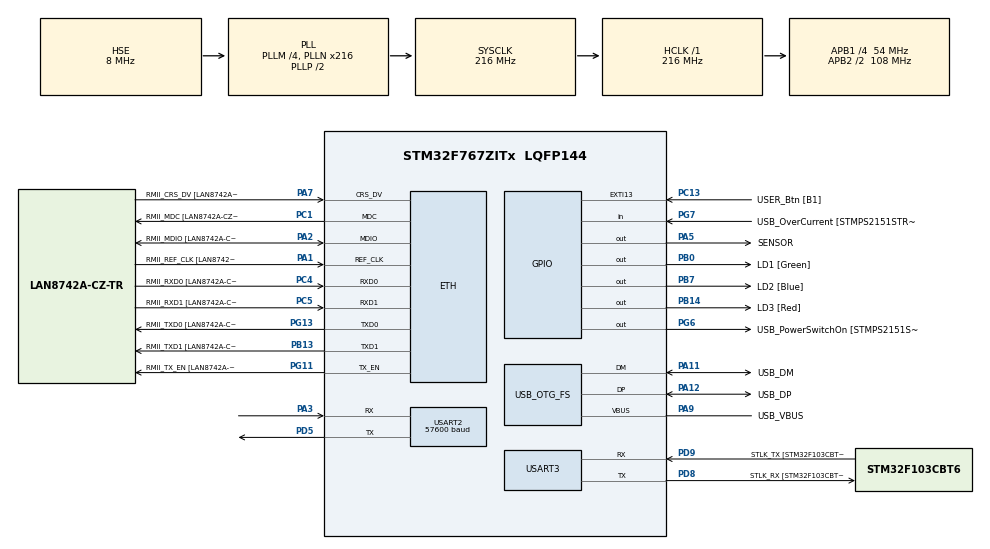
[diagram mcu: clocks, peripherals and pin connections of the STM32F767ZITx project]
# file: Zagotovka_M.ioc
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CORTEX_M7.AccessPermission-Cortex_Memory_Protection_Unit_Region0_Settings=MPU_REGION_FULL_ACCESS
CORTEX_M7.BaseAddress-Cortex_Memory_Protection_Unit_Region0_Settings=0x20000000
CORTEX_M7.CPU_DCache=Enabled
CORTEX_M7.CPU_ICache=Enabled
CORTEX_M7.DisableExec-Cortex_Memory_Protection_Unit_Region0_Settings=MPU_INSTRUCTION_ACCESS_DISABLE
CORTEX_M7.Enable-Cortex_Memory_Protection_Unit_Region0_Settings=MPU_REGION_ENABLE
CORTEX_M7.IsShareable-Cortex_Memory_Protection_Unit_Region0_Settings=MPU_ACCESS_NOT_SHAREABLE
CORTEX_M7.MPU_Control=MPU_PRIVILEGED_DEFAULT
CORTEX_M7.Size-Cortex_Memory_Protection_Unit_Region0_Settings=MPU_REGION_SIZE_512KB
CORTEX_M7.TypeExtField-Cortex_Memory_Protection_Unit_Region0_Settings=MPU_TEX_LEVEL1
ETH.MediaInterface=HAL_ETH_RMII_MODE
ETH.PHY_Name=LAN8742A_PHY_ADDRESS
ETH.PHY_Value=0
ETH.PhyAddress=0
FATFS._MAX_SS=4096
FREERTOS.Mutexes01=actionMutexHandle,Dynamic,NULL;s_mysett_mutex,Dynamic,NULL
FREERTOS.Queues01=outputQueue,64,struct data_pin_t,0,Dynamic,NULL,NULL;usbQueue,16,uint8_t,0,Dynamic,NULL,NULL;mqttQueue,32,MqttMessage_t,0,Dynamic,NULL,NULL;mqttRxQueue,32,MqttRxMsg_t,0,Dynamic,NULL,NULL;zbeeCmdQueue,64,ZbeeCmdMsg_t,0,Dynamic,NULL,NULL
FREERTOS.Tasks01=ConfigTask,24,768,StartConfigTask,Default,NULL,Dynamic,NULL,NULL;OutputTask,24,512,StartOutputTask,Default,NULL,Dynamic,NULL,NULL;CronTask,24,512,StartCronTask,Default,NULL,Dynamic,NULL,NULL;InputTask,24,512,StartInputTask,Default,NULL,Dynamic,NULL,NULL;EncoderTask,24,512,StartEncoderTask,Default,NULL,Dynamic,NULL,NULL;ds18b20Task,32,768,StartDs18b20Task,Default,NULL,Dynamic,NULL,NULL;dht22Task,24,512,StartDht22Task,Default,NULL,Dynamic,NULL,NULL;ServiceTask,24,1024,StartServiceTask,Default,NULL,Dynamic,NULL,NULL;SIM800LTask,24,1024,StartSIM800LTask,Default,NULL,Dynamic,NULL,NULL;SecurityTask,24,1024,StartSecurityTask,Default,NULL,Dynamic,NULL,NULL;PIDTask,24,1024,StartPIDTask,Default,NULL,Dynamic,NULL,NULL;my_DgnTask,24,768,StartDgnTask,Default,NULL,Dynamic,NULL,NULL;LoggerTask,16,512,StartLoggerTask,Default,NULL,Dynamic,NULL,NULL
FREERTOS.configTOTAL_HEAP_SIZE=192512
FREERTOS.configUSE_NEWLIB_REENTRANT=1
Mcu.Family=STM32F7
Mcu.Name=STM32F767ZITx
Mcu.Package=LQFP144
NVIC.ETH_IRQn=true\:5\:0\:false\:false\:true\:true\:true\:true\:true
NVIC.OTG_FS_IRQn=true\:5\:0\:false\:false\:true\:true\:true\:true\:true
NVIC.PriorityGroup=NVIC_PRIORITYGROUP_4
NVIC.TIM6_DAC_IRQn=true\:15\:0\:false\:false\:true\:false\:false\:true\:true
NVIC.TimeBase=TIM6_DAC_IRQn
NVIC.TimeBaseIP=TIM6
NVIC.USART2_IRQn=true\:5\:0\:false\:false\:true\:true\:true\:true\:true
PA1.GPIO_Label=RMII_REF_CLK [LAN8742A-CZ-TR_REFCLK0]
PA1.Mode=RMII
PA1.Signal=ETH_REF_CLK
PA10.GPIO_Label=USB_ID
PA10.Signal=USB_OTG_FS_ID
PA11.GPIO_Label=USB_DM
PA11.Mode=Host_Only
PA11.Signal=USB_OTG_FS_DM
PA12.GPIO_Label=USB_DP
PA12.Mode=Host_Only
PA12.Signal=USB_OTG_FS_DP
PA13.GPIO_Label=TMS
PA13.Mode=Trace_Asynchronous_SW
PA13.Signal=SYS_JTMS-SWDIO
PA14.GPIO_Label=TCK
PA14.Mode=Trace_Asynchronous_SW
PA14.Signal=SYS_JTCK-SWCLK
PA2.GPIO_Label=RMII_MDIO [LAN8742A-CZ-TR_MDIO]
PA2.Mode=RMII
PA2.Signal=ETH_MDIO
PA3.Mode=Asynchronous
PA3.Signal=USART2_RX
PA5.GPIO_Label=SENSOR
PA5.Signal=GPIO_Output
PA7.GPIO_Label=RMII_CRS_DV [LAN8742A-CZ-TR_CRS_DV]
PA7.Mode=RMII
PA7.Signal=ETH_CRS_DV
PA8.GPIO_Label=USB_SOF [TP1]
PA8.Signal=USB_OTG_FS_SOF
PA9.GPIO_Label=USB_VBUS
PA9.Mode=Activate_VBUS
PA9.Signal=USB_OTG_FS_VBUS
PB0.GPIO_Label=LD1 [Green]
PB0.Signal=GPIO_Output
PB13.GPIO_Label=RMII_TXD1 [LAN8742A-CZ-TR_TXD1]
PB13.Mode=RMII
PB13.Signal=ETH_TXD1
PB14.GPIO_Label=LD3 [Red]
PB14.Signal=GPIO_Output
PB3.GPIO_Label=SWO
PB3.Mode=Trace_Asynchronous_SW
PB3.Signal=SYS_JTDO-SWO
PB7.GPIO_Label=LD2 [Blue]
PB7.Signal=GPIO_Output
PC1.GPIO_Label=RMII_MDC [LAN8742A-CZ-TR_MDC]
PC1.Mode=RMII
PC1.Signal=ETH_MDC
PC13.GPIO_Label=USER_Btn [B1]
PC13.Signal=GPXTI13
PC14/OSC32_IN.Mode=LSE-External-Oscillator
PC14/OSC32_IN.Signal=RCC_OSC32_IN
PC15/OSC32_OUT.Mode=LSE-External-Oscillator
PC15/OSC32_OUT.Signal=RCC_OSC32_OUT
PC4.GPIO_Label=RMII_RXD0 [LAN8742A-CZ-TR_RXD0]
PC4.Mode=RMII
PC4.Signal=ETH_RXD0
PC5.GPIO_Label=RMII_RXD1 [LAN8742A-CZ-TR_RXD1]
PC5.Mode=RMII
PC5.Signal=ETH_RXD1
PD5.Mode=Asynchronous
PD5.Signal=USART2_TX
PD8.GPIO_Label=STLK_RX [STM32F103CBT6_PA3]
PD8.Mode=Asynchronous
PD8.Signal=USART3_TX
PD9.GPIO_Label=STLK_TX [STM32F103CBT6_PA2]
PD9.Mode=Asynchronous
PD9.Signal=USART3_RX
PG11.GPIO_Label=RMII_TX_EN [LAN8742A-CZ-TR_TXEN]
PG11.Mode=RMII
PG11.Signal=ETH_TX_EN
PG13.GPIO_Label=RMII_TXD0 [LAN8742A-CZ-TR_TXD0]
PG13.Mode=RMII
PG13.Signal=ETH_TXD0
PG6.GPIO_Label=USB_PowerSwitchOn [STMPS2151STR_EN]
PG6.Signal=GPIO_Output
PG7.GPIO_Label=USB_OverCurrent [STMPS2151STR_FAULT]
PG7.Signal=GPIO_Input
PH0/OSC_IN.GPIO_Label=MCO [STM32F103CBT6_PA8]
PH0/OSC_IN.Mode=HSE-External-Clock-Source
PH0/OSC_IN.Signal=RCC_OSC_IN
PH1/OSC_OUT.Mode=HSE-External-Clock-Source
PH1/OSC_OUT.Signal=RCC_OSC_OUT
ProjectManager.HeapSize=0x1000
ProjectManager.StackSize=0x800
ProjectManager.TargetToolchain=STM32CubeIDE
RCC.48MHZClocksFreq_Value=24000000
RCC.AHBFreq_Value=216000000
RCC.APB1CLKDivider=RCC_HCLK_DIV4
RCC.APB1Freq_Value=54000000
RCC.APB1TimFreq_Value=108000000
RCC.APB2CLKDivider=RCC_HCLK_DIV2
RCC.APB2Freq_Value=108000000
RCC.APB2TimFreq_Value=216000000
RCC.CortexFreq_Value=216000000
RCC.HCLKFreq_Value=216000000
RCC.HSE_VALUE=8000000
RCC.HSI_VALUE=16000000
RCC.PLLM=4
RCC.PLLMUL=RCC_PLL_MUL9
RCC.PLLN=216
RCC.PLLQ=9
RCC.PRESCALERUSB=RCC_USBCLKSOURCE_PLL_DIV1_5
RCC.SYSCLKFreq_VALUE=216000000
RCC.SYSCLKSource=RCC_SYSCLKSOURCE_PLLCLK
RCC.SYSCLKSourceVirtual=RCC_SYSCLKSOURCE_PLLCLK
RCC.USBFreq_Value=48000000
RCC.VCOOutputFreq_Value=432000000
TIM1.Prescaler=216-1
USART2.BaudRate=57600
USART2.VirtualMode-Asynchronous=VM_ASYNC
USART3.VirtualMode-Asynchronous=VM_ASYNC
USB_HOST.BSP.number=1
USB_HOST.USBH_HandleTypeDef-MSC_FS=hUsbHostFS
USB_HOST.USBH_PROCESS_STACK_SIZE-MSC_FS=8*128
USB_HOST.VirtualModeFS=Msc
USB_HOST0.BSP.STBoard=false
USB_HOST0.BSP.api=Unknown
USB_HOST0.BSP.condition=SW_VBUS_DRIVE_MSC_FS \= false
USB_HOST0.BSP.instance=PG6
USB_HOST0.BSP.ip=GPIO
USB_HOST0.BSP.mode=Output
USB_HOST0.BSP.name=Drive_VBUS_FS
USB_HOST0.BSP.solution=PG6
USB_OTG_FS.VirtualMode=Host_Only
USB_OTG_FS.phy_itface=HCD_PHY_EMBEDDED
VP_CRC_VS_CRC.Mode=CRC_Activate
VP_FATFS_VS_USB.Mode=USB
VP_FREERTOS_VS_CMSIS_V2.Mode=CMSIS_V2
VP_RNG_VS_RNG.Mode=RNG_Activate
VP_SYS_VS_tim6.Mode=TIM6
VP_TIM1_VS_ClockSourceINT.Mode=Internal
VP_USB_HOST_VS_USB_HOST_MSC_FS.Mode=MSC_FS
board=NUCLEO-F767ZI

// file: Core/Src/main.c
/* USER CODE BEGIN Header */
/**
 ******************************************************************************
 * @file           : main.c
 * @brief          : Main program body
 ******************************************************************************
 * @attention
 *
 * Copyright (c) 2024 STMicroelectronics.
 * All rights reserved.
 *
 * This software is licensed under terms that can be found in the LICENSE file
 * in the root directory of this software component.
 * If no LICENSE file comes with this software, it is provided AS-IS.
 *
 ******************************************************************************
 */
/* USER CODE END Header */
#include "main.h"
#include "string.h"
#include "cmsis_os.h"
#include "fatfs.h"
#include "usb_host.h"

/* USER CODE BEGIN Includes */
#include "db.h"
#include "hal.h"
#include "mongoose.h"
#include "multi_button.h"
#include "net.h"
#include "net_limits.h"  /* g_net_syn_drops / g_net_rejects */
#include "setings.h"
#include "logger.h"
#include "ds18b20.h"
#include "ds18b20Config.h"
#include "lwdtc.h"
#include "mongoose.h"
#include "stdio.h"
#include "zagotovka.h"
#include <inttypes.h> // Для поддержки PRIuPTR
#include <math.h>
#include <string.h>
#include <time.h>

#include "gsm.h"
#include "usart_ring.h"
#include "dtcm_alloc.h"
#include "mqtt_server.h"
#include "ha_discovery.h"
#include "slzb_watchdog.h"
#include "cond_eval.h" /* Дополнительные условия срабатывания действий */

#define BLINK_PERIOD_MS 1000 // LED blinking period in millis
#define DEBOUNCE_DELAY 45    // Encoder (ms)

#define PI 3.14159265358979323846
#define ZENITH -.83 // Средняя атмосферная рефракция.

extern OneWire_t OneWire;
extern uint8_t OneWireDevices;
extern uint8_t temp_cnt;
extern uint8_t Ds18b20StartConvert;
extern uint16_t Ds18b20Timeout;
extern uint64_t s_boot_timestamp;
int32_t onoffid;  /* знаковый: JSON id может быть < 0 */
extern onewire_config_t *ow_conf;  /* выделяется в DTCM в zagotovka_dtcm_init() */
struct Button *button = NULL;      /* выделяется в DTCM через dtcm_button (main) */
extern volatile uint8_t onlineFlg;
extern uint8_t *gsm_rx_buffer;
extern volatile gsm_rx_buffer_index_t gsm_rx_buffer_head;
extern uint8_t _sitcm[], _eitcm[];
extern uint32_t _sitcm_load[];
uint8_t RxByte; // Буфер для приема одного байта по UART

uint8_t owflag = 0;

ds18b20_pin_t ds18b20[MAX_DS18B20_P];
dht22_pin_t *dht22 = NULL;         /* выделяется в DTCM через dtcm_dht22 (main) */

/* A4: global mqttMsg removed — each send site uses a local copy */
/* mqtt_topic[100] / mqtt_payload[300] теперь локальны в WebServerTask */
/* USER CODE END Includes */

/* USER CODE BEGIN PTD */
TIM_HandleTypeDef *htim = NULL;  /* выделяется в DTCM через dtcm_htim (main) */
uint8_t usbnum = 0;
uint8_t mqttnum = 0;
uint8_t sumowpin = 0;
/* A3: global data_pin removed — each producer/consumer uses a local copy */
dbPidConf *PidConf = NULL;  /* выделяется в DTCM через dtcm_pid_conf */

#define HTTP_URL "http://0.0.0.0:8000"
#define HTTPS_URL "https://0.0.0.0:8443"
/* USER CODE END PTD */

/* USER CODE BEGIN PM */
// Cron variable — копия struct tm, а не указатель на static buffer localtime()
struct tm timez_copy;
time_t cronetime;
time_t cronetime_old;
time_t moontime = (time_t)-1;
int year;
uint8_t month; // 1-12
uint8_t day;   // 1-31
char g_ip_addr[16] = "0.0.0.0";
char g_mac_addr[18] = "00:00:00:00:00:00";
/* USER CODE END PM */

#if defined ( __ICCARM__ ) /*!< IAR Compiler */
#pragma location=0x2007c000
ETH_DMADescTypeDef  DMARxDscrTab[ETH_RX_DESC_CNT]; /* Ethernet Rx DMA Descriptors */
#pragma location=0x2007c0a0
ETH_DMADescTypeDef  DMATxDscrTab[ETH_TX_DESC_CNT]; /* Ethernet Tx DMA Descriptors */

#elif defined ( __CC_ARM )  /* MDK ARM Compiler */

__attribute__((at(0x2007c000))) ETH_DMADescTypeDef  DMARxDscrTab[ETH_RX_DESC_CNT]; /* Ethernet Rx DMA Descriptors */
__attribute__((at(0x2007c0a0))) ETH_DMADescTypeDef  DMATxDscrTab[ETH_TX_DESC_CNT]; /* Ethernet Tx DMA Descriptors */

#elif defined ( __GNUC__ ) /* GNU Compiler */

ETH_DMADescTypeDef DMARxDscrTab[ETH_RX_DESC_CNT] __attribute__((section(".RxDecripSection"))); /* Ethernet Rx DMA Descriptors */
ETH_DMADescTypeDef DMATxDscrTab[ETH_TX_DESC_CNT] __attribute__((section(".TxDecripSection")));   /* Ethernet Tx DMA Descriptors */
#endif

ETH_TxPacketConfig TxConfig;

CRC_HandleTypeDef hcrc;

ETH_HandleTypeDef heth;

RNG_HandleTypeDef hrng;

TIM_HandleTypeDef htim1;

UART_HandleTypeDef huart2;
UART_HandleTypeDef huart3;

/* Definitions for ConfigTask */
osThreadId_t ConfigTaskHandle;
const osThreadAttr_t ConfigTask_attributes = {
  .name = "ConfigTask",
  .stack_size = 768 * 4,
  .priority = (osPriority_t) osPriorityNormal,
};
/* Definitions for OutputTask */
osThreadId_t OutputTaskHandle;
const osThreadAttr_t OutputTask_attributes = {
  .name = "OutputTask",
  .stack_size = 512 * 4,
  .priority = (osPriority_t) osPriorityNormal,
};
/* Definitions for CronTask */
osThreadId_t CronTaskHandle;
const osThreadAttr_t CronTask_attributes = {
  .name = "CronTask",
  .stack_size = 512 * 4,
  .priority = (osPriority_t) osPriorityNormal,
};
/* Definitions for InputTask */
osThreadId_t InputTaskHandle;
const osThreadAttr_t InputTask_attributes = {
  .name = "InputTask",
  .stack_size = 512 * 4,
  .priority = (osPriority_t) osPriorityNormal,
};
/* Definitions for EncoderTask */
osThreadId_t EncoderTaskHandle;
const osThreadAttr_t EncoderTask_attributes = {
  .name = "EncoderTask",
  .stack_size = 512 * 4,
  .priority = (osPriority_t) osPriorityNormal,
};
/* Definitions for ds18b20Task */
osThreadId_t ds18b20TaskHandle;
const osThreadAttr_t ds18b20Task_attributes = {
  .name = "ds18b20Task",
  .stack_size = 768 * 4,
  .priority = (osPriority_t) osPriorityAboveNormal,
};
/* Definitions for dht22Task */
osThreadId_t dht22TaskHandle;
const osThreadAttr_t dht22Task_attributes = {
  .name = "dht22Task",
  .stack_size = 512 * 4,
  .priority = (osPriority_t) osPriorityNormal,
};
/* Definitions for ServiceTask */
osThreadId_t ServiceTaskHandle;
const osThreadAttr_t ServiceTask_attributes = {
  .name = "ServiceTask",
  .stack_size = 1024 * 4,
  .priority = (osPriority_t) osPriorityNormal,
};
/* Definitions for SIM800LTask */
osThreadId_t SIM800LTaskHandle;
const osThreadAttr_t SIM800LTask_attributes = {
  .name = "SIM800LTask",
  .stack_size = 1024 * 4,
  .priority = (osPriority_t) osPriorityNormal,
};
/* Definitions for SecurityTask */
osThreadId_t SecurityTaskHandle;
const osThreadAttr_t SecurityTask_attributes = {
  .name = "SecurityTask",
  .stack_size = 1024 * 4,
  .priority = (osPriority_t) osPriorityNormal,
};
/* Definitions for PIDTask */
osThreadId_t PIDTaskHandle;
const osThreadAttr_t PIDTask_attributes = {
  .name = "PIDTask",
  .stack_size = 1024 * 4,
  .priority = (osPriority_t) osPriorityNormal,
};
/* Definitions for my_DgnTask */
osThreadId_t my_DgnTaskHandle;
const osThreadAttr_t my_DgnTask_attributes = {
  .name = "my_DgnTask",
  .stack_size = 768 * 4,
  .priority = (osPriority_t) osPriorityNormal,
};
/* Definitions for LoggerTask */
osThreadId_t LoggerTaskHandle;
const osThreadAttr_t LoggerTask_attributes = {
  .name = "LoggerTask",
  .stack_size = 512 * 4,
  .priority = (osPriority_t) osPriorityBelowNormal,
};
/* Definitions for outputQueue */
osMessageQueueId_t outputQueueHandle;
const osMessageQueueAttr_t outputQueue_attributes = {
  .name = "outputQueue"
};
/* Definitions for usbQueue */
osMessageQueueId_t usbQueueHandle;
const osMessageQueueAttr_t usbQueue_attributes = {
  .name = "usbQueue"
};
/* Definitions for mqttQueue */
osMessageQueueId_t mqttQueueHandle;
const osMessageQueueAttr_t mqttQueue_attributes = {
  .name = "mqttQueue"
};
/* Definitions for mqttRxQueue */
osMessageQueueId_t mqttRxQueueHandle;
const osMessageQueueAttr_t mqttRxQueue_attributes = {
  .name = "mqttRxQueue"
};
/* Definitions for zbeeCmdQueue */
osMessageQueueId_t zbeeCmdQueueHandle;
const osMessageQueueAttr_t zbeeCmdQueue_attributes = {
  .name = "zbeeCmdQueue"
};
/* Definitions for actionMutexHandle */
osMutexId_t actionMutexHandleHandle;
const osMutexAttr_t actionMutexHandle_attributes = {
  .name = "actionMutexHandle"
};
/* Definitions for s_mysett_mutex */
osMutexId_t s_mysett_mutexHandle;
const osMutexAttr_t s_mysett_mutex_attributes = {
  .name = "s_mysett_mutex"
};
/* USER CODE BEGIN PV */
extern struct dbSettings SetSettings;
extern struct dbCron dbCrontxt[NUMTASK];
extern struct dbPinsConf PinsConf[NUMPIN];
extern struct dbPinsInfo PinsInfo[NUMPIN];
extern struct dbPinToPin *PinsLinks;  /* выделяется в DTCM через dtcm_pinslinks (main) */
extern bool g_log_filter_from_file;  // Флаг: log_filter_mask был в settings.ini

extern ApplicationTypeDef Appli_state;

/* Колбэк программного таймера индикации USB на LD3: тик 100 мс,
 * таймер создаётся в MX (секция RTOS_TIMERS), т.к. CubeMX-таймеров
 * в проекте нет. Реализация периода — usb_led_tick_100ms (zagotovka.c). */
static void usb_led_timer_cb(void *arg) { (void)arg; usb_led_tick_100ms(); }

/* Глобальные переменные мониторинга пиков и ошибок */
volatile uint32_t malloc_fail_count = 0;
static uint32_t mqtt_tx_peak = 0;
static uint32_t mqtt_rx_peak = 0;
static uint32_t output_peak = 0;
static uint32_t usb_peak = 0;
static uint32_t zbee_cmd_peak = 0;
static uint32_t mg_conn_peak = 0;

/* Runtime arrays for SecurityTask — выделяются в DTCM через dtcm_sec_deb_tm/dtcm_sec_lasttrg */
#define sec_deb_tm  dtcm_sec_deb_tm
#define sec_lasttrg dtcm_sec_lasttrg
static uint32_t mg_conn_cur = 0;
static uint32_t mg_conn_listeners = 0;
static uint32_t mg_conn_tls = 0;
static uint32_t mg_conn_mqtt = 0;
static uint32_t mg_conn_mqttsrv = 0; // клиенты встроенного MQTT-брокера
static uint32_t mg_conn_other = 0;

/* OTHER без клиентов встроенного брокера: HTTP, DNS, NTP и т.п. */
static inline unsigned long mg_conn_other_pure(void) {
  return (mg_conn_other > mg_conn_mqttsrv) ? (mg_conn_other - mg_conn_mqttsrv) : 0;
}

static unsigned long s_other_ids[8] = {0};
static uint32_t s_other_cnt = 0;
static uint32_t mg_poll_gap_peak = 0;
volatile uint32_t mg_poll_gap_over_50ms_cnt = 0;

/* Счётчики HTTP запросов */
volatile uint32_t req_total = 0;
volatile uint32_t req_encoder = 0;
volatile uint32_t req_api = 0;

osThreadId_t WebServerTaskHandle;
const osThreadAttr_t WebServerTask_attributes = {
  .name = "WebServerTask",
  .stack_size = 4608 * 4,
  .priority = (osPriority_t) osPriorityAboveNormal,
};

/* USER CODE END PV */

void SystemClock_Config(void);
static void MPU_Config(void);
static void MX_GPIO_Init(void);
static void MX_ETH_Init(void);
static void MX_USART3_UART_Init(void);
static void MX_RNG_Init(void);
static void MX_TIM1_Init(void);
static void MX_USART2_UART_Init(void);
static void MX_CRC_Init(void);
void StartConfigTask(void *argument);
void StartOutputTask(void *argument);
void StartCronTask(void *argument);
void StartInputTask(void *argument);
void StartEncoderTask(void *argument);
void StartDs18b20Task(void *argument);
void StartDht22Task(void *argument);
void StartServiceTask(void *argument);
void StartSIM800LTask(void *argument);
void StartSecurityTask(void *argument);
void StartPIDTask(void *argument);
void StartDgnTask(void *argument);
void StartLoggerTask(void *argument);

/* USER CODE BEGIN PFP */
void StartWebServerTask(void *argument);
/* USER CODE END PFP */

/* USER CODE BEGIN 0 */
/*********************** для printf ******************************/
#ifdef __GNUC__
/* With GCC/RAISONANCE, small printf (option LD Linker->Libraries->Small printf
 * set to 'Yes') calls __io_putchar() */
#define PUTCHAR_PROTOTYPE int __io_putchar(int ch)
#else
#define PUTCHAR_PROTOTYPE int fputc(int ch, FILE *f)
#endif /* __GNUC__ */
/*********************** M ******************************/
#define LAN8742A_PHY_ADDRESS 0x00
#define LAN8742A_BSR 0x01
#define LAN8742A_BSR_LINK_STATUS 0x0004
#define LAN8742A_BSR_AUTONEGO_COMPLETE 0x0020

static bool quick_network_check(void) {
  uint32_t phyreg;
  uint32_t retry_count = 3;

  while (retry_count--) {
    // Чтение Basic Status Register (BSR)
    HAL_ETH_ReadPHYRegister(&heth, LAN8742A_PHY_ADDRESS, LAN8742A_BSR, &phyreg);

    if ((phyreg & LAN8742A_BSR_LINK_STATUS) &&
        (phyreg & LAN8742A_BSR_AUTONEGO_COMPLETE)) {
      return true;
    }
    osDelay(10);
  }
  return false;
}

const char *s_sub_topic = SetSettings.rxmqttop; // Rx topic

bool mg_random(void *buf, size_t len) { // Use on-board RNG
  extern RNG_HandleTypeDef hrng;
  for (size_t n = 0; n < len; n += sizeof(uint32_t)) {
    uint32_t r;
    HAL_RNG_GenerateRandomNumber(&hrng, &r);
    memcpy((char *)buf + n, &r, n + sizeof(r) > len ? len - n : sizeof(r));
  }
  return true;
}

uint64_t mg_millis(void) {
    // Proper 64-bit extension of 32-bit HAL_GetTick.
    // HAL_GetTick wraps at ~49.7 days; we track wraps in a 64-bit accumulator.
    // Called frequently enough (every mg_mgr_poll) to never miss a wrap.
    // Protected by critical section: called from CronTask (Normal) and
    // WebServerTask/Mongoose (AboveNormal) — without protection, preemption
    // between read and write of last_tick/ms64 causes time jumps.
//	uint32_t t_enter = HAL_GetTick();  // или DWT->CYCCNT для мкс точности
    static uint32_t last_tick;
    static uint64_t ms64;
    taskENTER_CRITICAL();
    uint32_t now = HAL_GetTick();
    uint32_t delta = now - last_tick;  // Safe modulo-2^32 subtraction
    ms64 += delta;
    last_tick = now;
    uint64_t result = ms64;
//    uint32_t t_exit = HAL_GetTick();
    taskEXIT_CRITICAL();
//    if (t_exit != t_enter) {
//        printf("[WARN] CronTask critical section held %lu ms!\n", t_exit - t_enter);
//    }
    return result;
}

/*
 Порядок у меня правильный:
    Сначала происходит MG_EV_ACCEPT - принятие TCP соединения
    В этом обработчике выполняется mg_tls_init()
    После этого может начаться TLS рукопожатие (событие MG_EV_TLS_HS)
 * */

volatile uint32_t mqtt_sent_count = 0;

static bool check_mqtt_connection(void *conn);

void send_mqtt_message(struct mg_connection *conn, const char *topic,
                       const char *msg) {
  char full_topic[128]; // Буфер для полного топика
  snprintf(full_topic, sizeof(full_topic), "%s%s", get_mqtt_topic(), topic);

  /* События кнопок и охраны дублируются как триггеры Home Assistant в <tx>/ev */
  ha_observe(conn, topic, msg);

  /* Локальный MQTT-сервер: fan-out независимо от состояния внешнего брокера */
  mqtt_server_publish(full_topic, msg);

  if (!check_mqtt_connection(conn)) {
    return;
  }

  /* Защита от переполнения send-буфера при зависшем TCP соединении.
   * Если брокер перестал ACK-ить пакеты, conn->send растёт бесконечно
   * и через ~2 часа исчерпывает FreeRTOS heap → deadlock.
   * Порог 4096 = ~20-40 сообщений в буфере. */
  if (conn->send.len > 4096) {
    static uint32_t last_err_tick = 0;
    if (mg_millis() - last_err_tick > 5000) {
      MG_ERROR(("MQTT send buf overflow (%lu), draining", (unsigned long)conn->send.len));
      last_err_tick = mg_millis();
    }
    conn->is_draining = 1;
    return;
  }

  struct mg_mqtt_opts pub_opts;
  memset(&pub_opts, 0, sizeof(pub_opts));
  pub_opts.topic = mg_str(full_topic);
  pub_opts.message = mg_str(msg);
  pub_opts.qos = s_qos;
  pub_opts.retain = false;
  mg_mqtt_pub(conn, &pub_opts);
  taskENTER_CRITICAL();
  mqtt_sent_count++;
  taskEXIT_CRITICAL();

  /* Диагностика длины JSON-сообщения */
  size_t msg_len = strlen(msg);
  if (msg_len > 256) {
    printf("[MQTT] Large publish len=%d on topic %s\r\n", (int)msg_len, full_topic);
  }

  // printf("[MQTT] %lu PUBLISHED %s -> %.*s\r\n", conn->id, msg, (int)pub_opts.topic.len,
  //         pub_opts.topic.buf);
}
/* Публикация в произвольный топик. Локальный брокер: fan-out (retain там не хранится
 * для больших payload, при подписке HA конфиги публикуются заново). Внешний: retain как задан. */
void send_mqtt_raw(struct mg_connection *conn, const char *full_topic, const char *msg, bool retain) {
  struct mg_mqtt_opts o;
  mqtt_server_publish(full_topic, msg);
  if (!check_mqtt_connection(conn)) return;
  if (conn->send.len > 4096) return;
  memset(&o, 0, sizeof(o));
  o.topic = mg_str(full_topic);
  o.message = mg_str(msg);
  o.qos = s_qos;
  o.retain = retain;
  mg_mqtt_pub(conn, &o);
}
/*********************** End M ******************************/

#ifdef __GNUC__
/* With GCC/RAISONANCE, small MG_INFO (option LD Linker->Libraries->Small
 * MG_INFO set to 'Yes') calls __io_putchar() */
#define PUTCHAR_PROTOTYPE int __io_putchar(int ch)
#else
#define PUTCHAR_PROTOTYPE int fputc(int ch, FILE *f)
#endif /* __GNUC__ */

unsigned long Ti;
unsigned long Te;

static bool check_mqtt_connection(void *conn) {
  struct mg_connection *c = (struct mg_connection *)conn;
  extern volatile bool mqtt_connected_reported;
  if (c == NULL || c->is_closing || c->is_draining || !mqtt_connected_reported) {
    return false;
  }
  return true;
}

static inline bool is_action_set(const char *action) {
  return action && action[0] != '\0' && strcmp(action, "None") != 0;
}

void button_event_handler(
    Button *handle) { // Функция callback для обработки событий кнопки
  if (handle->button_id >= NUMPIN) {
    return;
  }
  /* Master Enable: onoff == 0 - кнопка отключена, никакая логика
   * (действия, SMS, MQTT-события) для этого ID не выполняется. */
  if (PinsConf[handle->button_id].onoff == 0) {
    return;
  }
  // Обработчик событий кнопки
  PressEvent event = get_button_event(handle);

  switch (event) {
  case NONE_PRESS: // Нет нажатия
    break;
  case PRESS_DOWN: // Кнопка нажата
    //       printf("Button %d: PRESS_DOWN!\r\n", handle->button_id);
    break;
  case PRESS_UP: // Кнопка отпущена
                 // printf("Button %d: PRESS_UP!\r\n", handle->button_id);
    break;
  case LONG_PRESS_START: // Начало долгого нажатия
    if (is_action_set(PinsConf[handle->button_id].lpress)) {
      LOG_SYSTEM("[LONG PRESS] Button %d: %s", PinIdFromIdx(handle->button_id), PinsConf[handle->button_id].lpress);
      action_handler((uint16_t)(handle->button_id + 1), PinsConf[handle->button_id].lpress,
                     "long press");
      mqtt_queue_send_safe(3, handle->button_id, 1, 0);
    }
    break;
  case LONG_PRESS_HOLD: // Продолжение долгого нажатия
    //       printf("Button %d: LONG_PRESS_HOLD!\r\n", PinIdFromIdx(handle->button_id));
    break;
  case SINGLE_CLICK: // Одиночное нажатие кнопки
    if (is_action_set(PinsConf[handle->button_id].sclick)) {
      LOG_SYSTEM("[SINGLE CLICK] Button %d: %s", PinIdFromIdx(handle->button_id), PinsConf[handle->button_id].sclick);
      action_handler((uint16_t)(handle->button_id + 1), PinsConf[handle->button_id].sclick,
                     "sclick press");
      mqtt_queue_send_safe(4, handle->button_id, 2, 0);
    }
    break;
  case DOUBLE_CLICK: // Двойное нажатие кнопки
    if (is_action_set(PinsConf[handle->button_id].dclick)) {
      LOG_SYSTEM("[DOUBLE CLICK] Button %d: %s", PinIdFromIdx(handle->button_id), PinsConf[handle->button_id].dclick);
      action_handler((uint16_t)(handle->button_id + 1), PinsConf[handle->button_id].dclick,
                     "double press");
      mqtt_queue_send_safe(5, handle->button_id, 3, 0);
    }
    break;
  case PRESS_REPEAT: // Повторное нажатие кнопки
    printf("Button %d: PRESS_REPEAT!\r\n", PinIdFromIdx(handle->button_id));
    break;
  default:
    // Обработка неизвестного значения event
    break;
  }
}

void pwm_event_handler(Button *handle) {
  // Обработчик событий кнопки
  PressEvent event = get_button_event(handle);

  int i = 0;

  switch (event) {
  case NONE_PRESS: // Нет нажатия
    break;
  case PRESS_DOWN: // Кнопка нажата
    //              printf("Button %d: PRESS_DOWN!\r\n", handle->button_id);
    break;
  case PRESS_UP: // Кнопка отпущена
    //              printf("Button %d: PRESS_UP!\r\n", handle->button_id);
    break;
  case LONG_PRESS_START: // Начало долгого нажатия
    printf("Button %d: LONG_PRESS_START!\r\n", PinIdFromIdx(handle->button_id));
    break;
  case LONG_PRESS_HOLD:
    //	  if(PinsConf[handle->button_id].sclick == 2){
    for (int a = 0; a < NUMPINLINKS; a++) {
      if (PinsLinks[a].idin == (short)(handle->button_id + 1)) {
        // PinsInfo[i].tim->CCR1 = 50;
        //  PWM
        int out_id = PinsLinks[a].idout;
        if (out_id < 1 || out_id > NUMPIN) continue; /* Zigbee/мусор — не PWM */
        i = out_id - 1;
        if (PinsConf[i].topin == 5) {
          if (is_pin_in_autotune(i)) break; /* AutoTune lock */
          // dvalue - ПРОЦЕНТ 0-100, step = 1%
          if (PinsConf[handle->button_id].on == 1) {
            taskENTER_CRITICAL();
            PinsConf[i].dvalue += 1;
            if (PinsConf[i].dvalue > 100)
              PinsConf[i].dvalue = 100;
            taskEXIT_CRITICAL();
          }
          if (PinsConf[handle->button_id].on == 0) {
            taskENTER_CRITICAL();
            PinsConf[i].dvalue -= 1;
            if (PinsConf[i].dvalue < 0)
              PinsConf[i].dvalue = 0;
            taskEXIT_CRITICAL();
          }
          uint32_t pulse_lh = (uint32_t)((uint64_t)PinsConf[i].dvalue *
                                         PinsConf[i].pwmmax / 100ULL);
          __HAL_TIM_SET_COMPARE(&htim[i], PinsInfo[i].tim_channel, pulse_lh);
          printf("PWM LONG [%d] %s: %d%% = %lu steps\r\n", PinIdFromIdx(i), PinsInfo[i].pins,
                 PinsConf[i].dvalue, (unsigned long)pulse_lh);
        }
        //						data_pin.id =
        // PinsLinks[a].idout;
        // data_pin.action = 2;
        // xQueueSend(outputQueueHandle, (void* ) &data_pin, 0);
        printf("Button %d: SINGLE_CLICK PWM pwmValue %d flag %d!\r\n",
               PinIdFromIdx(handle->button_id), PinsConf[i].dvalue,
               PinsConf[handle->button_id].on);
      }
      //				}
    }
    printf("Button %d: LONG_PRESS_HOLD!\r\n", PinIdFromIdx(handle->button_id));
    break;
  case SINGLE_CLICK: // Одиночное нажатие кнопки
                     //	  if(PinsConf[handle->button_id].sclick == 2){
    for (int a = 0; a < NUMPINLINKS; a++) {
      if (PinsLinks[a].idin == (short)(handle->button_id + 1)) {
        // PinsInfo[i].tim->CCR1 = 50;
        // for (uint8_t i = 0; i < NUMPIN; i++) {
        //  PWM
        int out_id = PinsLinks[a].idout;
        if (out_id < 1 || out_id > NUMPIN) continue; /* Zigbee/мусор — не PWM */
        i = out_id - 1;
        if (PinsConf[i].topin == 5) {
          if (is_pin_in_autotune(i)) break; /* AutoTune lock */
          // dvalue - ПРОЦЕНТ 0-100, step = 1%
          if (PinsConf[handle->button_id].on == 1) {
            PinsConf[i].dvalue += 1;
            if (PinsConf[i].dvalue > 100) {
              PinsConf[i].dvalue = 100;
              PinsConf[handle->button_id].on = 0;
            }
          }
          if (PinsConf[handle->button_id].on == 0) {
            PinsConf[i].dvalue -= 1;
            if (PinsConf[i].dvalue < 0) {
              PinsConf[i].dvalue = 0;
              PinsConf[handle->button_id].on = 1;
            }
          }
          uint32_t pulse_sc = (uint32_t)((uint64_t)PinsConf[i].dvalue *
                                         PinsConf[i].pwmmax / 100ULL);
          __HAL_TIM_SET_COMPARE(&htim[i], PinsInfo[i].tim_channel, pulse_sc);
          printf("PWM CLICK [%d] %s: %d%% = %lu steps\r\n", PinIdFromIdx(i), PinsInfo[i].pins,
                 PinsConf[i].dvalue, (unsigned long)pulse_sc);
        }

        //						data_pin.id =
        // PinsLinks[a].idout;
        // data_pin.action = 2;
        // xQueueSend(outputQueueHandle, (void* ) &data_pin, 0);
        printf("Button %d: SINGLE_CLICK PWM pwmValue %d flag %d!\r\n",
               PinIdFromIdx(handle->button_id), PinsConf[i].dvalue,
               PinsConf[handle->button_id].on);
      }
    }
    //	  }
    // printf("Button %d: SINGLE_CLICK PWM!\r\n", handle->button_id);
    break;
  case DOUBLE_CLICK: // Двойное нажатие кнопки
    PinsConf[handle->button_id].on ^= 1;
    printf("Button %d: DOUBLE_CLICK PWM %d!\r\n", PinIdFromIdx(handle->button_id),
           PinsConf[handle->button_id].on);
    break;
  case PRESS_REPEAT: // Повторное нажатие кнопки
    printf("Button %d: PRESS_REPEAT PWM!\r\n", PinIdFromIdx(handle->button_id));
    break;
  default:
    // Обработка неизвестного значения event
    break;
  }
}

// Функция для получения состояния GPIO кнопки
uint8_t read_button_level(uint8_t button_id) {
  // Вернуть состояние GPIO пина, к которому подключена кнопка
  return HAL_GPIO_ReadPin(PinsInfo[button_id].gpio_name,
                          PinsInfo[button_id].hal_pin);
  // return GPIO_PIN_RESET; // Значение по умолчанию, если кнопка не найдена
}

/**************************** GSM ***************************************/
uint32_t zerg_t;  /* используется в gsm.c через extern */
uint32_t swarm_t; /* используется в gsm.c через extern */

/* OTA crash diagnostics: NOLOAD-переменные, переживают NVIC_SystemReset().
 * Перенесены из ITCM (.noinit_itcm) в SRAM (.noinit_ram), чтобы MPU мог
 * защитить весь ITCM как Read-Only и ловить дикие записи. */
__attribute__((section(".noinit_ram"))) uint32_t dtcm_ota_sector;
__attribute__((section(".noinit_ram"))) uint32_t dtcm_ota_magic;
__attribute__((section(".noinit_ram"))) uint32_t dtcm_ota_addr;
__attribute__((section(".noinit_ram"))) uint32_t dtcm_ota_sr_erase;    /* FLASH_SR after sector erase */
__attribute__((section(".noinit_ram"))) uint32_t dtcm_ota_cr_erase;    /* FLASH_CR written for erase */
__attribute__((section(".noinit_ram"))) uint32_t dtcm_ota_sr_write;    /* FLASH_SR after failed write */
__attribute__((section(".noinit_ram"))) uint32_t dtcm_ota_write_addr;  /* address of failed write */
__attribute__((section(".noinit_ram"))) uint32_t dtcm_ota_write_word;  /* word that failed to write */
__attribute__((section(".noinit_ram"))) uint32_t dtcm_ota_pre_erase0; /* first8 bytes before erase */

/* clear_string перенесена в gsm.c */
/* check_speed перенесена в gsm.c */
/*************************** END GSM ************************************/

/* Reset reason ---------------------------------------------------------*/
static uint32_t reset_csr_value = 0;
static char reset_reason_str[128] = "Unknown";

static void read_reset_reason(void) {
    reset_csr_value = RCC->CSR;
    __HAL_RCC_CLEAR_RESET_FLAGS();

    reset_reason_str[0] = '\0';
    size_t len = 0;

    if (reset_csr_value & RCC_CSR_PORRSTF) {
        len = strlen(reset_reason_str);
        snprintf(reset_reason_str + len, sizeof(reset_reason_str) - len, "POR ");
    }
    if (reset_csr_value & RCC_CSR_BORRSTF) {
        len = strlen(reset_reason_str);
        snprintf(reset_reason_str + len, sizeof(reset_reason_str) - len, "BOR ");
    }
    if (reset_csr_value & RCC_CSR_SFTRSTF) {
        len = strlen(reset_reason_str);
        snprintf(reset_reason_str + len, sizeof(reset_reason_str) - len, "SFTRST ");
    }
    if (reset_csr_value & RCC_CSR_IWDGRSTF) {
        len = strlen(reset_reason_str);
        snprintf(reset_reason_str + len, sizeof(reset_reason_str) - len, "IWDG ");
    }
    if (reset_csr_value & RCC_CSR_WWDGRSTF) {
        len = strlen(reset_reason_str);
        snprintf(reset_reason_str + len, sizeof(reset_reason_str) - len, "WWDG ");
    }
    if (reset_csr_value & RCC_CSR_LPWRRSTF) {
        len = strlen(reset_reason_str);
        snprintf(reset_reason_str + len, sizeof(reset_reason_str) - len, "LPWRRST ");
    }
    if (reset_csr_value & RCC_CSR_PINRSTF) {
        len = strlen(reset_reason_str);
        snprintf(reset_reason_str + len, sizeof(reset_reason_str) - len, "PINRST ");
    }

    if (dtcm_ota_magic == 0xDEADBEEF) {
        len = strlen(reset_reason_str);
        snprintf(reset_reason_str + len, sizeof(reset_reason_str) - len,
                 "[OTA S%lu@0x%08lX SR_e=0x%08lX CR_e=0x%08lX SR_w=0x%08lX Pre=0x%08lX] ",
                 dtcm_ota_sector, dtcm_ota_addr,
                 dtcm_ota_sr_erase, dtcm_ota_cr_erase,
                 dtcm_ota_sr_write, dtcm_ota_pre_erase0);
        dtcm_ota_magic = 0;
    }

    // Trim trailing space
    len = strlen(reset_reason_str);
    if (len > 0 && reset_reason_str[len - 1] == ' ') {
        reset_reason_str[len - 1] = '\0';
    }

    if (reset_reason_str[0] == '\0') {
        strcpy(reset_reason_str, "None");
    }
}

void early_uart_print(const char *str) {
    volatile uint32_t *ISR = (volatile uint32_t *)(0x40004800 + 0x1C);
    volatile uint32_t *TDR = (volatile uint32_t *)(0x40004800 + 0x28);
    while (*str) {
        volatile uint32_t t = 100000;
        while (!((*ISR) & (1 << 7)) && --t) {}
        *TDR = *str++;
    }
}
#define EARLY_LOG_SYSTEM(fmt) do { if (LOG_CONF_SYSTEM_EN && (g_log_filter_mask & LOG_MASK_SYSTEM)) { early_uart_print(fmt); } } while(0)

/*
 * 0 = Ничего не делать
 * 1 = Принудительно установить Dual Bank Mode (рекомендуется для вашего проекта)
 * 2 = Принудительно установить Single Bank Mode
 */
#define FORCE_FLASH_BANK_MODE 0

void Flash_DecodeError(uint32_t error_mask)
{
    char _ebuf[80];
    if (error_mask == HAL_FLASH_ERROR_NONE)
    {
        early_uart_print("[FLASH_ERR] No errors (0x00000000)\r\n");
        return;
    }

    snprintf(_ebuf, sizeof(_ebuf), "[FLASH_ERR] Raw mask = 0x%08lX\r\n", (unsigned long)error_mask);
    early_uart_print(_ebuf);

#if defined(HAL_FLASH_ERROR_RD)
    if (error_mask & HAL_FLASH_ERROR_RD)
        early_uart_print("  - RDERR: PCROP violation\r\n");
#endif
#if defined(HAL_FLASH_ERROR_PGS)
    if (error_mask & HAL_FLASH_ERROR_PGS)
        early_uart_print("  - PGSERR: programming sequence error\r\n");
#endif
#if defined(HAL_FLASH_ERROR_PGP)
    if (error_mask & HAL_FLASH_ERROR_PGP)
        early_uart_print("  - PGPERR: parallelism error\r\n");
#endif
#if defined(HAL_FLASH_ERROR_PGA)
    if (error_mask & HAL_FLASH_ERROR_PGA)
        early_uart_print("  - PGAERR: alignment error\r\n");
#endif
#if defined(HAL_FLASH_ERROR_WRP)
    if (error_mask & HAL_FLASH_ERROR_WRP)
        early_uart_print("  - WRPERR: write protection error\r\n");
#endif
#if defined(HAL_FLASH_ERROR_OPERATION)
    if (error_mask & HAL_FLASH_ERROR_OPERATION)
        early_uart_print("  - OPERR: operation error\r\n");
#endif
#if defined(HAL_FLASH_ERROR_ERS)
    if (error_mask & HAL_FLASH_ERROR_ERS)
        early_uart_print("  - ERSERR: erase error\r\n");
#endif
}

HAL_StatusTypeDef Switch_To_DualBank(void)
{
    HAL_StatusTypeDef status;
    FLASH_OBProgramInitTypeDef ob_init = {0};
    char _sbuf[80];

    HAL_FLASH_Unlock();
    HAL_FLASH_OB_Unlock();
    HAL_FLASHEx_OBGetConfig(&ob_init);

    snprintf(_sbuf, sizeof(_sbuf), "[OB] USERConfig before = 0x%08lX\r\n", (unsigned long)ob_init.USERConfig);
    early_uart_print(_sbuf);
    ob_init.OptionType = OPTIONBYTE_USER;

#if defined(OB_NDBANK_DUAL_BANK)
    ob_init.USERConfig = (ob_init.USERConfig & ~OB_NDBANK_SINGLE_BANK) | OB_NDBANK_DUAL_BANK;
#else
    #define MY_NDBANK_BIT   (1UL << 29)
    ob_init.USERConfig &= ~MY_NDBANK_BIT;
#endif

    status = HAL_FLASHEx_OBProgram(&ob_init);
    if (status != HAL_OK)
    {
        snprintf(_sbuf, sizeof(_sbuf), "[OB] HAL_FLASHEx_OBProgram failed: %ld\r\n", (long)status);
        early_uart_print(_sbuf);
        Flash_DecodeError(HAL_FLASH_GetError());
        HAL_FLASH_OB_Lock();
        HAL_FLASH_Lock();
        return status;
    }

    early_uart_print("[OB] Option bytes programmed OK (Dual Bank). Launching OBL_LAUNCH (reset)...\r\n");
    HAL_FLASH_OB_Lock();
    HAL_FLASH_Lock();
    HAL_FLASH_OB_Launch();
    return HAL_OK;
}

HAL_StatusTypeDef Switch_To_SingleBank(void)
{
    HAL_StatusTypeDef status;
    FLASH_OBProgramInitTypeDef ob_init = {0};
    char _sbuf[80];

    HAL_FLASH_Unlock();
    HAL_FLASH_OB_Unlock();
    HAL_FLASHEx_OBGetConfig(&ob_init);

    ob_init.OptionType = OPTIONBYTE_USER;

#if defined(OB_NDBANK_SINGLE_BANK)
    ob_init.USERConfig = (ob_init.USERConfig & ~OB_NDBANK_DUAL_BANK) | OB_NDBANK_SINGLE_BANK;
#else
    #define MY_NDBANK_BIT   (1UL << 29)
    ob_init.USERConfig |= MY_NDBANK_BIT;
#endif

    status = HAL_FLASHEx_OBProgram(&ob_init);
    if (status != HAL_OK)
    {
        snprintf(_sbuf, sizeof(_sbuf), "[OB] HAL_FLASHEx_OBProgram failed: %ld\r\n", (long)status);
        early_uart_print(_sbuf);
        Flash_DecodeError(HAL_FLASH_GetError());
        HAL_FLASH_OB_Lock();
        HAL_FLASH_Lock();
        return status;
    }

    early_uart_print("[OB] Option bytes programmed OK (Single Bank). Launching OBL_LAUNCH (reset)...\r\n");
    HAL_FLASH_OB_Lock();
    HAL_FLASH_Lock();
    HAL_FLASH_OB_Launch();
    return HAL_OK;
}

/* USER CODE END 0 */

int main(void)
{

  /* USER CODE BEGIN 1 */
	/* ── Очистка после Bootloader (программный переход, не аппаратный reset) ──
	 * Bootloader использует SysTick как HAL timebase. В приложении
	 * SysTick_Handler = xPortSysTickHandler (FreeRTOS tick). Если SysTick
	 * останется запущенным/pending, он вызовет FreeRTOS до osKernelStart() → crash.
	 *
	 * Порядок критичен:
	 * 1. SysTick остановить и сбросить pending (пока PRIMASK=1 от bootloader'а)
	 * 2. Только потом __enable_irq() — безопасно, SysTick уже не стрельнёт
	 */
	SysTick->CTRL = 0;                          // Стоп SysTick
	SysTick->LOAD = 0;
	SysTick->VAL  = 0;
	SCB->ICSR = SCB_ICSR_PENDSTCLR_Msk;         // Сбросить pending SysTick

    // Early UART Init (115200 baud @ 16MHz HSI)
    RCC->APB1ENR |= RCC_APB1ENR_USART3EN;
    RCC->AHB1ENR |= RCC_AHB1ENR_GPIODEN;
    GPIOD->MODER &= ~(GPIO_MODER_MODER8_Msk | GPIO_MODER_MODER9_Msk);
    GPIOD->MODER |= (2U << GPIO_MODER_MODER8_Pos) | (2U << GPIO_MODER_MODER9_Pos);
    GPIOD->AFR[1] &= ~(0xFFU);
    GPIOD->AFR[1] |= (7U << 0) | (7U << 4);
    USART3->BRR = 0x8B;
    USART3->CR1 = USART_CR1_UE | USART_CR1_TE;

    EARLY_LOG_SYSTEM("[SYSTEM] Entered main() - SysTick cleared\r\n");

  /* ── ITCM check #0: сразу после входа в main() ── */
  {
    uint32_t *flash_src = (uint32_t *)_sitcm_load;
    uint32_t *itcm_dst  = (uint32_t *)_sitcm;
    if (flash_src[0] != itcm_dst[0] || flash_src[1] != itcm_dst[1]) {
      EARLY_LOG_SYSTEM("[SYSTEM] *** ITCM CORRUPTED AT ENTRY #0 ***\r\n");
      while (1) { __NOP(); }
    }
    EARLY_LOG_SYSTEM("[SYSTEM] ITCM check #0 OK\r\n");
  }

  read_reset_reason();
  EARLY_LOG_SYSTEM("[SYSTEM] 1: read_reset_reason done\r\n");
  /* USER CODE END 1 */

  /* MPU Configuration--------------------------------------------------------*/
  MPU_Config();

  /* Enable the CPU Cache */

  /* Enable I-Cache---------------------------------------------------------*/
  SCB_EnableICache();

  /* Enable D-Cache---------------------------------------------------------*/
  SCB_EnableDCache();

  /* MCU Configuration--------------------------------------------------------*/

  /* Reset of all peripherals, Initializes the Flash interface and the Systick. */
  HAL_Init();

  /* Configure the system clock */
  SystemClock_Config();

  /* Initialize all configured peripherals */
  MX_GPIO_Init();
  MX_ETH_Init();
  MX_USART3_UART_Init();
  MX_RNG_Init();
  MX_TIM1_Init();
  MX_FATFS_Init();
  MX_USART2_UART_Init();
  MX_CRC_Init();
  /* USER CODE BEGIN 2 */
  // Проверка режима Bank флеш-памяти (всегда, логирование + опциональное переключение)
  {
      FLASH_OBProgramInitTypeDef ob_test = {0};
      HAL_FLASHEx_OBGetConfig(&ob_test);

      /* ── ITCM check 1d1: сразу после HAL_FLASHEx_OBGetConfig, до printf ── */
      {
        uint32_t *flash_src = (uint32_t *)_sitcm_load;
        uint32_t *itcm_dst  = (uint32_t *)_sitcm;
        if (flash_src[0] != itcm_dst[0] || flash_src[1] != itcm_dst[1]) {
          EARLY_LOG_SYSTEM("[SYSTEM] *** ITCM CORRUPTED AT 1d1 (after HAL_FLASHEx_OBGetConfig) ***\r\n");
          while (1) { __NOP(); }
        }
        EARLY_LOG_SYSTEM("[SYSTEM] 1d1: ITCM OK\r\n");
      }

      // bit 29: 0 = Dual Bank, 1 = Single Bank
      uint32_t is_single_bank = (ob_test.USERConfig & (1UL << 29)) ? 1 : 0;

#if FORCE_FLASH_BANK_MODE == 1
      if (is_single_bank) {
          early_uart_print("\r\n[SYSTEM] Warning: Flash is Single Bank. Forcing Dual Bank mode!\r\n");
          Switch_To_DualBank();
      } else {
          early_uart_print("\r\n[SYSTEM] Flash is already in Dual Bank mode (OK).\r\n");
      }
#elif FORCE_FLASH_BANK_MODE == 2
      if (!is_single_bank) {
          early_uart_print("\r\n[SYSTEM] Warning: Flash is Dual Bank. Forcing Single Bank mode!\r\n");
          Switch_To_SingleBank();
      } else {
          early_uart_print("\r\n[SYSTEM] Flash is already in Single Bank mode (OK).\r\n");
      }
#else
      if (is_single_bank) {
          early_uart_print("\r\n[SYSTEM] Warning: Flash is Single Bank (no auto-fix).\r\n");
      } else {
          early_uart_print("\r\n[SYSTEM] Flash is Dual Bank (OK).\r\n");
      }
#endif

      /* ── ITCM check 1d2: сразу после printf (теперь early_uart_print) ── */
      {
        uint32_t *flash_src = (uint32_t *)_sitcm_load;
        uint32_t *itcm_dst  = (uint32_t *)_sitcm;
        if (flash_src[0] != itcm_dst[0] || flash_src[1] != itcm_dst[1]) {
          EARLY_LOG_SYSTEM("[SYSTEM] *** ITCM CORRUPTED AT 1d2 (after bank print) ***\r\n");
          while (1) { __NOP(); }
        }
        EARLY_LOG_SYSTEM("[SYSTEM] 1d2: ITCM OK\r\n");
      }
  }
  EARLY_LOG_SYSTEM("[SYSTEM] 14: flash bank check done\r\n");

  // Инициализация массивов датчиков
  memset(ds18b20, 0, sizeof(ds18b20));

  /* ── ITCM check 1e: после memset(ds18b20) ── */
  {
    uint32_t *flash_src = (uint32_t *)_sitcm_load;
    uint32_t *itcm_dst  = (uint32_t *)_sitcm;
    if (flash_src[0] != itcm_dst[0] || flash_src[1] != itcm_dst[1]) {
      EARLY_LOG_SYSTEM("[SYSTEM] *** ITCM CORRUPTED AT 1e (after memset ds18b20) ***\r\n");
      while (1) { __NOP(); }
    }
    EARLY_LOG_SYSTEM("[SYSTEM] 1e: ITCM OK\r\n");
  }

  /* dht22 перенесён в DTCM — memset после dtcm_alloc_init() (ниже) */

  EARLY_LOG_SYSTEM("[SYSTEM] 15: sensor arrays zeroed\r\n");
  DWT_Init();

  /* ── ITCM check 1g: после DWT_Init() ── */
  {
    uint32_t *flash_src = (uint32_t *)_sitcm_load;
    uint32_t *itcm_dst  = (uint32_t *)_sitcm;
    if (flash_src[0] != itcm_dst[0] || flash_src[1] != itcm_dst[1]) {
      EARLY_LOG_SYSTEM("[SYSTEM] *** ITCM CORRUPTED AT 1g (after DWT_Init) ***\r\n");
      while (1) { __NOP(); }
    }
    EARLY_LOG_SYSTEM("[SYSTEM] 1g: ITCM OK\r\n");
  }

  EARLY_LOG_SYSTEM("[SYSTEM] 16: DWT done\r\n");
  test_init();
  EARLY_LOG_SYSTEM("[SYSTEM] 17: test_init done\r\n");

  /* ── ITCM check #2: перед dtcm_alloc_init() ── */
  {
    uint32_t *flash_src = (uint32_t *)_sitcm_load;
    uint32_t *itcm_dst  = (uint32_t *)_sitcm;
    uint32_t  itcm_size = (uint32_t)(_eitcm - _sitcm);
    uint32_t  nwords    = itcm_size / 4;
    uint32_t  errors    = 0;
    for (uint32_t i = 0; i < nwords; i++) {
      if (flash_src[i] != itcm_dst[i]) {
        char buf[80];
        snprintf(buf, sizeof(buf),
                 "[SYSTEM] *** ITCM BAD [%lu] flash=0x%08lX itcm=0x%08lX\r\n",
                 (unsigned long)i, (unsigned long)flash_src[i],
                 (unsigned long)itcm_dst[i]);
        EARLY_LOG_SYSTEM(buf);
        errors++;
        if (errors >= 8) break;
      }
    }
    if (errors == 0) {
      EARLY_LOG_SYSTEM("[SYSTEM] 17a: ITCM verify OK\r\n");
    } else {
      EARLY_LOG_SYSTEM("[SYSTEM] *** ITCM CORRUPTED ***\r\n");
      while (1) { __NOP(); }
    }
  }

  dtcm_alloc_init();
  /* BSS → DTCM: присваиваем указатели (с проверкой на overflow) */
  PidConf = dtcm_pid_conf;
  if (PidConf) memset(PidConf, 0, sizeof(dbPidConf) * PID_MAX_SLOTS);
  /* ЭТАП 2: htim + dht22 + button + PinsLinks → DTCM (pool — NOLOAD, нужен memset) */
  htim = dtcm_htim;
  if (htim) memset(htim, 0, sizeof(TIM_HandleTypeDef) * NUMPIN);
  dht22 = dtcm_dht22;
  if (dht22) memset(dht22, 0, sizeof(dht22_pin_t) * MAX_DHT22_P);
  button = dtcm_button;
  if (button) memset(button, 0, sizeof(struct Button) * NUMPIN);
  PinsLinks = dtcm_pinslinks;
  if (PinsLinks) memset(PinsLinks, 0, sizeof(struct dbPinToPin) * NUMPINLINKS);
  /* ZigbeeConf — в .bss, обнуляется стартапом автоматически */
  if (dtcm_sec_deb_tm)     memset(dtcm_sec_deb_tm, 0, sizeof(uint32_t) * NUMPIN);
  if (dtcm_sec_lasttrg)    memset(dtcm_sec_lasttrg, 0, sizeof(uint32_t) * NUMPIN);
  if (dtcm_fade_state)     memset(dtcm_fade_state, 0, sizeof(FadeState_t) * NUMPIN);
  if (dtcm_cron_ctxs)      memset(dtcm_cron_ctxs, 0, sizeof(lwdtc_cron_ctx_t) * NUMTASK);
  if (dtcm_prev_pwm_dvalue) memset(dtcm_prev_pwm_dvalue, 0, sizeof(int) * NUMPIN);
  if (dtcm_prev_gpio)      memset(dtcm_prev_gpio, 0xFF, sizeof(uint8_t) * NUMPIN);
  if (dtcm_prev_duty) { for (int i = 0; i < NUMPIN; i++) dtcm_prev_duty[i] = -1; }
  if (dtcm_zbee_last_cmd_tick) memset(dtcm_zbee_last_cmd_tick, 0, sizeof(uint32_t) * NUMZBEE);
  usart_ring_dtcm_init();
  gsm_dtcm_init();
  net_dtcm_init();
  zagotovka_dtcm_init();
  etag_version_seed(); /* случайный ETag-salt: после ребута браузер не должен получать 304 */
  {
    char _sbuf[192];
    snprintf(_sbuf, sizeof(_sbuf), "[SYSTEM] DTCM pool: %u B total at 0x%08lX\r\n",
             (unsigned)dtcm_alloc_get_total(), (unsigned long)_sdtcm_pool);
    early_uart_print(_sbuf);
    snprintf(_sbuf, sizeof(_sbuf), "[SYSTEM] Reset CSR=0x%08lX\r\n", reset_csr_value);
    early_uart_print(_sbuf);
    snprintf(_sbuf, sizeof(_sbuf), "[SYSTEM] Reset flags: %s\r\n", reset_reason_str);
    early_uart_print(_sbuf);
    snprintf(_sbuf, sizeof(_sbuf), "[SYSTEM] Reset reason: %s (CSR=0x%08lX)\r\n", reset_reason_str, reset_csr_value);
    early_uart_print(_sbuf);
    /* OTA crash diagnostics (survives NVIC reset, lives in noinit_ram) */
    if (dtcm_ota_magic == 0xDEADBEEF) {
      snprintf(_sbuf, sizeof(_sbuf), "[OTA-DIAG] sector=%lu addr=0x%08lX\r\n", dtcm_ota_sector, dtcm_ota_addr);
      early_uart_print(_sbuf);
      snprintf(_sbuf, sizeof(_sbuf), "[OTA-DIAG] sr_erase=0x%08lX cr_erase=0x%08lX\r\n", dtcm_ota_sr_erase, dtcm_ota_cr_erase);
      early_uart_print(_sbuf);
      snprintf(_sbuf, sizeof(_sbuf), "[OTA-DIAG] sr_write=0x%08lX wr_addr=0x%08lX wr_word=0x%08lX\r\n",
               dtcm_ota_sr_write, dtcm_ota_write_addr, dtcm_ota_write_word);
      early_uart_print(_sbuf);
      snprintf(_sbuf, sizeof(_sbuf), "[OTA-DIAG] pre_erase=0x%08lX\r\n", dtcm_ota_pre_erase0);
      early_uart_print(_sbuf);
      if (dtcm_ota_sr_erase & 0x80000000) {
        early_uart_print("[OTA-DIAG] ** POST-ERASE VERIFY FAILED: sector NOT erased to 0xFF! **\r\n");
      }
      if (dtcm_ota_sr_erase & 0x7E) {
        snprintf(_sbuf, sizeof(_sbuf), "[OTA-DIAG] ** FLASH_SR errors after erase: 0x%02lX **\r\n",
                 (dtcm_ota_sr_erase >> 1) & 0x3F);
        early_uart_print(_sbuf);
      }
      dtcm_ota_magic = 0;
    }
  }

  /* USER CODE END 2 */

  /* Init scheduler */
  osKernelInitialize();
  /* Create the mutex(es) */
  /* creation of actionMutexHandle */
  actionMutexHandleHandle = osMutexNew(&actionMutexHandle_attributes);

  /* creation of s_mysett_mutex */
  s_mysett_mutexHandle = osMutexNew(&s_mysett_mutex_attributes);

  /* USER CODE BEGIN RTOS_TIMERS */
  /* Индикация USB-состояния на LD3: программный таймер 100 мс.
   * cb гасит светодиод сам, когда PB14 занят пользователем или USB в норме. */
  osTimerId_t usb_led_timer = osTimerNew(usb_led_timer_cb, osTimerPeriodic, NULL, NULL);
  if (usb_led_timer != NULL) osTimerStart(usb_led_timer, 100);
  /* USER CODE END RTOS_TIMERS */

  /* Create the queue(s) */
  /* creation of outputQueue */
  outputQueueHandle = osMessageQueueNew (64, sizeof(struct data_pin_t), &outputQueue_attributes);

  /* creation of usbQueue */
  usbQueueHandle = osMessageQueueNew (16, sizeof(uint8_t), &usbQueue_attributes);

  /* creation of mqttQueue */
  mqttQueueHandle = osMessageQueueNew (32, sizeof(MqttMessage_t), &mqttQueue_attributes);

  /* creation of mqttRxQueue */
  mqttRxQueueHandle = osMessageQueueNew (32, sizeof(MqttRxMsg_t), &mqttRxQueue_attributes);

  /* creation of zbeeCmdQueue */
  zbeeCmdQueueHandle = osMessageQueueNew (64, sizeof(ZbeeCmdMsg_t), &zbeeCmdQueue_attributes);

  /* USER CODE BEGIN RTOS_QUEUES */
  /* add queues, ... */
  logger_init();
  /* USER CODE END RTOS_QUEUES */

  /* Create the thread(s) */
  /* creation of ConfigTask */
  ConfigTaskHandle = osThreadNew(StartConfigTask, NULL, &ConfigTask_attributes);

  /* creation of OutputTask */
  OutputTaskHandle = osThreadNew(StartOutputTask, NULL, &OutputTask_attributes);

  /* creation of CronTask */
  CronTaskHandle = osThreadNew(StartCronTask, NULL, &CronTask_attributes);

  /* creation of InputTask */
  InputTaskHandle = osThreadNew(StartInputTask, NULL, &InputTask_attributes);

  /* creation of EncoderTask */
  EncoderTaskHandle = osThreadNew(StartEncoderTask, NULL, &EncoderTask_attributes);

  /* creation of ds18b20Task */
  ds18b20TaskHandle = osThreadNew(StartDs18b20Task, NULL, &ds18b20Task_attributes);

  /* creation of dht22Task */
  dht22TaskHandle = osThreadNew(StartDht22Task, NULL, &dht22Task_attributes);

  /* creation of ServiceTask */
  ServiceTaskHandle = osThreadNew(StartServiceTask, NULL, &ServiceTask_attributes);

  /* creation of SIM800LTask */
  SIM800LTaskHandle = osThreadNew(StartSIM800LTask, NULL, &SIM800LTask_attributes);

  /* creation of SecurityTask */
  SecurityTaskHandle = osThreadNew(StartSecurityTask, NULL, &SecurityTask_attributes);

  /* creation of PIDTask */
  PIDTaskHandle = osThreadNew(StartPIDTask, NULL, &PIDTask_attributes);

  /* creation of my_DgnTask */
  my_DgnTaskHandle = osThreadNew(StartDgnTask, NULL, &my_DgnTask_attributes);

  /* creation of LoggerTask */
  LoggerTaskHandle = osThreadNew(StartLoggerTask, NULL, &LoggerTask_attributes);

  /* USER CODE BEGIN RTOS_THREADS */
  /* add threads, ... */

  /* creation of WebServerTask */
  {
    /* Стек и TCB WebServerTask (18 КБ) — в DTCM, а не в куче FreeRTOS.
     * Если пула не хватит — штатный путь через кучу. */
    static osThreadAttr_t web_attr;
    web_attr = WebServerTask_attributes;
    void *w_stk = dtcm_malloc(WebServerTask_attributes.stack_size);
    void *w_tcb = dtcm_malloc(sizeof(StaticTask_t));
    if (w_stk != NULL && w_tcb != NULL) {
      web_attr.stack_mem = w_stk;
      web_attr.stack_size = WebServerTask_attributes.stack_size;
      web_attr.cb_mem = w_tcb;
      web_attr.cb_size = sizeof(StaticTask_t);
    }
    WebServerTaskHandle = osThreadNew(StartWebServerTask, NULL, &web_attr);
  }
  /* USER CODE END RTOS_THREADS */

  /* Start scheduler */
  osKernelStart();

  /* We should never get here as control is now taken by the scheduler */

  /* Infinite loop */
  while (1) {

  }
}

void SystemClock_Config(void)
{
  RCC_OscInitTypeDef RCC_OscInitStruct = {0};
  RCC_ClkInitTypeDef RCC_ClkInitStruct = {0};

  /** Configure LSE Drive Capability
  */
  HAL_PWR_EnableBkUpAccess();

  /** Configure the main internal regulator output voltage
  */
  __HAL_RCC_PWR_CLK_ENABLE();
  __HAL_PWR_VOLTAGESCALING_CONFIG(PWR_REGULATOR_VOLTAGE_SCALE1);

  /** Initializes the RCC Oscillators according to the specified parameters
  * in the RCC_OscInitTypeDef structure.
  */
  RCC_OscInitStruct.OscillatorType = RCC_OSCILLATORTYPE_HSE;
  RCC_OscInitStruct.HSEState = RCC_HSE_BYPASS;
  RCC_OscInitStruct.PLL.PLLState = RCC_PLL_ON;
  RCC_OscInitStruct.PLL.PLLSource = RCC_PLLSOURCE_HSE;
  RCC_OscInitStruct.PLL.PLLM = 4;
  RCC_OscInitStruct.PLL.PLLN = 216;
  RCC_OscInitStruct.PLL.PLLP = RCC_PLLP_DIV2;
  RCC_OscInitStruct.PLL.PLLQ = 9;
  RCC_OscInitStruct.PLL.PLLR = 2;
  if (HAL_RCC_OscConfig(&RCC_OscInitStruct) != HAL_OK)
  {
    Error_Handler();
  }

  /** Activate the Over-Drive mode
  */
  if (HAL_PWREx_EnableOverDrive() != HAL_OK)
  {
    Error_Handler();
  }

  /** Initializes the CPU, AHB and APB buses clocks
  */
  RCC_ClkInitStruct.ClockType = RCC_CLOCKTYPE_HCLK|RCC_CLOCKTYPE_SYSCLK
                              |RCC_CLOCKTYPE_PCLK1|RCC_CLOCKTYPE_PCLK2;
  RCC_ClkInitStruct.SYSCLKSource = RCC_SYSCLKSOURCE_PLLCLK;
  RCC_ClkInitStruct.AHBCLKDivider = RCC_SYSCLK_DIV1;
  RCC_ClkInitStruct.APB1CLKDivider = RCC_HCLK_DIV4;
  RCC_ClkInitStruct.APB2CLKDivider = RCC_HCLK_DIV2;

  if (HAL_RCC_ClockConfig(&RCC_ClkInitStruct, FLASH_LATENCY_7) != HAL_OK)
  {
    Error_Handler();
  }
}

static void MX_CRC_Init(void)
{

  hcrc.Instance = CRC;
  hcrc.Init.DefaultPolynomialUse = DEFAULT_POLYNOMIAL_ENABLE;
  hcrc.Init.DefaultInitValueUse = DEFAULT_INIT_VALUE_ENABLE;
  hcrc.Init.InputDataInversionMode = CRC_INPUTDATA_INVERSION_NONE;
  hcrc.Init.OutputDataInversionMode = CRC_OUTPUTDATA_INVERSION_DISABLE;
  hcrc.InputDataFormat = CRC_INPUTDATA_FORMAT_BYTES;
  if (HAL_CRC_Init(&hcrc) != HAL_OK)
  {
    Error_Handler();
  }

}

static void MX_ETH_Init(void)
{

   static uint8_t MACAddr[6];

  heth.Instance = ETH;
  MACAddr[0] = 0x00;
  MACAddr[1] = 0x80;
  MACAddr[2] = 0xE1;
  MACAddr[3] = 0x00;
  MACAddr[4] = 0x00;
  MACAddr[5] = 0x00;
  heth.Init.MACAddr = &MACAddr[0];
  heth.Init.MediaInterface = HAL_ETH_RMII_MODE;
  heth.Init.TxDesc = DMATxDscrTab;
  heth.Init.RxDesc = DMARxDscrTab;
  heth.Init.RxBuffLen = 1524;

  /* USER CODE BEGIN MACADDRESS */
  /* Генерируем уникальный MAC из 96-bit UUID чипа (locally administered) */
  MACAddr[0] = 0x02;  /* locally administered, unicast */
  MACAddr[1] = UUID[0] ^ UUID[1];
  MACAddr[2] = UUID[2] ^ UUID[3];
  MACAddr[3] = UUID[4] ^ UUID[5];
  MACAddr[4] = UUID[6] ^ UUID[7] ^ UUID[8];
  MACAddr[5] = UUID[9] ^ UUID[10] ^ UUID[11];
  /* USER CODE END MACADDRESS */

  if (HAL_ETH_Init(&heth) != HAL_OK)
  {
    Error_Handler();
  }

  memset(&TxConfig, 0 , sizeof(ETH_TxPacketConfig));
  TxConfig.Attributes = ETH_TX_PACKETS_FEATURES_CSUM | ETH_TX_PACKETS_FEATURES_CRCPAD;
  TxConfig.ChecksumCtrl = ETH_CHECKSUM_IPHDR_PAYLOAD_INSERT_PHDR_CALC;
  TxConfig.CRCPadCtrl = ETH_CRC_PAD_INSERT;

}

static void MX_RNG_Init(void)
{

  hrng.Instance = RNG;
  if (HAL_RNG_Init(&hrng) != HAL_OK)
  {
    Error_Handler();
  }

}

static void MX_TIM1_Init(void)
{

  TIM_ClockConfigTypeDef sClockSourceConfig = {0};
  TIM_MasterConfigTypeDef sMasterConfig = {0};

  htim1.Instance = TIM1;
  htim1.Init.Prescaler = 216-1;
  htim1.Init.CounterMode = TIM_COUNTERMODE_UP;
  htim1.Init.Period = 65535;
  htim1.Init.ClockDivision = TIM_CLOCKDIVISION_DIV1;
  htim1.Init.RepetitionCounter = 0;
  htim1.Init.AutoReloadPreload = TIM_AUTORELOAD_PRELOAD_DISABLE;
  if (HAL_TIM_Base_Init(&htim1) != HAL_OK)
  {
    Error_Handler();
  }
  sClockSourceConfig.ClockSource = TIM_CLOCKSOURCE_INTERNAL;
  if (HAL_TIM_ConfigClockSource(&htim1, &sClockSourceConfig) != HAL_OK)
  {
    Error_Handler();
  }
  sMasterConfig.MasterOutputTrigger = TIM_TRGO_RESET;
  sMasterConfig.MasterOutputTrigger2 = TIM_TRGO2_RESET;
  sMasterConfig.MasterSlaveMode = TIM_MASTERSLAVEMODE_DISABLE;
  if (HAL_TIMEx_MasterConfigSynchronization(&htim1, &sMasterConfig) != HAL_OK)
  {
    Error_Handler();
  }

}

static void MX_USART2_UART_Init(void)
{

  huart2.Instance = USART2;
  huart2.Init.BaudRate = 57600;
  huart2.Init.WordLength = UART_WORDLENGTH_8B;
  huart2.Init.StopBits = UART_STOPBITS_1;
  huart2.Init.Parity = UART_PARITY_NONE;
  huart2.Init.Mode = UART_MODE_TX_RX;
  huart2.Init.HwFlowCtl = UART_HWCONTROL_NONE;
  huart2.Init.OverSampling = UART_OVERSAMPLING_16;
  huart2.Init.OneBitSampling = UART_ONE_BIT_SAMPLE_DISABLE;
  huart2.AdvancedInit.AdvFeatureInit = UART_ADVFEATURE_NO_INIT;
  if (HAL_UART_Init(&huart2) != HAL_OK)
  {
    Error_Handler();
  }

}

static void MX_USART3_UART_Init(void)
{

  huart3.Instance = USART3;
  huart3.Init.BaudRate = 115200;
  huart3.Init.WordLength = UART_WORDLENGTH_8B;
  huart3.Init.StopBits = UART_STOPBITS_1;
  huart3.Init.Parity = UART_PARITY_NONE;
  huart3.Init.Mode = UART_MODE_TX_RX;
  huart3.Init.HwFlowCtl = UART_HWCONTROL_NONE;
  huart3.Init.OverSampling = UART_OVERSAMPLING_16;
  huart3.Init.OneBitSampling = UART_ONE_BIT_SAMPLE_DISABLE;
  huart3.AdvancedInit.AdvFeatureInit = UART_ADVFEATURE_NO_INIT;
  if (HAL_UART_Init(&huart3) != HAL_OK)
  {
    Error_Handler();
  }

}

static void MX_GPIO_Init(void)
{
  GPIO_InitTypeDef GPIO_InitStruct = {0};

  /* GPIO Ports Clock Enable */
  __HAL_RCC_GPIOC_CLK_ENABLE();
  __HAL_RCC_GPIOH_CLK_ENABLE();
  __HAL_RCC_GPIOA_CLK_ENABLE();
  __HAL_RCC_GPIOB_CLK_ENABLE();
  __HAL_RCC_GPIOD_CLK_ENABLE();
  __HAL_RCC_GPIOG_CLK_ENABLE();

  /*Configure GPIO pin Output Level */
  HAL_GPIO_WritePin(SENSOR_GPIO_Port, SENSOR_Pin, GPIO_PIN_RESET);

  /*Configure GPIO pin Output Level */
  HAL_GPIO_WritePin(GPIOB, LD1_Pin|LD3_Pin|LD2_Pin, GPIO_PIN_RESET);

  /*Configure GPIO pin Output Level */
  HAL_GPIO_WritePin(USB_PowerSwitchOn_GPIO_Port, USB_PowerSwitchOn_Pin, GPIO_PIN_RESET);

  /*Configure GPIO pin : USER_Btn_Pin */
  GPIO_InitStruct.Pin = USER_Btn_Pin;
  GPIO_InitStruct.Mode = GPIO_MODE_IT_RISING;
  GPIO_InitStruct.Pull = GPIO_NOPULL;
  HAL_GPIO_Init(USER_Btn_GPIO_Port, &GPIO_InitStruct);

  /*Configure GPIO pin : SENSOR_Pin */
  GPIO_InitStruct.Pin = SENSOR_Pin;
  GPIO_InitStruct.Mode = GPIO_MODE_OUTPUT_PP;
  GPIO_InitStruct.Pull = GPIO_NOPULL;
  GPIO_InitStruct.Speed = GPIO_SPEED_FREQ_LOW;
  HAL_GPIO_Init(SENSOR_GPIO_Port, &GPIO_InitStruct);

  /*Configure GPIO pins : LD1_Pin LD3_Pin LD2_Pin */
  GPIO_InitStruct.Pin = LD1_Pin|LD3_Pin|LD2_Pin;
  GPIO_InitStruct.Mode = GPIO_MODE_OUTPUT_PP;
  GPIO_InitStruct.Pull = GPIO_NOPULL;
  GPIO_InitStruct.Speed = GPIO_SPEED_FREQ_LOW;
  HAL_GPIO_Init(GPIOB, &GPIO_InitStruct);

  /*Configure GPIO pin : USB_PowerSwitchOn_Pin */
  GPIO_InitStruct.Pin = USB_PowerSwitchOn_Pin;
  GPIO_InitStruct.Mode = GPIO_MODE_OUTPUT_PP;
  GPIO_InitStruct.Pull = GPIO_NOPULL;
  GPIO_InitStruct.Speed = GPIO_SPEED_FREQ_LOW;
  HAL_GPIO_Init(USB_PowerSwitchOn_GPIO_Port, &GPIO_InitStruct);

  /*Configure GPIO pin : USB_OverCurrent_Pin */
  GPIO_InitStruct.Pin = USB_OverCurrent_Pin;
  GPIO_InitStruct.Mode = GPIO_MODE_INPUT;
  GPIO_InitStruct.Pull = GPIO_NOPULL;
  HAL_GPIO_Init(USB_OverCurrent_GPIO_Port, &GPIO_InitStruct);

}

/* USER CODE BEGIN 4 */
void vApplicationMallocFailedHook(void)
{
    malloc_fail_count++;
    printf("\r\n!!! CRITICAL: MALLOC FAIL %lu !!!\r\n", malloc_fail_count);
}

/*********************** для printf ******************************/
/* PUTCHAR_PROTOTYPE перенесен в logger.c */
/************************ PWM Fade *************************************/
/* FadeState_t определён в dtcm_alloc.h — выделяется в DTCM через dtcm_fade_state */
#define fade_state dtcm_fade_state

/* Запускает (или перезапускает) плавное изменение PWM.
 * pwm_id       — логический ID PWM-пина (1..NUMPIN, topin == 5), не индекс
 * duration_sec — длительность перехода в секундах
 * start_duty   — начальная яркость 0–100%
 * end_duty     — конечная яркость   0–100% */
void start_pwm_fade(uint16_t pwm_id, uint32_t duration_sec,
                    int start_duty, int end_duty, int cronindex) {
    int pwm_idx = PinIdxFromId(pwm_id);
    if (pwm_idx < 0 || pwm_idx >= NUMPIN || PinsConf[pwm_idx].topin != 5) {
        printf("start_pwm_fade: bad id=%d\r\n", pwm_id);
        return;
    }
    if (is_pin_in_autotune(pwm_idx)) {
        printf("[FADE] BLOCKED by AutoTune: pwm_id=%d\r\n", pwm_id);
        return;
    }

    /* Рубильник: Encoder onoff (приоритетный) либо On/Off самой PWM-строки */
    bool enc_on = pwm_gate_open(pwm_idx);
    if (!enc_on) {
        // Гасим PWM и блокируем — БЕЗОПАСНОСТЬ
        __HAL_TIM_SET_COMPARE(&htim[pwm_idx], PinsInfo[pwm_idx].tim_channel, 0);
        fade_state[pwm_idx].active = false;
        return;
    }

    uint32_t steps = duration_sec > 0 ? duration_sec : 1;

    fade_state[pwm_idx].active       = true;
    fade_state[pwm_idx].current_duty = (float)start_duty;
    fade_state[pwm_idx].delta        = (float)(end_duty - start_duty)
                                       / (float)steps;
    fade_state[pwm_idx].steps_left   = steps;
    fade_state[pwm_idx].end_duty     = end_duty;
    fade_state[pwm_idx].cronindex    = cronindex;

    /* Сохраняем pwm_out PID для бесшовной передачи после fade */
    fade_state[pwm_idx].saved_pid_duty = 0;
    for (int p = 0; p < PID_MAX_SLOTS; p++) {
      if (PidConf[p].pwm_pin_id == pwm_id) {
        fade_state[pwm_idx].saved_pid_duty = PidConf[p].pwm_out;
        break;
      }
    }

    /* Устанавливаем начальное значение немедленно */
    PinsConf[pwm_idx].dvalue = start_duty;
    uint32_t pulsef3 =
        (uint32_t)((uint64_t)start_duty * PinsConf[pwm_idx].pwmmax / 100ULL);
    __HAL_TIM_SET_COMPARE(&htim[pwm_idx], PinsInfo[pwm_idx].tim_channel, pulsef3);

//    printf("PWM fade: id=%d %ds %d%%->%d%%\r\n",pwm_id, (int)duration_sec, start_duty, end_duty);
}
/*********************** END PWM Fade **********************************/
void parse_string(char *str, time_t cronetime_olds, int cronindex, int pause) {
  /* Timer onoff — только управление расписанием */
  if (cronindex >= 0 && cronindex < NUMTASK && dbCrontxt[cronindex].onoff == 0) {
    // Просто не запускаем fade/события, PWM не трогаем
    return;
  }
  char *token;
  char *saveptr;
  int flag = 0;
  int k = 0;
  int pin = 0;
  char delim[] = ",";
  /* mqtt_sent удалён — таймеры публикуются через send_mqtt_timer_batch() */
  data_pin_t data_pin = {0}; /* A3: локальная копия */
  //    printf("Debug: Parsing string for cronindex=%d, pause=%d\n", cronindex,
  //    pause); printf("Debug: Input string: %s\n", str);
  token = strtok_r(str, delim, &saveptr);
  while (token != NULL) {
    char *end_token;
    /* Дополнительное условие срабатывания: "5:1?D2" (см. cond_eval.h).
     * Разбираем до ветвлений pwm:/p: условие не содержит запятых,
     * но может содержать ':' и '.'. */
    const char *cond = NULL;
    {
      char *qmark = strchr(token, '?');
      if (qmark != NULL) {
        *qmark = '\0';
        cond = qmark + 1;
      }
    }
    if (cond != NULL && !cond_eval(cond)) {
      token = strtok_r(NULL, delim, &saveptr);
      continue;
    }
    //        printf("Debug: Processing token: %s\n", token);
    /* --- PWM Fade: формат "pwm:<id>,<duration_sec>,<start%>,<end%>" --- */
    if (strncmp(token, "pwm:", 4) == 0 && pause == 0) {
      int pwm_id = 0, dur = 0, sduty = 0, eduty = 0;
      char *t1 = token + 4;
      char *t2 = strtok_r(NULL, delim, &saveptr);
      char *t3 = strtok_r(NULL, delim, &saveptr);
      char *t4 = strtok_r(NULL, delim, &saveptr);
      if (t1 && t2 && t3 && t4) {
        /* Условие может стоять и на последнем параметре: pwm:5,60,0,100?D2 */
        char *q4 = strchr(t4, '?');
        if (q4 != NULL) {
          *q4 = '\0';
          if (!cond_eval(q4 + 1)) {
            /* Условие ложно - пропускаем запуск fade */
            token = strtok_r(NULL, delim, &saveptr);
            continue;
          }
        }
        pwm_id = atoi(t1);
        dur = atoi(t2);
        sduty = atoi(t3);
        eduty = atoi(t4);
        start_pwm_fade((uint16_t)pwm_id, (uint32_t)dur, sduty, eduty, cronindex);
        /* MQTT: батч send_mqtt_timer_batch() отправляет состояние раз в 1с */
      } else {
        printf("parse_string: bad pwm token: %s\r\n", token);
      }
      token = strtok_r(NULL, delim, &saveptr);
      continue; /* переходим к следующему токену */
    }
    if (token[0] == 'p') {
      char *newstring = token + 1;
      dbCrontxt[cronindex].ptime = cronetime_olds + atoi(newstring);
      flag = 1;
      //            printf("Debug: Found pause token, flag set to 1\n");
    }
    if (flag == pause) {
      char *token2 = strtok_r(token, ":", &end_token);
      k = 0;
      while (token2 != NULL) {
        if (k == 0) {
          pin = atoi(token2);
          if (pin != 0) {
            data_pin.id = pin;
          }
        }
        if (k == 1) {
          data_pin.action = atoi(token2);
        }
        token2 = strtok_r(NULL, ":", &end_token);
        k++;
      }
      if (k == 2) {
        xQueueSend(outputQueueHandle, (void *)&data_pin, 0);
        /* MQTT: батч send_mqtt_timer_batch() отправляет состояние раз в 1с */
      }
    }
    token = strtok_r(NULL, delim, &saveptr);
  }
}

/* ═══ ITCM runtime integrity check ═══
 * Сравнивает ITCM-код с загрузочным образом во Flash (тот же принцип, что
 * проверка 17a при старте). Ловит порчу ITCM в рантайме wild-записями,
 * которая проявлялась как HardFault UNDEFINSTR (PC=0x24, dtcm_malloc).
 * Возвращает число несовпавших слов (макс. 8), details первого несовпадения. */
static uint32_t itcm_check_words(uint32_t *first_idx, uint32_t *exp_word, uint32_t *got_word)
{
  const uint32_t *flash_src = (const uint32_t *)_sitcm_load;
  const uint32_t *itcm_dst  = (const uint32_t *)_sitcm;
  uint32_t n = (uint32_t)(_eitcm - _sitcm) / 4;
  uint32_t errors = 0;
  for (uint32_t i = 0; i < n; i++) {
    if (flash_src[i] != itcm_dst[i]) {
      if (errors == 0 && first_idx != NULL) {
        *first_idx = i;
        if (exp_word) *exp_word = flash_src[i];
        if (got_word) *got_word = itcm_dst[i];
      }
      errors++;
      if (errors >= 8) break;
    }
  }
  return errors;
}

/* ═══ USB: проба файлов конфигурации (есть / нет / диск врёт) ═══
 * Решение "читать или создавать" принимаем ТОЛЬКО по FR_NO_FILE:
 * любая ошибка чтения (FR_DISK_ERR/FR_NOT_READY и т.п.) на медленной
 * флешке не должна уводить в путь "создаём дефолты" с FA_CREATE_ALWAYS. */
typedef enum { INI_PRESENT, INI_MISSING, INI_ERROR } ini_probe_t;

static ini_probe_t ini_probe(const char *name) {
  FILINFO fi;
  for (int i = 0; i < 3; i++) {
    FRESULT r = f_stat(name, &fi);
    if (r == FR_OK)      return INI_PRESENT;
    if (r == FR_NO_FILE) return INI_MISSING;
    osDelay(200); /* транзиентный сбой: повторить */
  }
  return INI_ERROR;
}

static bool usb_probe_all(void) {
  static const char *const n[] = {
    "settings.ini", "cron.ini", "pins.ini", "cond.ini",
    "pintopin.ini", "onewire.ini", "pid.ini", "zigbee.ini"
  };
  for (unsigned i = 0; i < sizeof(n) / sizeof(n[0]); i++)
    if (ini_probe(n[i]) == INI_ERROR) return false;
  return true;
}

/* Вынесена из StartWebServerTask — GCC nested functions используют трамплины
 * на стеке, что вызывает HardFault на Cortex-M7 (XN-protected SRAM). */
static void static_or_dynamic_ip(struct mg_tcpip_if *mif,
                                 struct dbSettings *config) {
  if (config->check_ip == 1) { // DHCP
    MG_INFO(("2 - Generated MAC: %02X:%02X:%02X:%02X:%02X:%02X\r\n",
             mif->mac[0], mif->mac[1], mif->mac[2], mif->mac[3], mif->mac[4],
             mif->mac[5]));
  } else { // Статический IP
    mif->ip = mg_htonl(MG_U32(config->ip_addr0, config->ip_addr1,
                              config->ip_addr2, config->ip_addr3));
    mif->mask = mg_htonl(MG_U32(config->sb_mask0, config->sb_mask1,
                                config->sb_mask2, config->sb_mask3));
    mif->gw = mg_htonl(MG_U32(config->gateway0, config->gateway1,
                                config->gateway2, config->gateway3));
  }
}

void StartWebServerTask(void *argument)
{
  /* USER CODE BEGIN StartWebServerTask */
  ulTaskNotifyTake(0, portMAX_DELAY);
  mg_log_set(MG_LL_ERROR); // Установи уровень логирования 'MG_LL_INFO' для отладки.
  if (!quick_network_check()) { // Проверка подключен LAN провод или нет.
    printf("Network link down - Web server not started");
    vTaskDelete(NULL);
    return;
  } else {
    onlineFlg = 1;
  }

  /* Инициализация настроек HTTPS — независимо от usehttps: при usehttps=0
   * во Flash иначе никогда не появится валидная запись, геттеры https_get_*
   * вечно будут возвращать false, а поля настроек в UI останутся пустыми.
   * При usehttps=0 ошибка записи не фатальна — HTTP работает и без TLS. */
  if (!initialize_https_settings()) {
    printf("initialize_https_settings failed\r\n");
    if (SetSettings.usehttps == 1) {
      Error_Handler();
    }
  }
  /* Обновляем кэш настроек: mysett_cache_reload() в StartConfigTask мог
   * отработать до появления валидной записи во Flash и закэшировать
   * пустые поля. */
  mysett_cache_reload();

  // Инициализация TLS параметров
  struct mg_tcpip_if mif = {.mac = GENERATE_LOCALLY_ADMINISTERED_MAC(),
                            .ip = 0,
                            .mask = 0,
                            .gw = 0,
                            .driver = &mg_tcpip_driver_stm32f,
                            .driver_data = NULL};

  snprintf(g_mac_addr, sizeof(g_mac_addr), "%02X:%02X:%02X:%02X:%02X:%02X",
           mif.mac[0], mif.mac[1], mif.mac[2], mif.mac[3], mif.mac[4], mif.mac[5]);

  MG_INFO(("Initial Generated MAC: %02X:%02X:%02X:%02X:%02X:%02X\r\n",
           mif.mac[0], mif.mac[1], mif.mac[2], mif.mac[3], mif.mac[4],
           mif.mac[5]));

  struct mg_mgr *mgr =
      (struct mg_mgr *)dtcm_malloc(sizeof(struct mg_mgr)); // Одноразовый при загрузке, живёт весь runtime
  mg_mgr_init(mgr);                                   // Инициализируем менеджер

  // Настройка MQTT
  char mqtt_url[70];
  if (SetSettings.check_mqtt && SetSettings.mqtt_hst[0] != '\0') {
    int result = snprintf(mqtt_url, sizeof(mqtt_url), "mqtt://%s:%d",
                          SetSettings.mqtt_hst, SetSettings.mqtt_prt);
    if (result < 0 || result >= sizeof(mqtt_url)) {
      printf("Error: MQTT URL truncated or formatting error\n");
    } else {
      set_mqtt_url(mqtt_url);
      MG_INFO(("MQTT URL set: %s", mqtt_url)); // Добавляем лог для проверки
    }
  } else {
    MG_INFO(("MQTT is disabled in settings"));
  }
  set_mqtt_topic(SetSettings.txmqttop); // Zagotovka

  //    // UUID перед генерацией MAC-адреса
  //    MG_INFO(("UUID before MAC generation:
  //    %02X%02X%02X%02X%02X%02X%02X%02X%02X%02X%02X%02X\r\n",
  //             UUID[0], UUID[1], UUID[2], UUID[3], UUID[4], UUID[5],
  //             UUID[6], UUID[7], UUID[8], UUID[9], UUID[10], UUID[11]));

  // Initialise Mongoose network stack
  struct mg_tcpip_driver_stm32f_data driver_data = {.mdc_cr = 4};
  mif.driver_data = &driver_data;
  MG_INFO(("MAC before static_or_dynamic_ip: %02X:%02X:%02X:%02X:%02X:%02X\r\n",
           mif.mac[0], mif.mac[1], mif.mac[2], mif.mac[3], mif.mac[4],
           mif.mac[5]));

  static_or_dynamic_ip(&mif, &SetSettings);

  mg_tcpip_init(mgr, &mif);

  MG_INFO(("MAC: %M. Waiting for IP...", mg_print_mac, mif.mac));
  LOG_MQTT("[BOOT] t=%lu waiting for IP...\r\n", (unsigned long)HAL_GetTick());
  while (mif.state != MG_TCPIP_STATE_READY) {
    mg_mgr_poll(mgr, 0);
  }
  LOG_MQTT("[BOOT] t=%lu IP ready\r\n", (unsigned long)HAL_GetTick());

  {
    uint8_t *ip_bytes = (uint8_t *)&mif.ip;
    snprintf(g_ip_addr, sizeof(g_ip_addr), "%d.%d.%d.%d", ip_bytes[0], ip_bytes[1], ip_bytes[2], ip_bytes[3]);
    snprintf(g_mac_addr, sizeof(g_mac_addr), "%02X:%02X:%02X:%02X:%02X:%02X", mif.mac[0], mif.mac[1], mif.mac[2], mif.mac[3], mif.mac[4], mif.mac[5]);
  }

  /* Встроенный MQTT-брокер (только если включён в настройках;
     таблица клиентов выделяется в DTCM один раз) */
  if (SetSettings.check_mqtt_srv) {
    mqtt_server_init(mgr, (uint16_t)SetSettings.mqtt_srv_prt);
    LOG_MQTT("[BOOT] t=%lu mqtt_server_init() done, broker on port %d\r\n",
             (unsigned long)HAL_GetTick(), SetSettings.mqtt_srv_prt);

    /* Watchdog автовосстановления шлюза SLZB-06p7U: если шлюз не подключился
     * к брокеру за SLZB_WD_WAIT_MS — перезагружаем его HTTP-запросом.
     * IP берётся из настроек (Settings → MQTT Server → "SLZB IP");
     * пустая строка = watchdog выключен. */
    slzb_watchdog_init(SetSettings.slzb_host);
  }

  /* HA MQTT Discovery: включается настройкой check_ha_disc, работает и без
   * встроенного брокера (через внешний MQTT-клиент). */
  ha_discovery_init();

  LOG_MQTT("[BOOT] t=%lu calling web_init()\r\n", (unsigned long)HAL_GetTick());
  web_init(mgr);
  LOG_MQTT("[BOOT] t=%lu web_init() done\r\n", (unsigned long)HAL_GetTick());

  MqttMessage_t rxMsg = {0};
  BaseType_t status;
  char mqtt_topic[100];
  char mqtt_payload[300];

  static uint32_t lsens_tk = 0;  // Батч-публикация сенсоров: 5000мс
  /* ── Диагностика: задержка между вызовами mg_mgr_poll ── */
  static uint32_t s_poll_warn_tk = 0;
  static uint32_t s_last_poll_tk = 0;
  /* Infinite loop */
  for (;;) {
    /* Измеряем интервал между poll-вызовами */
    uint32_t now_poll = HAL_GetTick();
    uint32_t poll_gap = now_poll - s_last_poll_tk;
    if (s_last_poll_tk != 0) {
      if (poll_gap > mg_poll_gap_peak) {
        mg_poll_gap_peak = poll_gap;
      }
      if (poll_gap > 50) {  /* >50ms = starvation */
        mg_poll_gap_over_50ms_cnt++; // Увеличиваем счетчик
        if (now_poll - s_poll_warn_tk > 30000) {     /* не спамим чаще 1р/30с */
          s_poll_warn_tk = now_poll;
          printf("[NET] WARN: mg_mgr_poll gap=%lums (starvation! total cnt: %lu)\r\n",
                 (unsigned long)poll_gap, (unsigned long)mg_poll_gap_over_50ms_cnt);
        }
      }
    }
    s_last_poll_tk = now_poll;

    uint32_t t_poll = HAL_GetTick();
    mg_mgr_poll(mgr, 0); // Было 10
    t_poll = HAL_GetTick() - t_poll;

    /* Встроенный MQTT-брокер: keepalive-таймауты клиентов (сама проверяет флаг) */
    mqtt_server_poll();
    ha_discovery_poll(s_conn);
    /* Watchdog SLZB-06p7U: автовосстановление связи с шлюзом (сама проверяет,
       что брокер запущен и host задан) */
    slzb_watchdog_poll(mgr);
    /* Статический пик времени выполнения mg_mgr_poll */
    {
      static uint32_t s_poll_exec_peak = 0;
      static uint32_t s_poll_warn_exec_tk = 0;
      if (t_poll > s_poll_exec_peak) {
        s_poll_exec_peak = t_poll;
      }
      if (t_poll > 10) { /* >10ms в одном poll - аномалия */
        if (now_poll - s_poll_warn_exec_tk > 30000) {
          s_poll_warn_exec_tk = now_poll;
          printf("[NET] WARN: mg_mgr_poll exec=%lums (peak=%lu, gap=%lu)\r\n",
                 (unsigned long)t_poll, (unsigned long)s_poll_exec_peak,
                 (unsigned long)poll_gap);
        }
      }
    }

    /* Диагностика пика соединений Mongoose */
    {
      uint32_t active_conns = 0;
      uint32_t n_listeners = 0, n_tls = 0, n_mqtt = 0, n_other = 0;
      unsigned long cur_ids[8] = {0};
      for (struct mg_connection *c = mgr->conns; c != NULL; c = c->next) {
        active_conns++;
        if (c->is_listening)      n_listeners++;
        else if (c->is_tls)       n_tls++;
        else if (c == s_conn)     n_mqtt++;
        else {
          if (n_other < 8) cur_ids[n_other] = c->id;
          n_other++;
        }
      }
      /* OTHER детали — при изменении состава (id набора) */
      bool changed = (n_other != s_other_cnt);
      if (!changed) {
        for (uint32_t i = 0; i < n_other && i < 8; i++) {
          if (cur_ids[i] != s_other_ids[i]) { changed = true; break; }
        }
      }
      static uint32_t s_diag_tk = 0;   /* время последней печати [DIAG] */

      if (changed && (now_poll - s_diag_tk) > 10000) {   /* не чаще раза в 10 с */
        s_diag_tk = now_poll;
        for (struct mg_connection *c = mgr->conns; c != NULL; c = c->next) {
          if (!c->is_listening && !c->is_tls && c != s_conn) {
            char rem_buf[32];
            mg_snprintf(rem_buf, sizeof(rem_buf), "%M", mg_print_ip_port, &c->rem);
            printf("[DIAG] OTHER conn id=%lu rem=%s client=%d\r\n",
                   c->id, rem_buf, c->is_client);
          }
        }
        memcpy(s_other_ids, cur_ids, sizeof(s_other_ids));
        s_other_cnt = n_other;
      }
      mg_conn_cur = active_conns;
      mg_conn_listeners = n_listeners;
      mg_conn_tls = n_tls;
      mg_conn_mqtt = n_mqtt;
      mg_conn_other = n_other;
      mg_conn_mqttsrv = mqtt_server_client_count();
      if (active_conns > mg_conn_peak) {
        mg_conn_peak = active_conns;
      }
    }

    /* Обработка входящих MQTT-команд (вынесена из fn_mqtt callback,
       чтобы не блокировать mg_mgr_poll) */
    {
        uint32_t cur_rx = uxQueueMessagesWaiting(mqttRxQueueHandle);
        if (cur_rx > mqtt_rx_peak) {
            mqtt_rx_peak = cur_rx;
        }
        MqttRxMsg_t rx;
        while (xQueueReceive(mqttRxQueueHandle, &rx, 0) == pdPASS) {
            mqtt_message_handler(rx.topic, rx.payload);
        }
    }

    /* Обработка исходящих Zigbee-команд */
    {
        ZbeeCmdMsg_t zcmd;
        {
            uint32_t cur_zbee = uxQueueMessagesWaiting(zbeeCmdQueueHandle);
            if (cur_zbee > zbee_cmd_peak) {
                zbee_cmd_peak = cur_zbee;
            }
        }
        while (xQueueReceive(zbeeCmdQueueHandle, &zcmd, 0) == pdPASS) {
            /* Локальный MQTT-сервер: публикация команд независимо от внешнего брокера */
            mqtt_server_publish(zcmd.topic, zcmd.payload);
            if (s_conn != NULL && mqtt_connected_reported) {
                struct mg_mqtt_opts pub_opts;
                memset(&pub_opts, 0, sizeof(pub_opts));
                pub_opts.topic = mg_str(zcmd.topic);
                pub_opts.message = mg_str(zcmd.payload);
                pub_opts.qos = s_qos;
                pub_opts.retain = false;
                mg_mqtt_pub(s_conn, &pub_opts);
                LOG_Z2M("zbee: MQTT PUB topic='%s'\r\n", zcmd.topic);
            }
            /* Внешний брокер не подключён — НЕ дроп: локальная публикация
             * (mqtt_server_publish выше) всегда доставляет команды шлюзу. */
        }
    }

    /* Explicit drain: rapidly clear the queue if disconnected to avoid buildup.
     * НЕ дренажим, если работает локальный MQTT-сервер (check_mqtt_srv=1) —
     * в этом случае у сообщений есть получатель (mqtt_server_publish) даже
     * без внешнего брокера. Дренаж нужен только когда единственный потребитель —
     * внешний клиент, и он не подключён. */
    if (!SetSettings.check_mqtt_srv &&
        (s_conn == NULL || s_conn->is_closing || !mqtt_connected_reported)) {
      MqttMessage_t drain;
      while (xQueueReceive(mqttQueueHandle, &drain, 0) == pdPASS) {
        /* Drop silently */
      }
    }

    // Получаем данные из очереди (не блокируем поток Mongoose)
    memset(&rxMsg, 0, sizeof(MqttMessage_t));
    {
      uint32_t cur_tx = uxQueueMessagesWaiting(mqttQueueHandle);
      if (cur_tx > mqtt_tx_peak) {
        mqtt_tx_peak = cur_tx;
      }
    }
    status = xQueueReceive(mqttQueueHandle, &rxMsg, 0);
    if (status == pdPASS) {
			// printf("[MQTT_Q] cmd=%d dev=%d state=%d\r\n", rxMsg.command,rxMsg.deviceId, rxMsg.state);
      /* Защита от повреждённых сообщений в очереди */
      /* cmd 11 (ZIGBEE SECURITY) несёт индекс слота ZigbeeConf, а не id пина.
       * cmd 3/4/5 валидны и для Zigbee-кнопок (deviceId = логический 90..289). */
      bool zbee_btn_ev = (IsZigbeePin(rxMsg.deviceId) &&
                          (rxMsg.command == 3 || rxMsg.command == 4 || rxMsg.command == 5));
      bool phys_dev = (rxMsg.deviceId < NUMPIN);
      if (!phys_dev && rxMsg.command != 1 && rxMsg.command != 11 && !zbee_btn_ev) {
        printf("MQTT queue: invalid deviceId=%d, cmd=%d — skipped\r\n", rxMsg.deviceId, rxMsg.command);
      } else {
      switch (rxMsg.command) {
      case 1: // DEVICE
        if (rxMsg.deviceId < NUMPIN &&
            SetSettings.txmqttop[0] != '\0' && (SetSettings.check_mqtt == 1 || SetSettings.check_mqtt_srv == 1)) {
          memset(mqtt_topic, 0, sizeof(mqtt_topic));
          memset(mqtt_payload, 0, sizeof(mqtt_payload));
          strcpy(mqtt_topic, "/device/");
          snprintf(mqtt_payload, sizeof(mqtt_payload), "DEVICE(s)/ACTION=%s", PinsConf[rxMsg.deviceId].sclick);
          send_mqtt_message(s_conn, mqtt_topic, mqtt_payload);
        } else if (SetSettings.check_mqtt == 1) {
          printf("Error: MQTT settings not configured\r\n");
        }
        break;
      case 2: // Switch
        if (SetSettings.txmqttop[0] != '\0' && (SetSettings.check_mqtt == 1 || SetSettings.check_mqtt_srv == 1)) {
          memset(mqtt_topic, 0, sizeof(mqtt_topic));
          memset(mqtt_payload, 0, sizeof(mqtt_payload));
          snprintf(mqtt_topic, sizeof(mqtt_topic), "/switch/");
          snprintf(mqtt_payload, sizeof(mqtt_payload), "ID:%d=%s",
                   rxMsg.deviceId < NUMPIN ? rxMsg.deviceId + 1 : rxMsg.deviceId,
                   rxMsg.state ? "ON" : "OFF");
          send_mqtt_message(s_conn, mqtt_topic, mqtt_payload);
        } else if (SetSettings.check_mqtt == 1) {
          printf("Error: MQTT settings not configured\r\n");
        }
        break;
      case 3: // BUTTON LONG_PRESS
      case 4: // BUTTON SINGLE_CLICK
      case 5: // BUTTON DOUBLE_CLICK
        if (SetSettings.txmqttop[0] != '\0' && (SetSettings.check_mqtt == 1 || SetSettings.check_mqtt_srv == 1)) {
          memset(mqtt_topic, 0, sizeof(mqtt_topic));
          memset(mqtt_payload, 0, sizeof(mqtt_payload));
          snprintf(mqtt_topic, sizeof(mqtt_topic), "/button/");
          if (IsZigbeePin(rxMsg.deviceId)) {
            /* Zigbee-кнопка: действия в пуле, а не в PinsConf (иначе OOB) */
            int zbi = ZbeeIdx(rxMsg.deviceId);
            const char *zact = (rxMsg.command == 3) ? zbee_action_lpress(zbi)
                             : (rxMsg.command == 4) ? zbee_action_sclick(zbi)
                             : zbee_action_dclick(zbi);
            const char *zname = (rxMsg.command == 3) ? "LONG_PRESS"
                              : (rxMsg.command == 4) ? "SINGLE_CLICK" : "DOUBLE_CLICK";
            snprintf(mqtt_payload, sizeof(mqtt_payload), "ID=%d/%s/%s",
                     rxMsg.deviceId, zname, zact);
          } else {
            switch (rxMsg.command) {
            case 3: snprintf(mqtt_payload, sizeof(mqtt_payload), "ID=%d/LONG_PRESS/%s", rxMsg.deviceId + 1, PinsConf[rxMsg.deviceId].lpress); break;
            case 4: snprintf(mqtt_payload, sizeof(mqtt_payload), "ID=%d/SINGLE_CLICK/%s", rxMsg.deviceId + 1, PinsConf[rxMsg.deviceId].sclick); break;
            case 5: snprintf(mqtt_payload, sizeof(mqtt_payload), "ID=%d/DOUBLE_CLICK/%s", rxMsg.deviceId + 1, PinsConf[rxMsg.deviceId].dclick); break;
            }
          }
          send_mqtt_message(s_conn, mqtt_topic, mqtt_payload);
        } else if (SetSettings.check_mqtt == 1) {
          printf("Error: MQTT settings not configured\r\n");
        }
        break;
      case 6: // SECURITY
        if (SetSettings.txmqttop[0] != '\0' && (SetSettings.check_mqtt == 1 || SetSettings.check_mqtt_srv == 1)) {
          memset(mqtt_topic, 0, sizeof(mqtt_topic));
          memset(mqtt_payload, 0, sizeof(mqtt_payload));
          snprintf(mqtt_topic, sizeof(mqtt_topic), "/security/");
          snprintf(mqtt_payload, sizeof(mqtt_payload), "SECURITY/ID=%d/ACTION=%s/%s", rxMsg.deviceId + 1, PinsConf[rxMsg.deviceId].sclick, PinsConf[rxMsg.deviceId].info);
          send_mqtt_message(s_conn, mqtt_topic, mqtt_payload);
        } else if (SetSettings.check_mqtt == 1) {
          printf("Error: MQTT settings not configured\r\n");
        }
        break;
      case 11: // ZIGBEE SECURITY (deviceId = индекс слота ZigbeeConf)
        if (rxMsg.deviceId < NUMZBEE &&
            SetSettings.txmqttop[0] != '\0' && (SetSettings.check_mqtt == 1 || SetSettings.check_mqtt_srv == 1)) {
          memset(mqtt_topic, 0, sizeof(mqtt_topic));
          memset(mqtt_payload, 0, sizeof(mqtt_payload));
          snprintf(mqtt_topic, sizeof(mqtt_topic), "/security/");
          snprintf(mqtt_payload, sizeof(mqtt_payload), "SECURITY/ID=%d/ACTION=%s/%s",
                   ZbeeIdFromIdx(rxMsg.deviceId), zbee_action_sclick(rxMsg.deviceId),
                   ZigbeeConf[rxMsg.deviceId].zbee_label);
          send_mqtt_message(s_conn, mqtt_topic, mqtt_payload);
        } else if (SetSettings.check_mqtt == 1) {
          printf("Error: MQTT settings not configured\r\n");
        }
        break;
      case 7: // TIMER — заменён на send_mqtt_timer_batch()
      case 9: // PWM_TIMER — заменён на send_mqtt_timer_batch()
        break; // no-op: батч обрабатывает всё
      case 8: // OnOff
        if (SetSettings.txmqttop[0] != '\0' && (SetSettings.check_mqtt == 1 || SetSettings.check_mqtt_srv == 1)) {
          memset(mqtt_topic, 0, sizeof(mqtt_topic));
          memset(mqtt_payload, 0, sizeof(mqtt_payload));
          snprintf(mqtt_topic, sizeof(mqtt_topic), "/onoff/");
          int written = snprintf(mqtt_payload, sizeof(mqtt_payload),
                                 "ID=%d/OnOff=%s/%s",
                                 rxMsg.deviceId + 1,
                                 PinsConf[rxMsg.deviceId].onoff ? "ON" : "OFF",
                                 PinsConf[rxMsg.deviceId].info);
          if (written < 0 || (size_t)written >= sizeof(mqtt_payload)) {
            printf("[MQTT] payload truncated for deviceId=%d, skipping\r\n",
                   rxMsg.deviceId);
            break;
          }
          send_mqtt_message(s_conn, mqtt_topic, mqtt_payload);
        } else if (SetSettings.check_mqtt == 1) {
          printf("Error: MQTT settings not configured\r\n");
        }
        break;
      default:
        printf("mqttnum = %d \r\n", mqttnum);
        break;
      }
      } /* end of deviceId bounds guard */
    }
    // Батч-публикация всех сенсоров (DS18B20 + DHT22 + PWM) одним JSON-пакетом
    // раз в 5 секунд. Гистерезис применяется внутри publish_sensor_batch().
    // Для Home Assistant / Node-RED обновление раз в 5с более чем достаточно.
    {
          uint32_t now = HAL_GetTick();

          if (now - lsens_tk >= 5000) {
	  lsens_tk = now;
            /* Публикуем и при выключенном внешнем брокере — если локальный
               MQTT-сервер включён (publish_sensor_batch сам разрулит conn==NULL) */
            if (SetSettings.check_mqtt_srv ||
                (s_conn != NULL && mqtt_connected_reported && !s_conn->is_connecting && !s_conn->is_closing && !s_conn->is_draining)) {
              publish_sensor_batch(s_conn);
            }
          }
        }

    /* Батч-публикация таймеров раз в 1 секунду (только при изменениях) */
    {
          static uint32_t ltim_tk = 0;
          uint32_t now = HAL_GetTick();
          if (now - ltim_tk >= 1000) {
              ltim_tk = now;
              /* Публикуем и при выключенном внешнем брокере — если локальный
                 MQTT-сервер включён (send_mqtt_timer_batch сам разрулит conn==NULL) */
              if (SetSettings.check_mqtt_srv ||
                  (s_conn != NULL && mqtt_connected_reported &&
                   !s_conn->is_connecting && !s_conn->is_closing && !s_conn->is_draining)) {
                  send_mqtt_timer_batch(s_conn);
              }
          }
    }

    /* Проверка таймаутов зондов возможностей zigbee-устройств */
    zbee_probe_check_timeout();
    zbee_learn_check_timeout();

    osDelay(1); /* Yield CPU to RTOS, preventing 100% CPU loop starvation */
  }
  mg_mgr_free(mgr);
  /* USER CODE END StartWebServerTask */
}

/* USER CODE END 4 */

void StartConfigTask(void *argument)
{
  /* init code for USB_HOST */
  MX_USB_HOST_Init();
  /* USER CODE BEGIN 5 */
  /* Infinite loop */
  int usbflag = 1;
  FILINFO finfo;
  uint32_t t_boot = HAL_GetTick();
  bool degraded = false;  /* деградировали: флешки не было при старте либо FSERR */
  bool mounted = false;   /* том смонтирован и проверен (только этой задачей) */
  uint8_t mount_fail = 0;
#define USB_BOOT_WAIT_MS 10000u /* окно ожидания флешки при старте */
  for (;;) {
	    switch (Appli_state) {
	    case APPLICATION_READY:
	      if (!mounted) {
	        /* Пауза из прежнего osDelay в колбэке CONNECTION: за 1 с
	         * очередь USB (диск) успевает стабилизироваться после подключения. */
	        osDelay(1000);
	        if (Appli_state != APPLICATION_READY) break; /* флешку успели вынуть */
	        if (f_mount(&USBHFatFS, (const TCHAR*) USBHPath, 1) != FR_OK ||
	            (usbflag == 1 && !usb_probe_all())) {
	          f_mount(NULL, (const TCHAR*) USBHPath, 0);
	          /* Пока пробовали файлы, очередь могла накопить несохранённое */
	          while (xQueueReceive(usbQueueHandle, &usbnum, 0) == pdTRUE)
	            usb_unsaved_add(usbnum);
	          if (++mount_fail >= 3 && !degraded) {
	            degraded = true;
	            usb_state_set(USB_ST_FSERR);
	            if (usbflag == 1) SetSettingsRamDefaults(); /* RAM-дефолты веба */
	            xTaskNotifyGive(WebServerTaskHandle);
	          }
	          osDelay(2000); /* следующая попытка через ~3 с */
	          break;
	        }
	        mount_fail = 0;
	        if (degraded && usbflag == 1) {
	          /* Деградировали при старте, накопитель появился: путь загрузки
	           * рассчитан на один проход — самый безопасный вариант ребут. */
	          osDelay(1000);
	          NVIC_SystemReset();
	        }
	        degraded = false;
	        mounted = true;
	        usb_state_set(USB_ST_OK);
	        if (usbflag == 1) {
	        // Каждый .ini-файл загружается НЕЗАВИСИМО от наличия остальных:
	        // если файл найден на флешке — читаем его (Get*Config), если файла
	        // нет — создаём его с настройками по умолчанию (Set*Config /
	        // StartSettingsConfig).

	        if (f_stat("settings.ini", &finfo) == FR_OK) {
	          GetSettingsConfig(); // "settings.ini" существует — читаем его
	          mysett_cache_reload();
	          /* Категория Z2M (бит 10) добавлена позже старой маски 0x3FF:
	           * в конфигах, сохранённых старой прошивкой, этого бита нет, и
	           * вся zbee-диагностика (LOG_Z2M) молча пропадает из лога.
	           * Включаем принудительно. */
	          SetSettings.log_filter_mask |= LOG_MASK_Z2M;
	          g_log_filter_mask = g_log_filter_from_file ? SetSettings.log_filter_mask : LOG_MASK_ALL;
	        } else {
	          StartSettingsConfig(); // "settings.ini" не существует — создаём с настройками по умолчанию
	          g_log_filter_mask = LOG_MASK_ALL;
	        }

	        if (f_stat("cron.ini", &finfo) == FR_OK) {
	          GetCronConfig(); // "cron.ini" существует — читаем его
	        } else {
	          SetCronConfig(); // "cron.ini" не существует — создаём его
	        }

	        if (f_stat("pins.ini", &finfo) == FR_OK) {
	          GetPinConfig(); // "pins.ini" существует — читаем его
	        } else {
	          SetPinConfig(); // "pins.ini" не существует — создаём его
	        }

	        /* Встроенный пул выражений условий читаем ПЕРВЫМ: номера слотов в
	         * pintopin.ini/pid.ini ссылаются именно на него. */
	        if (f_stat("cond.ini", &finfo) == FR_OK) {
	          GetCondPool(); // "cond.ini" существует — читаем его
	        } else {
	          SetCondPool(); // "cond.ini" не существует — создаём его
	        }

	        if (f_stat("pintopin.ini", &finfo) == FR_OK) {
	          GetPinToPin(); // "pintopin.ini" существует — читаем его
	        } else {
	          SetPinToPin(); // "pintopin.ini" не существует — создаём его
	        }

	        if (f_stat("onewire.ini", &finfo) == FR_OK) {
	          GetOneWireConfig(); // "onewire.ini" существует — читаем его
	        } else {
	          SetOneWireConfig(); // "onewire.ini" не существует — создаём его
	        }

	        if (f_stat("pid.ini", &finfo) == FR_OK) {
	          GetPidConfig(); // "pid.ini" существует — читаем его
	        } else {
	          SetPidConfig(); // "pid.ini" не существует — создаём его
	        }

	        if (f_stat("zigbee.ini", &finfo) == FR_OK) {
	          GetZigbeeConfig(); // "zigbee.ini" существует — читаем его
	        } else {
	          SetZigbeeConfig(); // "zigbee.ini" не существует — создаём его
	        }

	        /* Последнее состояние выходов (режим Power On State = LAST).
	         * GetLastState() сам проверяет обе копии (laststate.ini и
	         * laststate2.ini) и берёт самую новую валидную; файлов может не быть -
	         * тогда все выходы считаются выключенными. */
	        GetLastState();

	        InitPin(); // Инициализация пинов — теперь всегда выполняется после всех загрузок,
	                   // независимо от того, какие файлы нашлись, а какие были созданы заново

	        if (SetSettings.sim800l == 1) { // Если модуль sim800l включен
	          xTaskNotifyGive(
	              SIM800LTaskHandle); // ТО ВКЛЮЧАЕМ ЗАДАЧУ SIM800LTask
	          ulTaskNotifyTake(pdTRUE,
	                           portMAX_DELAY); // Ждем уведомления от SIM800LTask
	        }

	        xTaskNotifyGive(
	            WebServerTaskHandle);          // ТО ВКЛЮЧАЕМ ЗАДАЧУ WebServerTask
	        xTaskNotifyGive(CronTaskHandle);   // И ВКЛЮЧАЕМ ЗАДАЧУ CronTask
	        xTaskNotifyGive(OutputTaskHandle); // И ВКЛЮЧАЕМ ЗАДАЧУ OutputTask
	        xTaskNotifyGive(InputTaskHandle);  // И ВКЛЮЧАЕМ ЗАДАЧУ InputTask
	        xTaskNotifyGive(EncoderTaskHandle); // И ВКЛЮЧАЕМ ЗАДАЧУ PWMTask

	        xTaskNotifyGive(ServiceTaskHandle);  // И ВКЛЮЧАЕМ ЗАДАЧУ TechnolTask
	        xTaskNotifyGive(SecurityTaskHandle); // И ВКЛЮЧАЕМ ЗАДАЧУ SecurityTask

	        osDelay(100);
	        xTaskNotifyGive(ds18b20TaskHandle); // И ВКЛЮЧАЕМ ЗАДАЧУ ds18b20
	        xTaskNotifyGive(dht22TaskHandle);   // И ВКЛЮЧАЕМ ЗАДАЧУ dht22
	        xTaskNotifyGive(PIDTaskHandle);     // И ВКЛЮЧАЕМ ЗАДАЧУ PIDTask
	        xTaskNotifyGive(my_DgnTaskHandle);  // И ВКЛЮЧАЕМ ЗАДАЧУ DgnTask

	        usbflag = 0;
	      } else if (g_usb_unsaved_mask) {
	        /* Возврат флешки после LOSS: доигрываем накопленные сохранения */
	        for (uint8_t k = 1; k <= 9; k++)
	          if (g_usb_unsaved_mask & (1u << k)) {
	            uint8_t u = k;
	            xQueueSend(usbQueueHandle, &u, 0);
	          }
	        usb_unsaved_clear();
	      }
      } /* if (!mounted) */
	      // Функция для чтения целых чисел из очереди (с таймаутом, чтобы
	      // заметить смену Appli_state, даже если очередь молчит)
	      if (xQueueReceive(usbQueueHandle, &usbnum, pdMS_TO_TICKS(200)) == pdTRUE) {
	        {
	          uint32_t cur_usb = uxQueueMessagesWaiting(usbQueueHandle) + 1;
	          if (cur_usb > usb_peak) {
	            usb_peak = cur_usb;
	          }
	        }
	        if (Appli_state != APPLICATION_READY) {
	          /* накопитель пропал, пока ждали — не пишем, запоминаем */
	          usb_unsaved_add(usbnum);
	          break;
	        }
	        switch (usbnum) {
	        case 1:
	          SetPinConfig(); // Сохранение конфигурации пинов в "pins.ini"
	          break;
case 2:
          SetSettingsConfig(); // Когда сохраняем форму в файл "setings.ini"
          /* Конфигурация сохранена: счётчики использования условий и пул
           * выражений на странице Global Settings изменились. */
          mark_slice_dirty(&g_ver_settings);
          /* Может смениться язык (lang): он отдаётся в /api/state/common
           * для USB-баннера — инвалидируем и ETag common. */
          mark_slice_dirty(&g_ver_common);
          break;
	        case 3:
	          SetCronConfig(); // Сохранение конфигурации cron в "cron.ini"
	          break;
	        case 4:
	          SetPinToPin(); // Сохранение pin-to-pin связей в "pintopin.ini"
	          break;
	        case 5:
	          SetOneWireConfig(); // Сохранение конфигурации OneWire в "onewire.ini"
	          break;
	        case 6:
	          SetPidConfig(); // Сохранение PID конфигурации в "pid.ini"
	          break;
	        case 7:
	          SetZigbeeConfig(); // Сохранение Zigbee конфигурации в "zigbee.ini"
	          break;
	        case 8:
	          SetCondPool(); // Сохранение встроенных выражений условий в "cond.ini"
	          break;
	        case 9:
	          SetLastState(); // Сохранение последнего состояния (laststate.ini / laststate2.ini)
	          break;
	        default:
	          printf("xQueueReceive get wrong data! \r\n");
	          break;
	        }
	        // printf("xQueueReceive number: %u\n",
	        // usbnum);
	      }
	      break;
	    default:
	      /* Накопитель недоступен. Все файловые операции идут из этой
	       * задачи, поэтому размонтирование отсюда безопасно (раньше
	       * f_mount выполнялось из колбэка USBH и гонилось с записью). */
	      if (mounted) {
	        mounted = false;
	        f_mount(NULL, (const TCHAR*) USBHPath, 0);
	        if (g_usb_state == USB_ST_OK) usb_state_set(USB_ST_LOST);
	      } else if (g_usb_state == USB_ST_FSERR) {
	        usb_state_set(USB_ST_ABSENT); /* FSERR-накопитель вынули */
	      }
	      /* Ответы на сохранение, пришедшие без накопителя: в маску */
	      while (xQueueReceive(usbQueueHandle, &usbnum, 0) == pdTRUE)
	        usb_unsaved_add(usbnum);
	      if (usbflag == 1 && !degraded && (HAL_GetTick() - t_boot) > USB_BOOT_WAIT_MS) {
	        degraded = true;                 /* состояние остаётся USB_ST_ABSENT */
	        SetSettingsRamDefaults();        /* веб стартует с RAM по умолчанию */
	        xTaskNotifyGive(WebServerTaskHandle);
	      }
	      break;
	    }
	    osDelay(1);
	  }
  /* USER CODE END 5 */
}

void StartOutputTask(void *argument)
{
  /* USER CODE BEGIN StartOutputTask */
  ulTaskNotifyTake(0, portMAX_DELAY);
  //	printf("Start 'Output' task \r\n");
  /* Infinite loop */
  for (;;) {
    data_pin_t data_pin = {0}; /* A3: локальная копия для xQueueReceive */
    if (xQueueReceive(outputQueueHandle, &data_pin, portMAX_DELAY) == pdTRUE) {
      {
        uint32_t cur_out = uxQueueMessagesWaiting(outputQueueHandle) + 1;
        if (cur_out > output_peak) {
          output_peak = cur_out;
        }
      }
      if (IsPinId(data_pin.id) || IsZigbeePin(data_pin.id)) {
        if (IsZigbeePin(data_pin.id)) {
          int zbi = ZbeeIdx(data_pin.id);
          if (ZigbeeConf[zbi].zbee_role == ZBEE_ROLE_SWITCH) {
            printf("[OUT] SKIP: slot %d is SWITCH, not actuator\r\n", zbi);
          } else if (ZigbeeConf[zbi].zbee_ieee[0] != '\0' && ZigbeeConf[zbi].onoff) {
            /* multi-EP команда — отправка на конкретный EP */
            if (ZigbeeConf[zbi].ep_onoff > 0) {
              const char *val_str;
              char valbuf[8];
              if (ZigbeeConf[zbi].cluster_flags & ZBEE_CL_ONOFF) {
                val_str = (data_pin.action == 1 || (data_pin.action == 2 && !ZigbeeConf[zbi].state)) ? "1" : "0";
              } else if (ZigbeeConf[zbi].cluster_flags & ZBEE_CL_DIMMER) {
                snprintf(valbuf, sizeof(valbuf), "%d", ZigbeeConf[zbi].dvalue);
                val_str = valbuf;
              } else {
                val_str = "0";
              }
              extern void SendZigbeeEPCommand(const char *ieee, uint8_t ep, uint16_t dp, const char *val);
              SendZigbeeEPCommand(ZigbeeConf[zbi].zbee_ieee,
                                    ZigbeeConf[zbi].zbee_endpoint,
                                    ZigbeeConf[zbi].ep, val_str);
            } else {
              /* Стандартная ZCL-команда */
              const char *cmd;
              if (data_pin.action == 2) {
                /* TOGGLE — инвертируем текущее состояние */
                cmd = (ZigbeeConf[zbi].state) ? "OFF" : "ON";
              } else {
                cmd = (data_pin.action == 1) ? "ON" : "OFF";
              }
              uint8_t flags = ZigbeeConf[zbi].cluster_flags;
              if (flags & ZBEE_CL_ONOFF) {
                SendZigbeeCommand(ZigbeeConf[zbi].zbee_ieee,
                                  ZigbeeConf[zbi].zbee_endpoint,
                                  6, ZBEE_ATTR_ONOFF, cmd);
              }
              if (flags & ZBEE_CL_DIMMER) {
                char valbuf[8];
                snprintf(valbuf, sizeof(valbuf), "%d", ZigbeeConf[zbi].dvalue);
                SendZigbeeCommand(ZigbeeConf[zbi].zbee_ieee,
                                  ZigbeeConf[zbi].zbee_endpoint,
                                  8, ZBEE_ATTR_DIMMER, valbuf);
              }
              if (flags & ZBEE_CL_COLOR) {
                char valbuf[12];
                /* SLZB-OS: цвет принимается на 0300/0007 в формате #RRGGBB
                 * (тот же формат, что в веб-обработчике цвета) */
                snprintf(valbuf, sizeof(valbuf), "#%06X",
                         (unsigned) (ZigbeeConf[zbi].color_hex & 0xFFFFFF));
                SendZigbeeCommand(ZigbeeConf[zbi].zbee_ieee,
                                  ZigbeeConf[zbi].zbee_endpoint,
                                  768, 0x0007, valbuf);
              }
            }
          }
        } else {
          switch (data_pin.action) {
          case 0:
            HAL_GPIO_WritePin(PinsInfo[data_pin.id - 1].gpio_name,
                              PinsInfo[data_pin.id - 1].hal_pin, GPIO_PIN_RESET);
            break;
          case 1:
            HAL_GPIO_WritePin(PinsInfo[data_pin.id - 1].gpio_name,
                              PinsInfo[data_pin.id - 1].hal_pin, GPIO_PIN_SET);
            break;
          case 2:
            HAL_GPIO_TogglePin(PinsInfo[data_pin.id - 1].gpio_name,
                               PinsInfo[data_pin.id - 1].hal_pin);
            break;
          default:
            printf("Invalid action: %d\r\n", data_pin.action);
            break;
          }
        }
      } else {
        printf("Invalid pin number: %d\r\n", data_pin.id);
      }
    }
    osDelay(1);
  }
  /* USER CODE END StartOutputTask */
}

/* USER CODE BEGIN Header_StartCronTask */
/**
 * @brief Function implementing the CronTask thread.
 * @param argument: Not used
 * @retval None
 */
#define CRON_POLL_MS  50   /* период проверки смены секунды в CronTask, мс */

extern volatile uint8_t g_cron_dirty[NUMTASK];

/* Разбор одной строки Cron в её контекст. Вызывается только из CronTask, поэтому
 * сам контекст не требует защиты; строка копируется под критической секцией.
 * Ошибка разбора или пустая строка: контекст обнуляется, строка не срабатывает,
 * остальные строки не затрагиваются. */
static void cron_reparse_one(lwdtc_cron_ctx_t *ctxs, int idx)
{
  char tmp[sizeof(dbCrontxt[0].cron)];

  taskENTER_CRITICAL();
  memcpy(tmp, dbCrontxt[idx].cron, sizeof(tmp));
  taskEXIT_CRITICAL();
  tmp[sizeof(tmp) - 1] = '\0';

  memset(&ctxs[idx], 0, sizeof(ctxs[idx]));
  if (tmp[0] == '\0') return;
  if (lwdtc_cron_parse_with_len(&ctxs[idx], tmp, strlen(tmp)) != lwdtcOK) {
    memset(&ctxs[idx], 0, sizeof(ctxs[idx]));
    printf("Failed to parse cron at index %d\r\n", idx);
  }
}

/* USER CODE END Header_StartCronTask */
void StartCronTask(void *argument)
{
  /* USER CODE BEGIN StartCronTask */
  ulTaskNotifyTake(0, portMAX_DELAY);
  init_offline_time();
  /* cron_ctxs выделяется в DTCM через dtcm_cron_ctxs (см. dtcm_alloc.h) */
  lwdtc_cron_ctx_t *cron_ctxs = dtcm_cron_ctxs;
  int i = 0;
  char str[sizeof(dbCrontxt[0].activ)] = {0};
  int cfg_tasks = NUMTASK; // Количество возможно настроенных cron задач
  time_t base_timestamp;
  static uint8_t t_printd = 0;

  base_timestamp = initializeTime(); // Инициализация базового времени

  /* Define context for CRON, used to parse data to */
  for (int ci = 0; ci < NUMTASK; ci++) {
    g_cron_dirty[ci] = 0;
    cron_reparse_one(cron_ctxs, ci);  // каждая строка независимо: ошибка не блокирует остальные
  }
  printf("CRONs parsed and ready to go\r\n");
  /* Infinite loop */
  for (;;) {
    if (s_boot_timestamp != 0) {
      if (!onlineFlg) { // Оффлайн режим:
        cronetime = base_timestamp + (mg_millis() / 1000);
      } else { // Онлайн режим: используем время от NTP
        float tz;
        taskENTER_CRITICAL();
        tz = SetSettings.timezone;
        taskEXIT_CRITICAL();
        cronetime = (time_t)(s_boot_timestamp / 1000) + (mg_millis() / 1000) +
                    (time_t)(tz * 3600);
      }

      if (!t_printd && cronetime != 0) {
        { struct tm *tmp = localtime(&cronetime); if (tmp) memcpy(&timez_copy, tmp, sizeof(timez_copy)); }
        taskENTER_CRITICAL();
        if (!onlineFlg) {
          printf("[OFFLINE MODE] Initial Date:%02d.%02d.%04d "
                 "Time:%02d:%02d:%02d\r\n",
                 timez_copy.tm_mday, timez_copy.tm_mon + 1, timez_copy.tm_year + 1900,
                 timez_copy.tm_hour, timez_copy.tm_min, timez_copy.tm_sec);
        } else {
          printf("[ONLINE MODE] Initial Date:%02d.%02d.%04d "
                 "Time:%02d:%02d:%02d IP:%s MAC:%s\r\n",
                 timez_copy.tm_mday, timez_copy.tm_mon + 1, timez_copy.tm_year + 1900,
                 timez_copy.tm_hour, timez_copy.tm_min, timez_copy.tm_sec,
                 g_ip_addr, g_mac_addr);
        }
        taskEXIT_CRITICAL();
        t_printd = 1;
        printf("[SYSTEM] Reset CSR=0x%08lX\r\n", reset_csr_value);
        printf("[SYSTEM] Reset flags: %s\r\n", reset_reason_str);
        printf("[SYSTEM] Reset reason: %s (CSR=0x%08lX)\r\n", reset_reason_str, reset_csr_value);
        // printf("[SYSTEM][BOOT] FW=%s NUMPIN=%d NUMZBEE=%d\r\n",
        //        FW_VERSION, NUMPIN, NUMZBEE);
        // printf("[SYSTEM][BOOT] Compiled: %s %s\r\n", __DATE__, __TIME__);
        // printf("[SYSTEM][BOOT] sizeof(ZigbeeConf)=%d\r\n",
        //        (int)sizeof(ZigbeeVirtualPin));
      }

      if (cronetime != cronetime_old) {
        cronetime_old = cronetime;
        { struct tm *tmp = localtime(&cronetime); if (tmp) memcpy(&timez_copy, tmp, sizeof(timez_copy)); }
        timez_copy.tm_mon += 1;

        // Эти переменные нужны для задачи ServiceTask!
        if (timez_copy.tm_mday !=
            day) { // Если текущий день отличается от сохраненного
          year = timez_copy.tm_year + 1900;
          month = timez_copy.tm_mon; // Не добавляем 1, так как уже сделано выше
          day = timez_copy.tm_mday;
        }

        static int last_min = -1;
        if (timez_copy.tm_min != last_min) {
            if (last_min != -1) {
                taskENTER_CRITICAL();
//                printf("[MQTT] sent=%lu per minute\r\n", (unsigned long)mqtt_sent_count);
                mqtt_sent_count = 0;
                taskEXIT_CRITICAL();
            }
            last_min = timez_copy.tm_min;
        }

        // printf("CronTask: today's date:
        // %02d.%02d.%d\n", day, month, year);
        // Обработка задач с фиксированным временем
        i = 0;
        while (i < cfg_tasks) {
          time_t ptime;
          taskENTER_CRITICAL();
          ptime = dbCrontxt[i].ptime;
          taskEXIT_CRITICAL();

          if (cronetime >= ptime && ptime != 0) {
            taskENTER_CRITICAL();
            memcpy(str, dbCrontxt[i].activ, sizeof(str) - 1);
            dbCrontxt[i].ptime = 0;
            taskEXIT_CRITICAL();
            str[sizeof(str) - 1] = '\0';  // снаружи CS

            parse_string(str, cronetime_old, i, 1);
          }
          i++;
        }
        // Проверка CRON выражений
        i = 0;
        while (i < NUMTASK) {
          if (lwdtc_cron_is_valid_for_time(&timez_copy, cron_ctxs, &i) == lwdtcOK) {
            taskENTER_CRITICAL();
            memcpy(str, dbCrontxt[i].activ, sizeof(str) - 1);
            taskEXIT_CRITICAL();
            str[sizeof(str) - 1] = '\0';  // снаружи CS

            parse_string(str, cronetime_old, i, 0);
          }
          i++;
        }
        timez_copy.tm_mon -= 1;
      }
    }
    /* Строки Cron, изменённые через веб (/api/cron/set) или загруженные из cron.ini */
    for (int di = 0; di < NUMTASK; di++) {
      if (g_cron_dirty[di]) {
        g_cron_dirty[di] = 0;
        cron_reparse_one(cron_ctxs, di);
      }
    }
    /* Cron работает с точностью до секунды: проверка раз в CRON_POLL_MS (50 мс)
     * вместо 1 мс. Секундная граница определяется с задержкой до 50 мс.
     * Заодно в онлайн-режиме в 50 раз реже берётся критическая секция
     * для чтения SetSettings.timezone. */
    osDelay(CRON_POLL_MS);
  }
  /* USER CODE END StartCronTask */
}

void StartInputTask(void *argument)
{
  /* USER CODE BEGIN StartInputTask */
	  ulTaskNotifyTake(0, portMAX_DELAY);
	  //	printf("Start 'Input' task \r\n");
	  uint8_t pinStates[NUMPIN] = {0};
	  uint32_t pinTimes[NUMPIN] = {0};
	  uint32_t millis;
	  uint8_t pinLevel[NUMPIN] = {0};
	  TickType_t xLastWake;
	  //    char mqtt_payload[20] = {0};
	  //    char mqtt_topic[20] = {0};
	  osDelay(1000);
	  InitMultibutton();

	  /* Список входных пинов (Button topin == 1 и Switch topin == 3) строится
	   * ОДИН РАЗ при старте, после InitMultibutton(). Раньше каждые 5 мс
	   * перебирались все NUMPIN пинов ради условий topin == 1 / topin == 3.
	   * Массив на NUMPIN байт - точная верхняя граница, лимитов и malloc не
	   * нужно. Новые Button/Switch пины применяются после перезагрузки
	   * (GPIO настраивается только при старте). */
	  uint8_t inp_ids[NUMPIN];
	  uint8_t n_inp = 0;
	  for (uint8_t p = 0; p < NUMPIN; p++) {
	    if (PinsConf[p].topin == 1 || PinsConf[p].topin == 3) {
	      inp_ids[n_inp++] = p;
	    }
	  }

	  /* Положение выключателя - источник истины: при старте оно применяется
	   * к привязанным выходам (замкнут - ON, разомкнут - OFF). Раньше pinLevel
	   * при старте был 0, поэтому применялось только разомкнутое положение
	   * (OFF), а замкнутое игнорировалось. Инвертированное значение заставляет
	   * первый проход вызвать processPins с реальным положением. */
	  /* Power On State: положение выключателя на старте применяется только к
	   * выходам с режимом SWITCH (фильтр в processPins по g_ponr_boot_pass).
	   * Остальные выходы (OFF / ON / LAST) выключатель при старте не трогает,
	   * их начальное состояние уже задано в InitPin. Текущее положение
	   * запоминается в pinLevel, поэтому ложного фронта в цикле не будет. */
	  for (uint8_t n = 0; n < n_inp; n++) {
	    uint8_t i = inp_ids[n];
	    if (PinsConf[i].topin == 3) {
	      pinLevel[i] = (uint8_t)HAL_GPIO_ReadPin(PinsInfo[i].gpio_name,
	                                              PinsInfo[i].hal_pin);
	      if (PinsConf[i].onoff != 0) {
	        uint8_t act = (pinLevel[i] == GPIO_PIN_RESET) ? 1 : 0;
	        g_ponr_boot_pass = 1;
	        processPins((uint16_t)(i + 1), act);
	        g_ponr_boot_pass = 0;
	        mqtt_queue_send_safe(2, i, act, 0);
	      }
	    }
	  }
  /* Infinite loop */
  xLastWake = xTaskGetTickCount();
  for (;;) {
	   millis = HAL_GetTick();
	    for (uint8_t n = 0; n < n_inp; n++) {
	      uint8_t i = inp_ids[n];
	      /* Условия topin и act оставлены как были: читаются на лету, поэтому
	       * пин, переназначенный из веба, сразу перестаёт обрабатываться. */
	      if (PinsConf[i].topin == 1 && PinsConf[i].act == 1) { // BUTTON
	        button_ticks(&button[i]);
	      }
	      /*
	      // INPUT Button GPIO_PULLDOWN
	      if (PinsConf[i].topin == 1 && PinsConf[i].ptype == 2) { // Для 'button'
	              pinStates[i] = HAL_GPIO_ReadPin(PinsInfo[i].gpio_name,
	      PinsInfo[i].hal_pin); if (pinStates[i] == 1 && (millis - pinTimes[i]) >=
	      200) { pinTimes[i] = millis;

	                      // OUTPUT (вынести в отдельную функцию)
	                      for (int a = 0; a < NUMPINLINKS; a++) {
	                              if (PinsLinks[a].idin == i) {
	                                      data_pin.id = PinsLinks[a].idout;
	                                      data_pin.action = 2;
	                                      xQueueSend(outputQueueHandle, (void* )
	      &data_pin, 0);
	                              }
	                      }
	              }
	      }
	      // INPUT Button GPIO_PULLUP
	      if (PinsConf[i].topin == 1 && PinsConf[i].ptype == 1) { // Для 'button'
	              pinStates[i] = HAL_GPIO_ReadPin(PinsInfo[i].gpio_name,
	      PinsInfo[i].hal_pin); if (pinStates[i] == 0 && (millis - pinTimes[i]) >=
	      200) { pinTimes[i] = millis;

	                      // OUTPUT (вынести в отдельную функцию)
	                      for (int a = 0; a < NUMPINLINKS; a++) {
	                              if (PinsLinks[a].idin == i) {
	                                      data_pin.id = PinsLinks[a].idout;
	                                      data_pin.action = 2;
	                                      xQueueSend(outputQueueHandle, (void* )
	      &data_pin, 0);
	                              }
	                      }
	              }
	      }

	      */
	      // INPUT Switch
	      if (PinsConf[i].topin == 3) {
	        pinStates[i] =
	            HAL_GPIO_ReadPin(PinsInfo[i].gpio_name, PinsInfo[i].hal_pin);
	        if (pinStates[i] != GPIO_PIN_RESET && pinStates[i] != GPIO_PIN_SET) {
	          printf("Error reading GPIO pin %d\r\n", PinIdFromIdx(i));
	          continue;
	        }
	        /* Master Enable: если onoff == 0, игнорируем физический выключатель.
	           Обновляем pinLevel/pinTimes, чтобы при включении onoff не произошёл
	           ложный фронт. */
	        if (PinsConf[i].onoff == 0) {
	          if (pinLevel[i] != pinStates[i]) {
	            pinLevel[i] = pinStates[i];
	            pinTimes[i] = millis;
	          }
	          continue;
	        }
	        // Инвертируем логику для pull-up выключателей
	        // Когда выключатель замкнут (нажат) - на входе 0
	        if (pinStates[i] == 0 && (millis - pinTimes[i]) >= 200 &&
	            pinLevel[i] != pinStates[i]) {
	          pinLevel[i] = pinStates[i];
	          pinTimes[i] = millis;
	          processPins((uint16_t)(i + 1), 1); // Отправляем 1, т.к. выключатель включен
	          mqtt_queue_send_safe(2, i, 1, 0);
	        }
	        // Когда выключатель разомкнут (отжат) - на входе 1
	        if (pinStates[i] == 1 && (millis - pinTimes[i]) >= 200 &&
	            pinLevel[i] != pinStates[i]) {
	          pinLevel[i] = pinStates[i];
	          pinTimes[i] = millis;
	          processPins((uint16_t)(i + 1), 0); // Отправляем 0, т.к. выключатель выключен
	          mqtt_queue_send_safe(2, i, 0, 0);
	        }
	      }
	    }

	    /* Process Zigbee virtual buttons (RAW mode state machine) */
	    zbee_vbtn_tick();

	    /* Power On State: отслеживание последнего состояния и применение режима
	     * для Zigbee после подключения к MQTT (внутри троттлинг до 1 раза в секунду) */
	    ponr_poll();

	    vTaskDelayUntil(&xLastWake, pdMS_TO_TICKS(5));
  }
  /* USER CODE END StartInputTask */
}

/* USER CODE BEGIN Header_StartEncoderTask */
/**
 * @brief Function implementing the EncoderTask thread.
 * @param argument: Not used
 * @retval None
 */
#define ENC_TRANS_PER_DETENT  4      // переходов A/B на один щелчок; если один щелчок даёт полшага — поставь 2
#define ENC_SLOW_STEP         1
#define ENC_FAST_STEP         5      // 5 (рекомендуется) или 10
#define ENC_FAST_MS           40     // щелчки чаще, чем раз в 40 мс — считаем вращение быстрым
#define ENC_PARTIAL_RESET_MS  150    // сброс неполного щелчка
#define ENC_DIRTY_PERIOD_MS   100    // mark_slice_dirty не чаще, чем раз в 100 мс

typedef struct {
  GPIO_TypeDef *gA, *gB;
  uint16_t      pA, pB;
  uint8_t       id;
  uint8_t       state;       /* (A<<1)|B */
  int8_t        cnt;         /* накопитель переходов */
  int8_t        last_dir;
  uint32_t      t_edge;      /* время последнего перехода */
  uint32_t      t_detent;    /* время последнего щелчка   */
} enc_ctx_t;

/* Применить delta (с учётом знака) ко всем PWM, связанным с энкодером.
 * Возвращает true, если хоть одно значение реально изменилось. */
static bool enc_apply(uint8_t id, int delta)
{
  bool changed = false;

  for (int a = 0; a < NUMPINLINKS; a++) {
    if (PinsLinks[a].idin != (short)(id + 1)) continue;
    if (!cond_eval_ref(PinsLinks[a].cond)) continue;

    int out_id = PinsLinks[a].idout;
    if (out_id < 1 || out_id > NUMPIN) continue;      /* Zigbee/мусор */
    int idpwm = out_id - 1;
    if (PinsConf[idpwm].topin != 5) continue;
    if (is_pin_in_autotune(idpwm)) continue;         /* AutoTune lock */

    int old = PinsConf[idpwm].dvalue;
    int val = old + delta;
    if (val < 0)   val = 0;
    if (val > 100) val = 100;
    if (val == old) continue;                        /* упёрлись в край */

    PinsConf[idpwm].dvalue = val;
    changed = true;

    /* В железо — только если энкодер включён (иначе это пресет) */
    if (PinsConf[id].onoff != 0) {
      uint32_t pulse = (uint32_t)((uint64_t)val * PinsConf[idpwm].pwmmax / 100ULL);
      __HAL_TIM_SET_COMPARE(&htim[idpwm], PinsInfo[idpwm].tim_channel, pulse);
    }
  }
  return changed;
}
/* USER CODE END Header_StartEncoderTask */
void StartEncoderTask(void *argument)
{
  /* USER CODE BEGIN StartEncoderTask */
  ulTaskNotifyTake(0, portMAX_DELAY);

  /* Таблица [prev<<2 | curr] -> -1/0/+1 */
  static const int8_t enc_tab[16] = {
     0, -1,  1,  0,
     1,  0,  0, -1,
    -1,  0,  0,  1,
     0,  1, -1,  0
  };

  /* ── Проход 1: считаем энкодеры ── */
  uint8_t n_enc = 0;
  for (uint8_t id = 0; id < NUMPIN; id++) {
    if (PinsConf[id].topin != 8) continue;
    uint8_t b = PinsConf[id].encoderb;
    if (b < 1 || b > NUMPIN) continue;
    n_enc++;
  }

  /* Нет энкодеров — задача больше не нужна */
  if (n_enc == 0) {
    for (;;) osDelay(portMAX_DELAY);
  }

  enc_ctx_t *list = (enc_ctx_t *)pvPortMalloc(n_enc * sizeof(enc_ctx_t));
  if (list == NULL) {
    printf("EncoderTask: no memory for %u encoders\r\n", (unsigned)n_enc);
    for (;;) osDelay(portMAX_DELAY);
  }

  /* ── Проход 2: заполняем, берём реальное состояние пинов ── */
  uint8_t k = 0;
  for (uint8_t id = 0; id < NUMPIN && k < n_enc; id++) {
    if (PinsConf[id].topin != 8) continue;
    uint8_t b = PinsConf[id].encoderb;
    if (b < 1 || b > NUMPIN) continue;

    enc_ctx_t *c = &list[k++];
    memset(c, 0, sizeof(*c));
    c->id = id;
    c->gA = PinsInfo[id].gpio_name; c->pA = PinsInfo[id].hal_pin;
    c->gB = PinsInfo[b - 1].gpio_name;  c->pB = PinsInfo[b - 1].hal_pin;
    c->state = ((HAL_GPIO_ReadPin(c->gA, c->pA) ? 1 : 0) << 1)
             |  (HAL_GPIO_ReadPin(c->gB, c->pB) ? 1 : 0);
  }

  TickType_t xLast     = xTaskGetTickCount();
  uint32_t   t_dirty   = xLast;
  bool       dirty_req = false;

  /* Infinite loop */
  for (;;) {
	    uint32_t now = xTaskGetTickCount();

	    for (uint8_t i = 0; i < n_enc; i++) {
	      enc_ctx_t *e = &list[i];

	      uint8_t cur = ((HAL_GPIO_ReadPin(e->gA, e->pA) ? 1 : 0) << 1)
	                  |  (HAL_GPIO_ReadPin(e->gB, e->pB) ? 1 : 0);

	      if (cur != e->state) {
	        int8_t mv = enc_tab[(e->state << 2) | cur];
	        e->state  = cur;
	        e->t_edge = now;

	        if (mv != 0) {
	          e->cnt += mv;

	          if (e->cnt >= ENC_TRANS_PER_DETENT || e->cnt <= -ENC_TRANS_PER_DETENT) {
	            int8_t dir = (e->cnt > 0) ? 1 : -1;
	            e->cnt = 0;

	            /* Быстро = щелчки идут часто И в одну сторону */
	            uint32_t dt = now - e->t_detent;
	            int step = (dir == e->last_dir && dt < ENC_FAST_MS)
	                         ? ENC_FAST_STEP : ENC_SLOW_STEP;
	            e->t_detent = now;
	            e->last_dir = dir;

	            if (enc_apply(e->id, dir * step)) dirty_req = true;
	          }
	        }
	      } else if (e->cnt != 0 && (now - e->t_edge) > ENC_PARTIAL_RESET_MS) {
	        e->cnt = 0;                 /* недокрученный щелчок — забываем */
	      }
	    }

	    /* Инвалидация ETag веб-слайсов — не чаще раза в 100 мс */
	    if (dirty_req && (now - t_dirty) >= ENC_DIRTY_PERIOD_MS) {
	      mark_slice_dirty(&g_ver_encoder);
	      mark_slice_dirty(&g_ver_pins);
	      t_dirty   = now;
	      dirty_req = false;
	    }

	    vTaskDelayUntil(&xLast, pdMS_TO_TICKS(1));
  }
  /* USER CODE END StartEncoderTask */
}

void StartDs18b20Task(void *argument)
{
  /* USER CODE BEGIN StartDs18b20Task */
  ulTaskNotifyTake(0, portMAX_DELAY);
  uint8_t dscount = 0;

  printf("\r\n[DEBUG] Searching for DS18B20 sensors...\r\n");
  /* Остатки старых конфигураций: слот датчика, чей пин больше не OneWire
   * (topin != 4), освобождаем. */
  for (uint8_t j = 0; j < MAX_DS18B20_P; j++) {
    if (ds18b20[j].typsensr != 1) continue;
    uint8_t sid = ds18b20[j].id;
    if (sid < 1 || sid > NUMPIN || PinsConf[sid - 1].topin != 4) {
      memset(&ds18b20[j], 0, sizeof(ds18b20[j]));
    }
  }

  /* ВАЖНО: ow_conf индексируется ТЕМ ЖЕ индексом j, что и ds18b20[j].
   * Раньше при инициализации использовался отдельный счётчик owpinnum,
   * а в основном цикле - j, из-за чего индексы могли разъехаться. */
  for (uint8_t i = 0; i < NUMPIN; i++) {
    if (PinsConf[i].topin != 4) continue;           /* не OneWire */
    for (uint8_t j = 0; j < MAX_DS18B20_P; j++) {
      if (ds18b20[j].id != (uint8_t)(i + 1) || ds18b20[j].typsensr != 1) continue;

      ow_conf[j].OneWirePort = PinsInfo[i].gpio_name;
      ow_conf[j].OneWirePin  = PinsInfo[i].hal_pin;
      snprintf(ds18b20[j].pin, sizeof(ds18b20[j].pin), "%.*s",
               (int)sizeof(ds18b20[j].pin) - 1, PinsInfo[i].pins);

      init_ds18b20(&ow_conf[j].OneWire,
                   ow_conf[j].OneWirePort,
                   ow_conf[j].OneWirePin, &ow_conf[j].owflag,
                   &ow_conf[j].temp_cnt, ds18b20[j].id, j);

      if (ow_conf[j].owflag && ow_conf[j].temp_cnt > 0) {
        ds18b20[j].onoff = 1;
        ds18b20[j].numsens = ow_conf[j].temp_cnt;
        ds18b20[j].error_cnt = 0;
        ds18b20[j].auto_disabled = 0;
        for (uint8_t k = 0; k < ds18b20[j].numsens; k++) {
          ds18b20[j].sensors[k].valid = true;
        }
        dscount++;
      } else {
        /* Датчики не найдены на старте: помечаем шину для периодической
         * переинициализации (раньше повторных попыток не было вообще). */
        ds18b20[j].auto_disabled = 1;
      }
      break;
    }
  }

  if (dscount != 0) {
    printf("[DEBUG] Found DS18B20 pins: %d\r\n", dscount);
  } else {
    printf("[DEBUG] No DS18B20 pins found! Will retry every %d sec.\r\n",
           DS18B20_REINIT_INTERVAL_MS / 1000);
  }
  uint32_t reinit_tick = HAL_GetTick();

  /* Infinite loop */
  for (;;) {
    /* Опрос рабочих шин */
    for (uint8_t i = 0; i < MAX_DS18B20_P; i++) {
      if (ds18b20[i].typsensr == 1 && ds18b20[i].onoff && ow_conf[i].owflag) {
        process_ds18b20(&ow_conf[i].OneWire, ow_conf[i].owflag, i);
      }
    }

    /* Авто-переинициализация отключённых/не найденных шин.
     * Теперь работает и когда на старте не найдено НИ ОДНОЙ шины. */
    if ((HAL_GetTick() - reinit_tick) >= DS18B20_REINIT_INTERVAL_MS) {
      reinit_tick = HAL_GetTick();
      for (uint8_t i = 0; i < MAX_DS18B20_P; i++) {
        if (!(ds18b20[i].auto_disabled && ds18b20[i].typsensr == 1)) continue;
        if (ow_conf[i].OneWirePort == NULL) continue;   /* слот не инициализировался */

        printf("[INFO] Attempting reinit of DS18B20 bus idx %d (pin %s)...\r\n",
               i, ds18b20[i].pin);
        ds18b20[i].error_cnt = 0;
        ds18b20[i].auto_disabled = 0;
        ow_conf[i].owflag = 0;
        ow_conf[i].temp_cnt = 0;

        init_ds18b20(&ow_conf[i].OneWire,
                     ow_conf[i].OneWirePort,
                     ow_conf[i].OneWirePin, &ow_conf[i].owflag,
                     &ow_conf[i].temp_cnt, ds18b20[i].id, i);

        if (ow_conf[i].owflag && ow_conf[i].temp_cnt > 0) {
          ds18b20[i].onoff = 1;
          ds18b20[i].numsens = ow_conf[i].temp_cnt;
          for (uint8_t k = 0; k < ds18b20[i].numsens; k++) {
            ds18b20[i].sensors[k].valid = true;
            ds18b20[i].sensors[k].errorflg = false;
          }
          mark_slice_dirty(&g_ver_sensors);
          mark_slice_dirty(&g_ver_onewire);
          mark_slice_dirty(&g_ver_pins);
          printf("[INFO] DS18B20 bus idx %d REINIT OK - %d sensors found!\r\n",
                 i, ds18b20[i].numsens);
        } else {
          ds18b20[i].auto_disabled = 1;
          printf("[WARN] DS18B20 bus idx %d reinit FAILED - will retry in %d sec.\r\n",
                 i, DS18B20_REINIT_INTERVAL_MS / 1000);
        }
      }
    }
    mark_slice_dirty(&g_ver_sensors);
    osDelay(2000);
  }
  /* USER CODE END StartDs18b20Task */
}

void StartDht22Task(void *argument)
{
  /* USER CODE BEGIN StartDht22Task */
  ulTaskNotifyTake(0, portMAX_DELAY);
  uint8_t dhtcount = 0;
  uint8_t owpinnum = 0;

  printf("\r\n[DEBUG] Searching for DHT22 sensors...\r\n");
  // Initialize configuration array
  for (uint8_t i = 0; i < NUMPIN; i++) {
    if (PinsConf[i].topin == 4) {
      for (uint8_t j = 0; j < MAX_DHT22_P; j++) {
//        printf("+++ i = %d j = %d \r\n", i, j);
        if (dht22[j].id == (uint8_t)(i + 1) && dht22[j].typsensr == 2) {
          DHT22_Init(j, (uint8_t)(i + 1));
          dht22[j].valid = true;
          dht22[j].onoff = 1;
          dhtcount++;
          owpinnum++;
        }
      }
    }
  }

  if (dhtcount != 0) {
    printf("[DEBUG] Found DHT22 sensors: %d\r\n", dhtcount);
  } else {
    printf("[DEBUG] No DHT22 sensors found!\r\n");
  }
  /* Infinite loop */
  for (;;) {
    if (dhtcount != 0) {
      for (uint8_t i = 0; i < MAX_DHT22_P; i++) {
        if (dht22[i].onoff) {
          process_dht22(i);
        }
      }
      check_DHT22_limits();
    }
    mark_slice_dirty(&g_ver_sensors);
    osDelay(2000);
  }
  /* USER CODE END StartDht22Task */
}

/* USER CODE BEGIN Header_StartServiceTask */
/**
 * @brief Function implementing the ServiceTask thread.
 * @param argument: Not used
 * @retval None
 */
/* ── Вспомогательные функции для sunrise/sunset ──
 * Вынесены из StartServiceTask — GCC nested functions используют трамплины
 * на стеке, что вызывает HardFault на Cortex-M7 (XN-protected SRAM). */
static double svc_degToRad(double degree) { return (degree * PI / 180.0); }
static double svc_radToDeg(double radian) { return (radian * 180.0 / PI); }

static int svc_dayOfYear(int yr, uint8_t mon, uint8_t d) {
  int N1 = floor(275 * mon / 9);
  int N2 = floor((mon + 9) / 12);
  int N3 = (1 + floor((yr - 4 * floor(yr / 4) + 2) / 3));
  return N1 - (N2 * N3) + d - 30;
}

static double svc_calculateSunriseOrSunset(int isSunrise) {
  int N = svc_dayOfYear(year, month, day);
  // Convert the SetSettings.lon_de to hour value and calculate an approximate
  // time
  double lngHour = SetSettings.lon_de / 15.0;
  double t = N + ((isSunrise ? 6 : 18) - lngHour) / 24;
  // Calculate the Sun's mean anomaly
  double M = (0.9856 * t) - 3.289;
  // Calculate the Sun's true longitude
  double L = fmod(M + (1.916 * sin(svc_degToRad(M))) +
                      (0.020 * sin(2 * svc_degToRad(M))) + 282.634,
                  360.0);
  // Calculate the Sun's right ascension
  double RA = fmod(svc_radToDeg(atan(0.91764 * tan(svc_degToRad(L)))), 360.0);
  // Right ascension value needs to be in the same quadrant as L
  double Lquadrant = floor(L / 90) * 90;
  double RAquadrant = floor(RA / 90) * 90;
  RA = RA + (Lquadrant - RAquadrant);
  // Right ascension value needs to be converted into hours
  RA = RA / 15;
  // Calculate the Sun's declination
  double sinDec = 0.39782 * sin(svc_degToRad(L));
  double cosDec = cos(asin(sinDec));
  // Calculate the Sun's local hour angle
  double cosH =
      (sin(svc_degToRad(ZENITH)) - (sinDec * sin(svc_degToRad(SetSettings.lat_de)))) /
      (cosDec * cos(svc_degToRad(SetSettings.lat_de)));
  if (cosH > 1 || cosH < -1) {
    return -1; // The sun never rises/sets on this location on the specified
               // date
  }
  // Finish calculating H and convert into hours
  double H = isSunrise ? 360 - svc_radToDeg(acos(cosH)) : svc_radToDeg(acos(cosH));
  H = H / 15;
  // Calculate local mean time of rising/setting
  double T = H + RA - (0.06571 * t) - 6.622;
  // Adjust back to UTC
  double UT = fmod(T - lngHour + 24.0, 24.0);
  // Convert UT value to local time zone of
  // SetSettings.lat_de/SetSettings.lon_de
  double localT = fmod(UT + SetSettings.timezone + 24.0, 24.0);
  return localT;
}

static void svc_printResults(void) {
  double sunrise = svc_calculateSunriseOrSunset(1);
  double sunset = svc_calculateSunriseOrSunset(0);
  if (sunrise == -1 || sunset == -1) {
    printf("The sun doesn't rise or set on this day at this location.\n");
  } else {
    int sunriseHour = (int)sunrise;
    int sunriseMinute = (int)((sunrise - sunriseHour) * 60);
    int sunsetHour = (int)sunset;
    int sunsetMinute = (int)((sunset - sunsetHour) * 60);
    // Сохранение времени восхода солнца
    snprintf(SetSettings.sunrise,
             sizeof(SetSettings.sunrise),
             "%02d:%02d",
             sunriseHour,
             sunriseMinute);
    // Сохранение времени заката солнца
    snprintf(SetSettings.sunset,
             sizeof(SetSettings.sunset),
             "%02d:%02d",
             sunsetHour,
             sunsetMinute);
    // Calculate day length
    double dayLength = sunset - sunrise;
    if (dayLength < 0)
      dayLength += 24;
    int dayLengthHours = (int)dayLength;
    int dayLengthMinutes = (int)((dayLength - dayLengthHours) * 60);
    // Сохранение длины светового дня
    snprintf(SetSettings.dlength,
             sizeof(SetSettings.dlength),
             "%02d:%02d",
             dayLengthHours,
             dayLengthMinutes);
  }
  mark_slice_dirty(&g_ver_settings);   /* пересчитаны полнолуние, восход/закат */
}

/* ── Определение изменений для ETag-слайсов и карта cron для PWM fade ──
 * Используются в StartServiceTask. Вынесены сюда (на уровень файла),
 * потому что вложенные функции GCC дают HardFault на Cortex-M7. */

/* Хэш FNV-1a: дешёвая «подпись» данных, чтобы понять, изменились ли они. */
static uint32_t svc_fnv(uint32_t h, const void *p, size_t n)
{
  const uint8_t *b = (const uint8_t *)p;
  while (n--) {
    h ^= *b++;
    h *= 16777619u;
  }
  return h;
}

#define SVC_FNV_INIT 2166136261u
#define SVC_MIX(h, v) \
  do { uint32_t _v = (uint32_t)(v); (h) = svc_fnv((h), &_v, sizeof(_v)); } while (0)

/* Раз в секунду вызывается из StartServiceTask. Помечает ETag-слайс только
 * если изменились данные, которые он отдаёт в веб. g_ver_common здесь НЕ
 * участвует: он несёт uptime, heap и время и должен помечаться каждую секунду.
 *
 * ВАЖНО: если в JSON-обработчики (handle_sensors, handle_onewire, handle_pid,
 * handle_encoders, handle_get_pins) добавится новое числовое поле, которое
 * может меняться само, не через веб, его нужно добавить в подпись ниже. */
static void svc_mark_changed_slices(void)
{
  /* Нули при старте: первый вызов пометит все слайсы один раз. */
  static uint32_t s_sens = 0, s_topo = 0, s_pins = 0, s_pid = 0;

  /* Датчики (/api/state/sensors и /api/state/onewire): целиком массивы
   * ds18b20 и dht22 (около 7 КБ), чтобы не перечислять поля. */
  uint32_t h_sens = SVC_FNV_INIT;
  h_sens = svc_fnv(h_sens, ds18b20, sizeof(ds18b20));
  h_sens = svc_fnv(h_sens, dht22, MAX_DHT22_P * sizeof(dht22_pin_t));

  /* Пины (/api/pins и /api/state/encoder): только числовые поля, которые
   * показывает веб. Строки (info, sclick, ...) меняются только через веб,
   * а веб-обработчики сами помечают слайсы. */
  uint32_t h_topo = SVC_FNV_INIT;   /* тип пина: нужен слайсу onewire */
  uint32_t h_pins = SVC_FNV_INIT;
  for (int i = 0; i < NUMPIN; i++) {
    SVC_MIX(h_topo, PinsConf[i].topin);
    SVC_MIX(h_pins, PinsConf[i].topin);
    SVC_MIX(h_pins, PinsConf[i].dvalue);
    SVC_MIX(h_pins, PinsConf[i].onoff);
    SVC_MIX(h_pins, PinsConf[i].pwm);
    SVC_MIX(h_pins, PinsConf[i].pwmmax);
    SVC_MIX(h_pins, PinsConf[i].pwm_flags);
    SVC_MIX(h_pins, PinsConf[i].ponr);
    SVC_MIX(h_pins, PinsConf[i].ptype);
    SVC_MIX(h_pins, PinsConf[i].encoderb);
    SVC_MIX(h_pins, PinsConf[i].zbee_bind_id);
  }

  /* PID (/api/pid): поля, которые показывает веб (рабочие переменные
   * регулятора вроде integral и last_tick в подпись не входят). */
  uint32_t h_pid = SVC_FNV_INIT;
  for (int p = 0; p < PID_MAX_SLOTS; p++) {
    SVC_MIX(h_pid, PidConf[p].onoff);
    SVC_MIX(h_pid, PidConf[p].preset);
    SVC_MIX(h_pid, PidConf[p].pwm_pin_id);
    SVC_MIX(h_pid, PidConf[p].selsens);
    SVC_MIX(h_pid, PidConf[p].cond);
    SVC_MIX(h_pid, PidConf[p].tune_state);
    SVC_MIX(h_pid, PidConf[p].tune_progress);
    h_pid = svc_fnv(h_pid, &PidConf[p].tmpcur, sizeof(PidConf[p].tmpcur));
    h_pid = svc_fnv(h_pid, &PidConf[p].tmpset, sizeof(PidConf[p].tmpset));
    h_pid = svc_fnv(h_pid, PidConf[p].sernum, sizeof(PidConf[p].sernum));
    h_pid = svc_fnv(h_pid, PidConf[p].info, sizeof(PidConf[p].info));
  }

  bool d_sens = (h_sens != s_sens);
  bool d_topo = (h_topo != s_topo);
  bool d_pins = (h_pins != s_pins);
  /* /api/pid показывает ещё и dvalue PWM-пина, поэтому слайс pid
   * помечается и при изменении пинов. */
  bool d_pid  = (h_pid != s_pid) || d_pins;
  s_sens = h_sens; s_topo = h_topo; s_pins = h_pins; s_pid = h_pid;

  if (d_sens)             mark_slice_dirty(&g_ver_sensors);
  if (d_sens || d_topo)   mark_slice_dirty(&g_ver_onewire);
  if (d_pins) {
    mark_slice_dirty(&g_ver_encoder);
    mark_slice_dirty(&g_ver_pins);
  }
  if (d_pid)              mark_slice_dirty(&g_ver_pid);
}

/* Карта «какие cron-таймеры управляют PWM-пином»: бит t = таймер t,
 * бит 63 = карта посчитана. Одной строки "pwm:N," достаточно, чтобы таймер
 * считался управляющим этим пином (как и раньше). */
#define SVC_MASK_VALID (1ULL << 63)
STATIC_ASSERT(NUMTASK <= 63, svc_cron_mask_numtask_must_be_le_63);

static uint64_t svc_build_cron_mask(int logical_pwm_id)
{
  /* logical_pwm_id — ID 1..NUMPIN, а не индекс массива. */
  char needle[12];
  snprintf(needle, sizeof(needle), "pwm:%d,", logical_pwm_id);

  uint64_t m = SVC_MASK_VALID;
  for (int t = 0; t < NUMTASK; t++) {
    char tmp[sizeof(dbCrontxt[0].activ)];
    taskENTER_CRITICAL();
    strncpy(tmp, dbCrontxt[t].activ, sizeof(tmp) - 1);
    tmp[sizeof(tmp) - 1] = '\0';
    taskEXIT_CRITICAL();
    if (strstr(tmp, needle) != NULL) {
      m |= (1ULL << t);
    }
  }
  return m;
}

/* USER CODE END Header_StartServiceTask */
void StartServiceTask(void *argument)
{
  /* USER CODE BEGIN StartServiceTask */
	  ulTaskNotifyTake(0, portMAX_DELAY);
	  //	static uint8_t moonflag = 0; // Счетчик
	  static uint8_t prevday = 0;    // Для отслеживания смены дня
	  static uint8_t prevmin = 0xFF; // Для отслеживания смены минуты
	  //	DateTime nextfullmoon; // Declare nextFullMoon outside the loop
	  DateTime nextfullmnlcl; // Local time version of nextFullMoon
	  /* ── PWM Fade тик-счётчик ── */
	  static uint32_t fade_tick = 0;
	  /* Карта «какие cron-таймеры управляют этим PWM» (см. svc_build_cron_mask).
	   * Считается один раз при старте fade, а не каждую секунду. */
static uint64_t svc_cron_mask[NUMPIN];
 	  static uint32_t svc_cron_gen = 0;   /* поколение cron-текста, для которого посчитаны карты */
    /* Infinite loop */

  /* Infinite loop */
  for (;;) {
	  /* ═══════════════════════════════════════════════
	   *  БЛОК PWM Fade — каждые 1000 мс (НОВОЕ)
	   * ═══════════════════════════════════════════════ */
if (HAL_GetTick() - fade_tick >= 1000) {
  	      fade_tick = HAL_GetTick();
  	      /* Текст cron-действий изменили (Save, удаление пина): карты устарели */
  	      if (svc_cron_gen != g_cron_gen) {
  	        svc_cron_gen = g_cron_gen;
  	        memset(svc_cron_mask, 0, sizeof(svc_cron_mask));
  	      }
            /* common несёт uptime, heap и время - меняется каждую секунду.
	             * Остальные слайсы помечаются в конце блока, только если данные
	             * реально изменились (svc_mark_changed_slices). */
	            mark_slice_dirty(&g_ver_common);
	  	      for (int i = 0; i < NUMPIN; i++) {
	  	        if (!fade_state[i].active) {
	  	            svc_cron_mask[i] = 0;   /* следующий fade посчитает карту заново */
	  	            continue;
	  	        }
	  	        if (PinsConf[i].topin != 5)  continue;
	  	        if (is_pin_in_autotune(i))   continue; /* AutoTune lock */

	  	        /* Рубильник: Encoder onoff (приоритетный) либо On/Off самой PWM-строки */
	  	        bool enc_on = pwm_gate_open((uint8_t)i);
	  	        if (!enc_on) {
	  	            // Гасим PWM и блокируем — БЕЗОПАСНОСТЬ
	  	            __HAL_TIM_SET_COMPARE(&htim[i], PinsInfo[i].tim_channel, 0);
	  	            fade_state[i].active = false;
	  	            continue;
	  	        }

	  	        /* ── Timer onoff — останавливаем fade, PWM не трогаем ── */
	  	        /* Карта считается один раз при старте fade (а не раз в секунду) */
	  	        if (!(svc_cron_mask[i] & SVC_MASK_VALID)) {
	  	            svc_cron_mask[i] = svc_build_cron_mask(PinIdFromIdx(i));
	  	        }

	  	        bool timer_on = false;
	  	        for (int t = 0; t < NUMTASK; t++) {
	  	            if (!(svc_cron_mask[i] & (1ULL << t))) continue;
	  	            if (dbCrontxt[t].onoff == 1) {   /* onoff читается на лету */
	  	                timer_on = true;
	  	                break;
	  	            }
	  	        }
	  	        if (!timer_on) {
	  	            /* Таймер выключен — останавливаем fade на текущем значении */
	  	            fade_state[i].active = false;
	  	            printf("PWM fade stopped by Timer OFF: id=%d at %d%%\r\n",
	  	                   PinIdFromIdx(i), PinsConf[i].dvalue);
	  	            continue; /* PWM НЕ трогаем — остаётся на текущем значении */
	  	        }
	  	        /* ──────────────────────────────────────────────────────── */

	  	        fade_state[i].steps_left--;
	  	        fade_state[i].current_duty += fade_state[i].delta;

	  	        /* Клампинг 0–100% */
	  	        if (fade_state[i].current_duty < 0.0f)
	  	            fade_state[i].current_duty = 0.0f;
	  	        if (fade_state[i].current_duty > 100.0f)
	  	            fade_state[i].current_duty = 100.0f;

	  	        int d = (int)(fade_state[i].current_duty + 0.5f);

	  	        /* На последнем шаге гарантируем точное финальное значение */
	  	        if (fade_state[i].steps_left == 0) {
	  	          d = fade_state[i].end_duty;
	  	          fade_state[i].active = false;

	  	          /* Бесшовная передача: PID берёт PWM с финального значения fade */
	  	          for (int p = 0; p < PID_MAX_SLOTS; p++) {
	  	            if (PidConf[p].pwm_pin_id == (uint16_t)(i + 1)) {
	  	              PidConf[p].pwm_out = (uint8_t)d;
	  	              pid_set_pwm(p, (uint8_t)d);
	  	              break;
	  	            }
	  	          }
	  	        }

	  	        PinsConf[i].dvalue = d;
	  	        uint32_t pulse = (uint32_t)((uint64_t)d
	  	                          * PinsConf[i].pwmmax / 100ULL);
	  	        __HAL_TIM_SET_COMPARE(&htim[i], PinsInfo[i].tim_channel, pulse);
	              /* MQTT: send_mqtt_timer_batch() отслеживает PWM duty раз в 1с */
	  	      }
	  	      /* После fade (он меняет dvalue): пометить только изменившиеся слайсы */
	  	      svc_mark_changed_slices();
	  	    }
	  /* ═══════════════════════════════════════════════
	   *  End PWM Fade
	   * ═══════════════════════════════════════════════ */

	      if (day != prevday) {
	        prevday = day;
	        // Calculate after system reboot
	        svc_printResults();
	        if (year != 0000) { // Ensure year is set
	          calculateMoonPhase((DateTime){year, month, day, timez_copy.tm_hour,
	                                        timez_copy.tm_min, timez_copy.tm_sec},
	                             &nextfullmnlcl);
	          nextfullmnlcl.hour += SetSettings.timezone; // Adjust for timezone
	          if (nextfullmnlcl.hour >= 24) {
	            nextfullmnlcl.hour -= 24;
	            nextfullmnlcl.day++;
	          }
	          // Store the full moon data in the correct format
	          uint8_t len = snprintf(
	              SetSettings.fullmoon, sizeof(SetSettings.fullmoon),
	              "%02d.%02d.%04d %02d:%02d", nextfullmnlcl.day, nextfullmnlcl.month,
	              nextfullmnlcl.year, nextfullmnlcl.hour, nextfullmnlcl.minute);
	          if (len < 0 || (size_t)len >= sizeof(SetSettings.fullmoon)) {
	            printf("ERROR: len > setsettings.fullmoon! \n");
	          }
}
        mark_slice_dirty(&g_ver_settings);   /* пересчитаны полнолуние, восход/закат */
        if (SetSettings.lat_de != 0.0 && SetSettings.lon_de != 0.0) {
          Check_SunriseSunset_Actions(); // Проверка "Sunrise/Sunset" after system
                                         // reboot
        }
      }
      if (timez_copy.tm_min != prevmin) { // Проверка раз в минуту
	        prevmin = timez_copy.tm_min;
	        if (timez_copy.tm_hour == 0 && timez_copy.tm_min == 1 && year != 0000) {
	          //          if (moonflag < 3) { // Для уверенности 3 раза!
	          if (year != 0000) { // Ensure year is set
	            calculateMoonPhase((DateTime){year, month, day, timez_copy.tm_hour,
	                                          timez_copy.tm_min, timez_copy.tm_sec},
	                               &nextfullmnlcl);
	            nextfullmnlcl.hour += SetSettings.timezone; // Adjust for timezone
	            if (nextfullmnlcl.hour >= 24) {
	              nextfullmnlcl.hour -= 24;
	              nextfullmnlcl.day++;
	            }
	            // Store the full moon data in the correct format
	            uint8_t len =
	                snprintf(SetSettings.fullmoon, sizeof(SetSettings.fullmoon),
	                         "%02d.%02d.%04d %02d:%02d", nextfullmnlcl.day,
	                         nextfullmnlcl.month, nextfullmnlcl.year,
	                         nextfullmnlcl.hour, nextfullmnlcl.minute);
	            if (len < 0 || (size_t)len >= sizeof(SetSettings.fullmoon)) {
	              printf("ERROR: len > setsettings.fullmoon! \n");
	            }
	          }
	        }
if (SetSettings.lat_de != 0.0 && SetSettings.lon_de != 0.0) {
          Check_SunriseSunset_Actions(); // Проверка "Sunrise/Sunset" один раз в
                                         // минуту.
        }
        mark_slice_dirty(&g_ver_settings);   /* пересчитаны полнолуние, восход/закат */
      }
	      // === ПЕРИОДИЧЕСКИЙ ДАМП PWM РЕГИСТРОВ (каждые 10 секунд) ===
	  //    {
	  //      static uint32_t pwm_dbg_tick = 0;
	  //      if (HAL_GetTick() - pwm_dbg_tick >= 10000) {
	  //        pwm_dbg_tick = HAL_GetTick();
	  //        bool found_pwm = false;
	  //        for (int pi = 0; pi < NUMPIN; pi++) {
	  //          if (PinsConf[pi].topin == 5 && PinsInfo[pi].tim != NULL) {
	  //            found_pwm = true;
	  //            printf("\r\n--- PWM [%d] %s (10s tick) ---\r\n", pi,
	  //                   PinsInfo[pi].pins);
	  //            printf("  dvalue=%d  pwmmax=%d  pwm=%d mHz\r\n",
	  //                   PinsConf[pi].dvalue, PinsConf[pi].pwmmax, PinsConf[pi].pwm);
	  //            printf("  CR1=0x%04lX(EN=%lu)  ARR=%lu  PSC=%lu\r\n",
	  //                   (unsigned long)PinsInfo[pi].tim->CR1,
	  //                   (unsigned long)(PinsInfo[pi].tim->CR1 & TIM_CR1_CEN),
	  //                   (unsigned long)PinsInfo[pi].tim->ARR,
	  //                   (unsigned long)PinsInfo[pi].tim->PSC);
	  //            uint32_t ccr = 0;
	  //            if (PinsInfo[pi].tim_channel == TIM_CHANNEL_1)
	  //              ccr = PinsInfo[pi].tim->CCR1;
	  //            else if (PinsInfo[pi].tim_channel == TIM_CHANNEL_2)
	  //              ccr = PinsInfo[pi].tim->CCR2;
	  //            else if (PinsInfo[pi].tim_channel == TIM_CHANNEL_3)
	  //              ccr = PinsInfo[pi].tim->CCR3;
	  //            else if (PinsInfo[pi].tim_channel == TIM_CHANNEL_4)
	  //              ccr = PinsInfo[pi].tim->CCR4;
	  //            printf("  CCR(ch%lu)=%lu\r\n",
	  //                   (unsigned long)PinsInfo[pi].tim_channel, (unsigned long)ccr);
	  //            if (PinsInfo[pi].tim == TIM1 || PinsInfo[pi].tim == TIM8)
	  //              printf("  BDTR=0x%08lX  MOE=%lu  <<< MUST be 1!\r\n",
	  //                     (unsigned long)PinsInfo[pi].tim->BDTR,
	  //                     (unsigned long)((PinsInfo[pi].tim->BDTR >> 15) & 1));
	  //          }
	  //        }
	  //        if (!found_pwm){
	  //          printf("[PWM] No PWM pins configured (topin==5)!\r\n");}
	  //      }
	  //    }
	      osDelay(500);
  }
  /* USER CODE END StartServiceTask */
}

/* USER CODE BEGIN Header_StartSIM800LTask */
/**
 * @brief Function implementing the SIM800LTask thread.
 * @param argument: Not used
 * @retval None
 */
#define SIM800L_POLL_MS  10   /* период опроса UART модема и SMS-тревог, мс */
/* USER CODE END Header_StartSIM800LTask */
void StartSIM800LTask(void *argument)
{
  /* USER CODE BEGIN StartSIM800LTask */
	  ulTaskNotifyTake(0, portMAX_DELAY);
	  init_sim800l_module();
	  xTaskNotify(
	      ConfigTaskHandle, 0,
	      eNoAction); // Уведомляем ConfigTask о завершении инициализации GSM Task!
	                  //	printf("Hi world! It's from GPS task! \r\n");
	  /* Infinite loop */
  for (;;) {
	    if (gsm_available()) { // если модуль что-то прислал
	      process_sim800l_data();
	    }
	    sms_alarm_poll(); // SMS-тревоги от датчиков Security (Send SMS = YES)
	    /* Опрос раз в SIM800L_POLL_MS (10 мс) вместо 1 мс. Модем на 57600 бод даёт
	     * не более 6 байт/мс, значит, между опросами накапливается не более 58 байт
	     * при буфере 512 байт. process_sim800l_data() всё равно сам ждёт 50 мс,
	     * чтобы собрать сообщение целиком. */
	    osDelay(SIM800L_POLL_MS);
  }
  /* USER CODE END StartSIM800LTask */
}

/* USER CODE BEGIN Header_StartSecurityTask */
/**
 * @brief Function implementing the SecurityTask thread.
 * @param argument: Not used
 * @retval None
 */
#define SEC_POLL_MS  5   /* период опроса Security-пинов, мс (антидребезг 45 мс) */
/* USER CODE END Header_StartSecurityTask */
void StartSecurityTask(void *argument)
{
  /* USER CODE BEGIN StartSecurityTask */
  ulTaskNotifyTake(0, portMAX_DELAY);
  /* Infinite loop */
  for (;;) {
	    uint32_t currtime = HAL_GetTick();

	    for (int i = 0; i < NUMPIN; i++) {
	      if (PinsConf[i].topin != 10)
	        continue;

	      uint8_t current_state =
	          HAL_GPIO_ReadPin(PinsInfo[i].gpio_name, PinsInfo[i].hal_pin);

	      if (current_state != PinsConf[i].prvstate) {
	        if ((currtime - sec_deb_tm[i]) >= DEBOUNCE_DELAY) {
	          bool trigger_event = false;

	          switch (PinsConf[i].ptype) {
	          case 0: /* PIR: датчик движения.
	                   * Подключение: выход PIR -> пин.
	                   * Покой: 0, движение: 1.
	                   * Срабатывание: появление движения (0 -> 1). */
	            trigger_event = (PinsConf[i].prvstate == 0 && current_state == 1);
	            break;

	          case 1: /* Normal open: нормально открытый геркон.
	                   * Подключение: 3.3V -> геркон -> пин.
	                   * Магнит рядом: контакты замкнуты, на пине 1.
	                   * Магнита нет: контакты разомкнуты, на пине 0.
	                   * Срабатывание: размыкание контактов (1 -> 0). */
	            trigger_event = (PinsConf[i].prvstate == 1 && current_state == 0);
	            break;

	          case 2: /* Normal close: нормально закрытый геркон.
	                   * Подключение: 3.3V -> геркон -> пин.
	                   * Магнит рядом: контакты разомкнуты, на пине 0.
	                   * Магнита нет: контакты замкнуты, на пине 1.
	                   * Срабатывание: замыкание контактов (0 -> 1). */
	            trigger_event = (PinsConf[i].prvstate == 0 && current_state == 1);
	            break;
	          }

	          if (trigger_event) { // Если обнаружено срабатывание
	            if ((currtime - sec_lasttrg[i]) >= 1000) {
	              if (PinsConf[i].onoff && PinsConf[i].sclick[0] != '\0' &&
	                  strcmp(PinsConf[i].sclick, "None") != 0) {
	                action_handler((uint16_t)(i + 1), PinsConf[i].sclick, "Security action");

	                mqtt_queue_send_safe(6, i, current_state, 0);
	              }
	              /* Send SMS не зависит от поля Action: SMS уходит, даже если
	               * Action = None. Отправляет задача SIM800L (sms_alarm_poll). */
	              if (PinsConf[i].onoff && strcmp(PinsConf[i].send_sms, "YES") == 0) {
	                sms_alarm_request(i + 1);
	              }

	              sec_lasttrg[i] = currtime;
	            }
	          }
	          PinsConf[i].prvstate = current_state;
	          PinsConf[i].state = current_state;
	          sec_deb_tm[i] = currtime;
	        }
	      }
	    }
	    osDelay(1);
  }
  /* USER CODE END StartSecurityTask */
}

void StartPIDTask(void *argument)
{
  /* USER CODE BEGIN StartPIDTask */
  ulTaskNotifyTake(0, portMAX_DELAY);
  printf("\r\n[PID] Task started\r\n");

  /* Инициализация Ts_ms по умолчанию для слотов без пресета */
  for (int i = 0; i < PID_MAX_SLOTS; i++) {
    if (PidConf[i].preset > 0 && PidConf[i].Kp == 0.0f && PidConf[i].Ki == 0.0f) {
        // Force fully applying preset locally if Kp/Ki is zero (legacy config load fix)
        extern void apply_pid_preset_extern(int slot, uint8_t preset_idx);
        apply_pid_preset_extern(i, PidConf[i].preset);
    }
    if (PidConf[i].Ts_ms == 0) PidConf[i].Ts_ms = 1000;
    if (PidConf[i].pwm_max == 0) PidConf[i].pwm_max = 100;
    if (PidConf[i].temp_max < 1.0f) PidConf[i].temp_max = 100.0f;
  }

  /* Infinite loop */
  for(;;)
  {
    for (int i = 0; i < PID_MAX_SLOTS; i++) {
      if (PidConf[i].pwm_pin_id == 0 && PidConf[i].selsens == PID_SENS_NONE) continue;

      /* Если PWM управляется fade (рассвет/закат) — PID не трогает этот пин */
      uint16_t pwm_id = PidConf[i].pwm_pin_id;
      if (pwm_id >= 1 && pwm_id <= NUMPIN && fade_state[pwm_id - 1].active) continue;

      uint32_t now = HAL_GetTick();
      if ((now - PidConf[i].last_tick) < PidConf[i].Ts_ms) continue;
      PidConf[i].last_tick = now;

      /* 1. Чтение температуры (читаем всегда, чтобы обновлять UI) */
      float T = pid_read_temperature(i);
      if (T >= -100.0f) {
          PidConf[i].tmpcur = T;
          PidConf[i].stale_cnt = 0;  /* Сброс — датчик жив */
      } else {
          PidConf[i].stale_cnt++;
      }

      /* 2a. Авто-тюн (если запущен) — работает НЕЗАВИСИМО от onoff */
      if (PidConf[i].tune_state == PID_TUNE_STEP ||
          PidConf[i].tune_state == PID_TUNE_BIAS) {
        pid_autotune_tick(i);
        continue;
      }

      /* Если PID выключен - глушим ШИМ и интегратор, но переходим к следующему слоту */
      if (!PidConf[i].onoff) {
          if (PidConf[i].pwm_out > 0 || PidConf[i].integral != 0.0f) {
              taskENTER_CRITICAL();
              PidConf[i].pwm_out = 0;
              PidConf[i].integral = 0.0f;
              taskEXIT_CRITICAL();
              pid_set_pwm(i, 0);
          }
          continue;
      }

      /* Дополнительное условие работы регулятора (библиотека условий):
       * ложно - глушим ШИМ и интегратор (безопасное обнуление) */
      if (!cond_eval_ref(PidConf[i].cond)) {
          if (PidConf[i].pwm_out > 0 || PidConf[i].integral != 0.0f) {
              taskENTER_CRITICAL();
              PidConf[i].pwm_out = 0;
              PidConf[i].integral = 0.0f;
              taskEXIT_CRITICAL();
              pid_set_pwm(i, 0);
          }
          continue;
      }

      /* ── Аварийное отключение PWM при потере датчика ── */
      /* Если датчик не прочитался 5 циклов подряд — АВАРИЙНО глушим ШИМ */
      #define PID_MAX_STALE_CYCLES  5
      if (PidConf[i].stale_cnt >= PID_MAX_STALE_CYCLES) {
          if (PidConf[i].pwm_out > 0) {
              printf("[PID] SENSOR LOST slot=%d - no valid T for %d cycles! "
                     "EMERGENCY PWM OFF!\r\n", i, PidConf[i].stale_cnt);
              taskENTER_CRITICAL();
              PidConf[i].pwm_out = 0;
              PidConf[i].integral = 0.0f;
              taskEXIT_CRITICAL();
              pid_set_pwm(i, 0);
          }
          continue;
      }

      /* Если датчик не прочитался, а PID включен - пропускаем расчет (чтобы не было бешеных всплесков) */
      if (T < -100.0f) continue;

      /* 2b. Аварийное отключение */
      if (T >= PidConf[i].temp_max) {
        pid_set_pwm(i, 0);
        PidConf[i].pwm_out = 0;
        printf("[PID] EMERGENCY OFF slot=%d T=%.1f >= Tmax=%.1f\r\n",
               i, T, PidConf[i].temp_max);
        continue;
      }

      /* 4. PID-регулятор */
      float error = PidConf[i].tmpset - T;
      float Ts_sec = PidConf[i].Ts_ms / 1000.0f;

      /* P */
      float P_term = PidConf[i].Kp * error;

      /* I (с anti-windup) */
      PidConf[i].integral += PidConf[i].Ki * error * Ts_sec;
      if (PidConf[i].integral > (float)PidConf[i].pwm_max)
        PidConf[i].integral = (float)PidConf[i].pwm_max;
      if (PidConf[i].integral < 0.0f)
        PidConf[i].integral = 0.0f;

      /* D */
      float D_term = 0.0f;
      if (Ts_sec > 0.0f) {
        D_term = PidConf[i].Kd * (error - PidConf[i].prev_error) / Ts_sec;
      }
      PidConf[i].prev_error = error;

      float output = PidConf[i].bias + P_term + PidConf[i].integral + D_term;

      /* Клампинг */
      if (output > (float)PidConf[i].pwm_max) output = (float)PidConf[i].pwm_max;
      if (output < 0.0f) output = 0.0f;

      /* Пауза реверса (холодильник) */
      if (PidConf[i].pause_sec > 0) {
        if (output < 1.0f && PidConf[i].pwm_out > 0) {
          PidConf[i].last_off_tick = now;
        }
        if (output > 0.0f && PidConf[i].pwm_out == 0) {
          if ((now - PidConf[i].last_off_tick) < (uint32_t)PidConf[i].pause_sec * 1000U) {
            output = 0.0f;  /* ещё рано включать */
          }
        }
      }

      PidConf[i].pwm_out = (uint8_t)(output + 0.5f);
//      printf("[PID DEBUG] slot=%d, T=%.1f, tmpset=%.1f, err=%.1f, P=%.1f, I=%.1f, out=%.1f => duty=%d\r\n",
//             i, T, PidConf[i].tmpset, error, P_term, PidConf[i].integral, output, PidConf[i].pwm_out);
      pid_set_pwm(i, PidConf[i].pwm_out);
    }
    osDelay(50);  /* базовый тик 50 мс, реальный Ts контролируется per-slot */
  }
  /* USER CODE END StartPIDTask */
}

/* USER CODE BEGIN Header_StartDgnTask */
/**
* @brief Function implementing the my_DgnTask thread.
* @param argument: Not used
* @retval None
*/
/* Функция диагностики памяти с delta-отслеживанианием */
static void heap_diagnostic(void)
{
    /* Пропускаем отчёт если категория SYSTEM отключена в фильтре логов */
    if (!(g_log_filter_mask & LOG_MASK_SYSTEM)) return;

    static unsigned last_free = 0;
    static unsigned last_min_ever = 0;
    static uint32_t last_malloc_fail = 0;
    static uint32_t last_mqtt_tx_peak = 0;
    static uint32_t last_mqtt_rx_peak = 0;
    static uint32_t last_output_peak = 0;
    static uint32_t last_usb_peak = 0;
    static uint32_t last_zbee_cmd_peak = 0;
    static uint32_t last_mg_conn_peak = 0;
    static uint32_t last_mg_conn_mqttsrv = 0;
    static uint32_t last_mg_poll_gap_peak = 0;
    static uint32_t last_mg_poll_gap_over_50ms_cnt = 0;
    static uint32_t last_req_total = 0;
    static uint32_t last_req_encoder = 0;
    static uint32_t last_req_api = 0;
    static uint32_t last_net_syn_drops = 0;
    static uint32_t last_net_rejects = 0;
    static uint8_t first_run = 1;

    unsigned current_free = (unsigned)xPortGetFreeHeapSize();
    unsigned current_min  = (unsigned)xPortGetMinimumEverFreeHeapSize();
    uint32_t current_malloc_fail = malloc_fail_count;

    HeapStats_t stats;
    vPortGetHeapStats(&stats);

    /* Печатаем только если показатели изменились */
    if (current_free != last_free || current_min != last_min_ever ||
        current_malloc_fail != last_malloc_fail ||
        mqtt_tx_peak != last_mqtt_tx_peak ||
        mqtt_rx_peak != last_mqtt_rx_peak ||
        output_peak != last_output_peak ||
        usb_peak != last_usb_peak ||
        zbee_cmd_peak != last_zbee_cmd_peak ||
        mg_conn_peak != last_mg_conn_peak ||
        mg_conn_mqttsrv != last_mg_conn_mqttsrv ||
        mg_poll_gap_peak != last_mg_poll_gap_peak ||
        mg_poll_gap_over_50ms_cnt != last_mg_poll_gap_over_50ms_cnt ||
        req_total != last_req_total ||
        req_encoder != last_req_encoder ||
        req_api != last_req_api ||
        g_net_syn_drops != last_net_syn_drops ||
        g_net_rejects != last_net_rejects) {

        printf("\r\n=== DIAGNOSTIC REPORT [FW:%s] ===\r\n", FW_VERSION);
        if (first_run) {
            printf("FreeRTOS free now:  %u B\r\n", current_free);
            printf("FreeRTOS min ever:  %u B\r\n", current_min);
            first_run = 0;
        } else {
            printf("FreeRTOS free now:  %u B (delta=%+d)\r\n",
                   current_free, (int)current_free - (int)last_free);
            printf("FreeRTOS min ever:  %u B (delta=%+d)\r\n",
                   current_min, (int)current_min - (int)last_min_ever);
        }

        printf("Heap free blocks:   %lu\r\n", (unsigned long)stats.xNumberOfFreeBlocks);
        printf("Largest free block: %lu B\r\n", (unsigned long)stats.xSizeOfLargestFreeBlockInBytes);
        printf("Smallest free block: %lu B\r\n", (unsigned long)stats.xSizeOfSmallestFreeBlockInBytes);
        if (stats.xAvailableHeapSpaceInBytes > 0) {
            uint32_t frag_pct = 100 - (uint32_t)((uint64_t)stats.xSizeOfLargestFreeBlockInBytes * 100 / stats.xAvailableHeapSpaceInBytes);
            printf("Fragmentation:      %lu%%\r\n", (unsigned long)frag_pct);
        }

        printf("Malloc fail count:  %lu\r\n", current_malloc_fail);

        size_t dtcm_used  = dtcm_alloc_get_used();
        size_t dtcm_total = dtcm_alloc_get_total();
        size_t dtcm_pct   = dtcm_total ? (dtcm_used * 100 / dtcm_total) : 0;

        printf("[SYSTEM] DTCM pool used:     %u B / %u B (%u%%)\r\n",
               (unsigned)dtcm_used, (unsigned)dtcm_total, (unsigned)dtcm_pct);
        printf("[SYSTEM] DTCM pool free:     %u B\r\n",
               (unsigned)dtcm_alloc_get_free());
        printf("[SYSTEM] DTCM alloc fails:   %u\r\n",
               (unsigned)dtcm_alloc_get_fail_count());
        {
            int fl = 0; size_t fs = 0;
            const char *ff = dtcm_alloc_get_last_fail(&fl, &fs);
            extern volatile uint32_t s_sbrk_peak_used, s_sbrk_fail_cnt;
            if (ff) printf("[SYSTEM] DTCM last fail: %s:%d need=%u B\r\n", ff, fl, (unsigned)fs);
            printf("[SYSTEM] newlib heap peak: %lu B, sbrk fails: %lu\r\n",
                   (unsigned long)s_sbrk_peak_used, (unsigned long)s_sbrk_fail_cnt);
        }

        size_t itcm_used  = (size_t)(_eitcm - _sitcm);
        size_t itcm_total = 16 * 1024;
        size_t itcm_pct   = itcm_used * 100 / itcm_total;
        printf("[SYSTEM] ITCM code used:     %u B / %u B (%u%%)\r\n",
               (unsigned)itcm_used, (unsigned)itcm_total, (unsigned)itcm_pct);
        printf("[SYSTEM] ITCM code free:     %u B\r\n",
               (unsigned)(itcm_total - itcm_used));

        printf("MQTT TX queue peak: %lu / 32\r\n", mqtt_tx_peak);
        printf("MQTT RX queue peak: %lu / 32\r\n", mqtt_rx_peak);
        printf("Output queue peak:  %lu / 64\r\n", output_peak);
        printf("USB queue peak:     %lu / 16\r\n", usb_peak);
        printf("Zbee cmd peak:      %lu / 64\r\n", zbee_cmd_peak);
        printf("Mongoose conns peak: %lu (cur=%lu)\r\n", mg_conn_peak, mg_conn_cur);
        printf("  Listeners=%lu  Broker clients=%lu  Ext MQTT client=%lu  TLS=%lu  Other(HTTP/DNS/NTP)=%lu\r\n",
               mg_conn_listeners, (unsigned long)mg_conn_mqttsrv, mg_conn_mqtt,
               mg_conn_tls, mg_conn_other_pure());
        printf("Mongoose gap peak:   %lu ms (starvation cnt: %lu)\r\n", mg_poll_gap_peak, (unsigned long)mg_poll_gap_over_50ms_cnt);
        printf("HTTP(s) Requests:   Total=%lu, API=%lu, Encoder=%lu\r\n",
               (unsigned long)req_total, (unsigned long)req_api, (unsigned long)req_encoder);
        printf("Net SYN drops:      %lu (RST after accept: %lu)\r\n",
               (unsigned long)g_net_syn_drops, (unsigned long)g_net_rejects);
        printf("=========================\r\n");

        last_free = current_free;
        last_min_ever = current_min;
        last_malloc_fail = current_malloc_fail;
        last_mqtt_tx_peak = mqtt_tx_peak;
        last_mqtt_rx_peak = mqtt_rx_peak;
        last_output_peak = output_peak;
        last_usb_peak = usb_peak;
        last_zbee_cmd_peak = zbee_cmd_peak;
        last_mg_conn_peak = mg_conn_peak;
        last_mg_conn_mqttsrv = mg_conn_mqttsrv;
        last_mg_poll_gap_peak = mg_poll_gap_peak;
        last_mg_poll_gap_over_50ms_cnt = mg_poll_gap_over_50ms_cnt;
        last_req_total = req_total;
        last_req_encoder = req_encoder;
        last_req_api = req_api;
        last_net_syn_drops = g_net_syn_drops;
        last_net_rejects = g_net_rejects;
    }
}

/* USER CODE END Header_StartDgnTask */
void StartDgnTask(void *argument)
{
  /* USER CODE BEGIN StartDgnTask */
  /* Немного ждём после загрузки, чтобы сеть успела подняться */
  osDelay(5000);

  /* Структура для динамического отслеживания минимума свободного стека (HWM) */
  struct
  {
      osThreadId_t *handle_ptr;
      const char *name;
      unsigned min_free_words;

  } tasks[] =
  {
      {&ConfigTaskHandle,    "ConfigTask",    0xFFFF},
      {&WebServerTaskHandle, "WebServerTask", 0xFFFF},
      {&OutputTaskHandle,    "OutputTask",    0xFFFF},
      {&CronTaskHandle,      "CronTask",      0xFFFF},
      {&InputTaskHandle,     "InputTask",     0xFFFF},
      {&EncoderTaskHandle,   "EncoderTask",   0xFFFF},
      {&ds18b20TaskHandle,   "ds18b20Task",   0xFFFF},
      {&dht22TaskHandle,     "dht22Task",     0xFFFF},
      {&ServiceTaskHandle,   "ServiceTask",   0xFFFF},
      {&SIM800LTaskHandle,   "SIM800LTask",   0xFFFF},
      {&SecurityTaskHandle,  "SecurityTask",  0xFFFF},
      {&PIDTaskHandle,       "PIDTask",       0xFFFF},
      {&my_DgnTaskHandle,    "DgnTask",       0xFFFF},
      {&LoggerTaskHandle,    "LoggerTask",    0xFFFF}

  };

  const size_t num_tasks = sizeof(tasks) / sizeof(tasks[0]);
  uint32_t last_full_report = xTaskGetTickCount();

  /* Infinite loop */
  for(;;)
  {
      /*
       * Ожидаем уведомления от других кусков кода (например HTTP/SMS)
       * с уменьшенным таймаутом 5000 мс (5 секунд), чтобы чаще проверять стеки под нагрузкой.
       */
      ulTaskNotifyTake(pdTRUE, pdMS_TO_TICKS(60000));// было 5000

      heap_diagnostic();

      /* Проверка целостности ITCM в рантайме (подстраховка для DMA).
       * MPU теперь ловит запись из CPU-кода мгновенно (MemManage Fault),
       * но DMA не проходит через MPU — эта проверка ловит DMA-порчу.
       * Без reset: если MPU не сработал, значит это DMA, и нужен лог
       * для диагностики, а не слепой ребут-цикл. */
      {
        uint32_t fi = 0, fe = 0, fg = 0;
        uint32_t itcm_errs = itcm_check_words(&fi, &fe, &fg);
        if (itcm_errs != 0) {
          printf("\r\n*** ITCM CORRUPTED (DMA?): %lu words, first @ITCM+0x%08lX (flash=0x%08lX itcm=0x%08lX) ***\r\n",
                 (unsigned long)itcm_errs, (unsigned long)(fi * 4u),
                 (unsigned long)fe, (unsigned long)fg);
          printf("*** MPU did not catch this — likely DMA wild write ***\r\n");
        }
      }

      int printed_header = 0;

		for (size_t i = 0; i < num_tasks; i++) {
			if (tasks[i].handle_ptr && *(tasks[i].handle_ptr)) {
				unsigned current_hwm = uxTaskGetStackHighWaterMark((TaskHandle_t) *(tasks[i].handle_ptr));

				if (current_hwm < tasks[i].min_free_words) {
					if (!printed_header) {
						printf("\r\n""=== STACK HWM UPDATE ===\r\n");
						printed_header = 1;
					}

					if (tasks[i].min_free_words == 0xFFFF) {
						printf("%-15s " "initial=%u words " "(%u bytes)\r\n", tasks[i].name, current_hwm,current_hwm * 4);
					} else {
						printf("%-15s " "%u -> %u words " "(%u bytes)\r\n",
						tasks[i].name,
						tasks[i].min_free_words,
						current_hwm,
						current_hwm * 4);
					}
					tasks[i].min_free_words = current_hwm;
				}
			}
		}

		if (printed_header) {
			printf("========================\r\n");
		}

		/*
		 * Полный отчёт раз в час
		 */
		if ((xTaskGetTickCount() - last_full_report) > pdMS_TO_TICKS(3600000)) {
			last_full_report = xTaskGetTickCount();

			printf("\r\n" "=== STACK WATERMARK ===\r\n");

			for (size_t i = 0; i < num_tasks; i++) {
				if (tasks[i].handle_ptr && *(tasks[i].handle_ptr)) {
					UBaseType_t hwm = uxTaskGetStackHighWaterMark((TaskHandle_t) *(tasks[i].handle_ptr));
					printf("%-15s %lu words " "(%lu bytes)\r\n", tasks[i].name, (uint32_t) hwm, (uint32_t) hwm * 4);
				}
			}

			printf("\r\n""=== HEAP ===\r\n");
			printf("Free bytes: %lu\r\n",
			(uint32_t) xPortGetFreeHeapSize());
			printf("Min ever: %lu\r\n",
			(uint32_t) xPortGetMinimumEverFreeHeapSize());
			printf("Malloc fail count: %lu\r\n", malloc_fail_count);

			{
				size_t dtcm_used  = dtcm_alloc_get_used();
				size_t dtcm_total = dtcm_alloc_get_total();
				size_t dtcm_pct   = dtcm_total ? (dtcm_used * 100 / dtcm_total) : 0;
				printf("\r\n""=== DTCM POOL ===\r\n");
				printf("Used:  %u B / %u B (%u%%)\r\n",
				       (unsigned)dtcm_used, (unsigned)dtcm_total, (unsigned)dtcm_pct);
				printf("Free:  %u B\r\n", (unsigned)dtcm_alloc_get_free());
				printf("Fails: %u\r\n", (unsigned)dtcm_alloc_get_fail_count());
			}

			{
				size_t itcm_used  = (size_t)(_eitcm - _sitcm);
				size_t itcm_total = 16 * 1024;
				size_t itcm_pct   = itcm_used * 100 / itcm_total;
				printf("\r\n""=== ITCM CODE ===\r\n");
				printf("Used:  %u B / %u B (%u%%)\r\n",
				       (unsigned)itcm_used, (unsigned)itcm_total, (unsigned)itcm_pct);
				printf("Free:  %u B\r\n", (unsigned)(itcm_total - itcm_used));
			}

			printf("\r\n""=== QUEUE PEAKS ===\r\n");
			printf("MQTT TX peak:  %lu / 32\r\n", mqtt_tx_peak);
			printf("MQTT RX peak:  %lu / 4\r\n", mqtt_rx_peak);
			printf("Output peak:   %lu / 16\r\n", output_peak);
			printf("USB peak:      %lu / 16\r\n", usb_peak);

			printf("\r\n""=== MONGOOSE PEAKS ===\r\n");
			printf("Conns peak:    %lu (cur=%lu)\r\n", mg_conn_peak, mg_conn_cur);
			printf("  Listeners=%lu  Broker clients=%lu  Ext MQTT client=%lu  TLS=%lu  Other(HTTP/DNS/NTP)=%lu\r\n",
			       mg_conn_listeners, (unsigned long)mg_conn_mqttsrv, mg_conn_mqtt,
			       mg_conn_tls, mg_conn_other_pure());
			printf("Poll gap peak: %lu ms (starvation cnt: %lu)\r\n", mg_poll_gap_peak, (unsigned long)mg_poll_gap_over_50ms_cnt);
			printf("Net SYN drops: %lu (RST after accept: %lu)\r\n",
			       (unsigned long)g_net_syn_drops, (unsigned long)g_net_rejects);

			printf("\r\n""=== RUNTIME ===\r\n");
			printf("Tick=%lu\r\n",
			(uint32_t) xTaskGetTickCount());
			printf("===================\r\n");
      }
  }
  /* USER CODE END StartDgnTask */
}

void StartLoggerTask(void *argument)
{
  /* USER CODE BEGIN StartLoggerTask */
    (void)argument;
    char rx_buf[192 + 16];
  /* Infinite loop */
  for(;;)
  {
      if (xMessageBuffer != NULL) {
          /* Если все категории отключены — не тратим CPU на приём и UART */
          if (g_log_filter_mask == 0) {
              /* Сливаем остатки сообщений, которые могли остаться в буфере */
              while (xMessageBufferReceive(xMessageBuffer, rx_buf, sizeof(rx_buf) - 1, 0) > 0) {}
              osDelay(200); /* спим 200ms, пользователь может включить фильтр в любой момент */
              continue;
          }

          size_t bytes_received = xMessageBufferReceive(xMessageBuffer, rx_buf, sizeof(rx_buf) - 1, portMAX_DELAY);
          if (bytes_received > 1) {
              LogCategory_t cat = (LogCategory_t)rx_buf[0];
              char *msg = rx_buf + 1;
              rx_buf[bytes_received] = '\0';

              if (cat < LOG_CAT_COUNT && (g_log_filter_mask & (1u << cat))) {
                  int prefix_len = strlen(cat_prefixes[cat]);
                  int msg_len = strlen(msg);
                  int total = prefix_len + msg_len;
                  /* Сборка в один буфер для одной неблокирующей передачи */
                  char tx_buf[256];
if (total < (int)sizeof(tx_buf)) {
                        memcpy(tx_buf, cat_prefixes[cat], prefix_len);
                        memcpy(tx_buf + prefix_len, msg, msg_len);
                        logger_ring_push(tx_buf, total); /* копия для веб-вьюера */
                        // Bounded timeout: 200ms хватает на ~2300 байт на 115200 bps
                        HAL_UART_Transmit(&huart3, (uint8_t*)tx_buf, total, 200);
                    }
              }
          }
      } else {
          osDelay(100);
      }
  }
  /* USER CODE END StartLoggerTask */
}

 /* MPU Configuration */

void MPU_Config(void)
{
  MPU_Region_InitTypeDef MPU_InitStruct = {0};

  /* Disables the MPU */
  HAL_MPU_Disable();

  /** Initializes and configures the Region and the memory to be protected
  */
  MPU_InitStruct.Enable = MPU_REGION_ENABLE;
  MPU_InitStruct.Number = MPU_REGION_NUMBER0;
  MPU_InitStruct.BaseAddress = 0x20000000;
  MPU_InitStruct.Size = MPU_REGION_SIZE_512KB;
  MPU_InitStruct.SubRegionDisable = 0x0;
  MPU_InitStruct.TypeExtField = MPU_TEX_LEVEL1;
  MPU_InitStruct.AccessPermission = MPU_REGION_FULL_ACCESS;
  MPU_InitStruct.DisableExec = MPU_INSTRUCTION_ACCESS_DISABLE;
  MPU_InitStruct.IsShareable = MPU_ACCESS_NOT_SHAREABLE;
  MPU_InitStruct.IsCacheable = MPU_ACCESS_NOT_CACHEABLE;
  MPU_InitStruct.IsBufferable = MPU_ACCESS_NOT_BUFFERABLE;

  HAL_MPU_ConfigRegion(&MPU_InitStruct);
  /* Enables the MPU */
  HAL_MPU_Enable(MPU_PRIVILEGED_DEFAULT);

}

void HAL_TIM_PeriodElapsedCallback(TIM_HandleTypeDef *htim)
{
  if (htim->Instance == TIM6) {
    HAL_IncTick();
  }
}

void Error_Handler(void)
{
  /* USER CODE BEGIN Error_Handler_Debug */
  /* Диагностика: кто вызвал Error_Handler? */
  __disable_irq();

  /* Прямой вывод в USART3 — без HAL (HAL может быть сломан) */
  volatile uint32_t *ISR = (volatile uint32_t *)(0x40004800 + 0x1C);
  volatile uint32_t *TDR = (volatile uint32_t *)(0x40004800 + 0x28);

  const char *msg = "\r\n\r\n!!! Error_Handler() called !!!\r\n  Caller LR = 0x";
  while (*msg) {
    volatile uint32_t t = 2000000;
    while (!((*ISR) & (1 << 7)) && --t) {}
    *TDR = (uint32_t)*msg++;
  }

  /* Выводим адрес вызывающей функции */
  uint32_t lr = (uint32_t)__builtin_return_address(0);
  const char hex[] = "0123456789ABCDEF";
  for (int i = 28; i >= 0; i -= 4) {
    volatile uint32_t t = 2000000;
    while (!((*ISR) & (1 << 7)) && --t) {}
    *TDR = (uint32_t)hex[(lr >> i) & 0xF];
  }

  const char *msg2 = "\r\n  Use: arm-none-eabi-addr2line -e firmware.elf 0x";
  while (*msg2) {
    volatile uint32_t t = 2000000;
    while (!((*ISR) & (1 << 7)) && --t) {}
    *TDR = (uint32_t)*msg2++;
  }
  for (int i = 28; i >= 0; i -= 4) {
    volatile uint32_t t = 2000000;
    while (!((*ISR) & (1 << 7)) && --t) {}
    *TDR = (uint32_t)hex[(lr >> i) & 0xF];
  }
  const char *msg3 = "\r\n  System halted. All 3 LEDs blink.\r\n";
  while (*msg3) {
    volatile uint32_t t = 2000000;
    while (!((*ISR) & (1 << 7)) && --t) {}
    *TDR = (uint32_t)*msg3++;
  }

  /* Мигание ВСЕХ 3 LED — паттерн Error_Handler */
  while (1) {
    HAL_GPIO_TogglePin(LD1_GPIO_Port, LD1_Pin);
    HAL_GPIO_TogglePin(LD2_GPIO_Port, LD2_Pin);
    HAL_GPIO_TogglePin(LD3_GPIO_Port, LD3_Pin);
    for(volatile uint32_t i = 0; i < 500000; i++);
  }
  /* USER CODE END Error_Handler_Debug */
}

#ifdef  USE_FULL_ASSERT
/**
  * @brief  Reports the name of the source file and the source line number
  *         where the assert_param error has occurred.
  * @param  file: pointer to the source file name
  * @param  line: assert_param error line source number
  * @retval None
  */
void assert_failed(uint8_t *file, uint32_t line)
{
  /* USER CODE BEGIN 6 */
  /* User can add his own implementation to report the file name and line
     number, ex: printf("Wrong parameters value: file %s on line %d\r\n", file,
     line) */
  /* USER CODE END 6 */
}
#endif /* USE_FULL_ASSERT */

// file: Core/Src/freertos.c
/* USER CODE BEGIN Header */
/**
  ******************************************************************************
  * File Name          : freertos.c
  * Description        : Code for freertos applications
  ******************************************************************************
  * @attention
  *
  * Copyright (c) 2024 STMicroelectronics.
  * All rights reserved.
  *
  * This software is licensed under terms that can be found in the LICENSE file
  * in the root directory of this software component.
  * If no LICENSE file comes with this software, it is provided AS-IS.
  *
  ******************************************************************************
  */
/* USER CODE END Header */

#include "FreeRTOS.h"
#include "task.h"
#include "main.h"

/* USER CODE BEGIN Application */

/* ═══════════════════════════════════════════════════════════════════════
 *  Stack Overflow Hook — вызывается FreeRTOS при обнаружении переполнения.
 *  Использует прямой вывод в USART3 (без HAL, без printf — они могут быть
 *  недоступны при повреждённом стеке).
 * ═══════════════════════════════════════════════════════════════════════ */
static void sof_putchar(char c) {
  volatile uint32_t *ISR = (volatile uint32_t *)(0x40004800 + 0x1C);
  volatile uint32_t *TDR = (volatile uint32_t *)(0x40004800 + 0x28);
  volatile uint32_t t = 2000000;
  while (!((*ISR) & (1 << 7)) && --t) {}
  *TDR = (uint32_t)c;
}

static void sof_puts(const char *s) {
  while (*s) {
    if (*s == '\n') sof_putchar('\r');
    sof_putchar(*s++);
  }
}

void vApplicationStackOverflowHook(TaskHandle_t xTask, signed char *pcTaskName) {
  (void)xTask;

  sof_puts("\n\n");
  sof_puts("!!!!!!!!!!!!!!!!!!!!!!!!!!!!!!!!!!!!!!!!!!!!!!!!\n");
  sof_puts("!!! STACK OVERFLOW DETECTED by FreeRTOS !!!\n");
  sof_puts("!!!!!!!!!!!!!!!!!!!!!!!!!!!!!!!!!!!!!!!!!!!!!!!!\n");
  sof_puts("  Task: ");

  /* Безопасный вывод имени задачи (макс 16 символов) */
  if (pcTaskName != NULL &&
      (uint32_t)pcTaskName >= 0x20000000 &&
      (uint32_t)pcTaskName < 0x20080000) {
    for (int i = 0; i < 16 && pcTaskName[i] != '\0'; i++) {
      char c = pcTaskName[i];
      if (c >= 0x20 && c <= 0x7E)
        sof_putchar(c);
      else
        sof_putchar('?');
    }
  } else {
    sof_puts("<corrupted>");
  }

  sof_puts("\n\n");
  sof_puts("  SOLUTION: increase .stack_size for this task in main.c\n");
  sof_puts("  System halted. Red+Green LEDs alternate.\n\n");

  __disable_irq();
  while (1) {
    /* Красный и зелёный мигают поочерёдно — уникальный паттерн Stack Overflow */
    HAL_GPIO_TogglePin(LD1_GPIO_Port, LD1_Pin);
    HAL_GPIO_TogglePin(LD3_GPIO_Port, LD3_Pin);
    for(volatile uint32_t i = 0; i < 300000; i++);
    HAL_GPIO_TogglePin(LD1_GPIO_Port, LD1_Pin);
    HAL_GPIO_TogglePin(LD3_GPIO_Port, LD3_Pin);
    for(volatile uint32_t i = 0; i < 300000; i++);
  }
}

/* USER CODE END Application */
